VERSION ""

NS_ :

BS_:

BU_: CHUD_LS VKM_LS RCRM_LS MSM_RR_LS MSM_LR_LS CGM_LS BSM_LS VPM_LS ISRVM_LS DCAC_LS TouchPad_LS RSC_LS LVMPC_LS EOCM2B_K1_LS EOCM2A_K1_LS LCM_LS TIM_B_LS V2V_LS TCP_LS CSM_LS EOCM2B_K2_LS EOCM2A_K2_LS TIM_A_LS LVMNav_LS HFP_LS EDI_LS ARB_LS RSE_LS Dummy_LS VIS2_LS ICS_LS FCM_LS EOCM_F_LS VICM_LS AGC_LS MSM_P_LS OTIM_LS HVSM_R_LS HVSM_F_LS DVB_T_LS SBZA_R_LS PSD_R_LS PSD_L_LS UHP_Low UPA_LS STC_LS SBZA_L_LS PTM_LS ONSTAR_LS APA_LS TestTool_LS PHS_LS PDIM_LS CHM_LS RSA_LS AMP_LS HUD_LS MSM_LS HBSM_LS SCL_LS ECC_LS RadioHead_LS PEPS_LS IPC_LS AOS_LS SDM_LS TIM_LS BCM_LS

BO_ 2154905600 Driver_Identifier_LS: 1 BCM_LS
 SG_ DrvSeatPrsMemID : 5|3@0+ (1,0) [0|7] ""  CSM_LS,ONSTAR_LS,EOCM2B_K2_LS,EOCM2A_K2_LS,CGM_LS,EDI_LS,IPC_LS,CHUD_LS,HUD_LS,MSM_P_LS,MSM_LS
 SG_ DrId : 2|3@0+ (1,0) [0|7] ""  TCP_LS,EOCM2B_K2_LS,EOCM2A_K2_LS,CGM_LS,VIS2_LS,EDI_LS,LVMNav_LS,FCM_LS,EOCM_F_LS,ONSTAR_LS,CSM_LS,RadioHead_LS,ECC_LS,IPC_LS,MSM_P_LS,MSM_LS

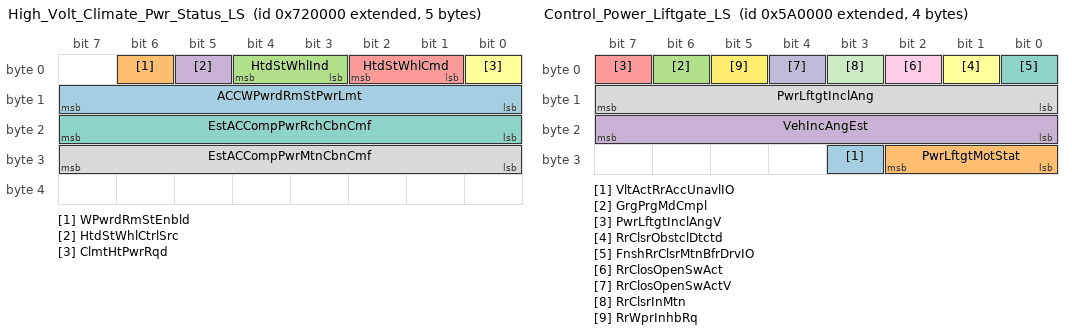
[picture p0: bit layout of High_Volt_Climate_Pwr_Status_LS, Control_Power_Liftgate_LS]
BO_ 2154954752 High_Volt_Climate_Pwr_Status_LS: 5 ECC_LS
 SG_ ACCWPwrdRmStPwrLmt : 15|8@0+ (0.1,0) [0|25.5] "kW"  VICM_LS,CGM_LS
 SG_ WPwrdRmStEnbld : 6|1@0+ (1,0) [0|1] ""  VICM_LS,CGM_LS
 SG_ HtdStWhlInd : 4|2@0+ (1,0) [0|3] ""  CGM_LS,EOCM2B_K2_LS
 SG_ HtdStWhlCtrlSrc : 5|1@0+ (1,0) [0|1] ""  CGM_LS,EOCM2B_K2_LS
 SG_ HtdStWhlCmd : 2|2@0+ (1,0) [0|3] ""  CGM_LS,EOCM2B_K2_LS
 SG_ ClmtHtPwrRqd : 0|1@0+ (1,0) [0|1] ""  CGM_LS,VICM_LS
 SG_ EstACCompPwrRchCbnCmf : 23|8@0+ (0.04,0) [0|10.2] "kw"  CGM_LS,BSM_LS,VICM_LS,CSM_LS,RadioHead_LS
 SG_ EstACCompPwrMtnCbnCmf : 31|8@0+ (0.04,0) [0|10.2] "kW"  CGM_LS,BSM_LS,VICM_LS,CSM_LS,RadioHead_LS

BO_ 2153381888 Control_Power_Liftgate_LS: 4 PTM_LS
 SG_ VltActRrAccUnavlIO : 27|1@0+ (1,0) [0|1] ""  CGM_LS,IPC_LS
 SG_ PwrLftgtMotStat : 26|3@0+ (1,0) [0|7] ""  CSM_LS,IPC_LS,CGM_LS,RadioHead_LS,ECC_LS,Dummy_LS
 SG_ GrgPrgMdCmpl : 6|1@0+ (1,0) [0|1] ""  CSM_LS,CGM_LS,RadioHead_LS,BCM_LS
 SG_ VehIncAngEst : 23|8@0+ (1,0) [0|255] "deg"  CSM_LS,CGM_LS,RadioHead_LS,PSD_R_LS,PSD_L_LS
 SG_ PwrLftgtInclAngV : 7|1@0+ (1,0) [0|1] ""  CSM_LS,CGM_LS,RadioHead_LS,TIM_B_LS,TIM_A_LS,TIM_LS
 SG_ RrClsrObstclDtctd : 1|1@0+ (1,0) [0|1] ""  CSM_LS,CGM_LS,RadioHead_LS,BCM_LS
 SG_ FnshRrClsrMtnBfrDrvIO : 0|1@0+ (1,0) [0|1] ""  CSM_LS,CGM_LS,RadioHead_LS,IPC_LS
 SG_ PwrLftgtInclAng : 15|8@0+ (1,0) [0|255] ""  CSM_LS,CGM_LS,RadioHead_LS,TIM_B_LS,TIM_A_LS,TIM_LS
 SG_ RrClosOpenSwAct : 2|1@0+ (1,0) [0|1] ""  VKM_LS,CSM_LS,CGM_LS,ARB_LS,RadioHead_LS,IPC_LS,BCM_LS
 SG_ RrClosOpenSwActV : 4|1@0+ (1,0) [0|1] ""  CSM_LS,CGM_LS,ARB_LS,RadioHead_LS,IPC_LS,BCM_LS
 SG_ RrClsrInMtn : 3|1@0+ (1,0) [0|1] ""  CSM_LS,CGM_LS,RadioHead_LS,BCM_LS
 SG_ RrWprInhbRq : 5|1@0+ (1,0) [0|1] ""  CSM_LS,CGM_LS,RadioHead_LS,BCM_LS

BO_ 2149752832 Chassis_Information_LS: 8 BCM_LS
 SG_ SndEnhcmtPerfMdRq : 55|3@0+ (1,0) [0|7] ""  CSM_LS,CGM_LS,RadioHead_LS,IPC_LS
 SG_ SndPerfMdCsStAvl : 63|1@0+ (1,0) [0|1] ""  CGM_LS,CSM_LS,RadioHead_LS
 SG_ SndPerfMdCsCrStVal : 62|3@0+ (1,0) [0|7] ""  CGM_LS,CSM_LS,RadioHead_LS
 SG_ DispPerfMdCsStAvl : 59|1@0+ (1,0) [0|1] ""  CGM_LS,CSM_LS,RadioHead_LS
 SG_ DispPerfMdCsCrStVal : 58|3@0+ (1,0) [0|7] ""  CGM_LS,CSM_LS,RadioHead_LS
 SG_ HlStrAssActIO : 41|1@0+ (1,0) [0|1] ""  CSM_LS,CGM_LS,RadioHead_LS,IPC_LS
 SG_ GNCustSetngAvlbl : 44|1@0+ (1,0) [0|1] ""  CGM_LS,IPC_LS,CSM_LS,RadioHead_LS
 SG_ GNCustCrntStngVal : 47|3@0+ (1,0) [0|7] ""  CGM_LS,IPC_LS,CSM_LS,RadioHead_LS
 SG_ CPSInfotmntMtReq : 49|2@0+ (1,0) [0|3] ""  CSM_LS,CGM_LS,RadioHead_LS
 SG_ ColPrSysStngAvl : 42|1@0+ (1,0) [0|1] ""  CGM_LS,CSM_LS,RadioHead_LS
 SG_ ColPrSysCrntStng : 52|3@0+ (1,0) [0|7] ""  CGM_LS,CSM_LS,RadioHead_LS
 SG_ HillDscntCntlSysStat : 37|3@0+ (1,0) [0|7] ""  CSM_LS,CGM_LS,RadioHead_LS,IPC_LS
 SG_ ElecPrkBrkStat : 39|2@0+ (1,0) [0|3] ""  ONSTAR_LS,TCP_LS,CSM_LS,MSM_P_LS,MSM_LS,V2V_LS,CGM_LS,RadioHead_LS,SBZA_R_LS,SBZA_L_LS,LVMNav_LS,UPA_LS,APA_LS
 SG_ EBDFailed : 31|1@0+ (1,0) [0|1] ""  CSM_LS,CGM_LS,RadioHead_LS,IPC_LS
 SG_ SusCustStngAvlbl : 30|1@0+ (1,0) [0|1] ""  CGM_LS,CSM_LS,RadioHead_LS
 SG_ SusCustCurrStngVal : 34|3@0+ (1,0) [0|7] ""  CGM_LS,CSM_LS,RadioHead_LS
 SG_ StrCustStngAvlbl : 7|1@0+ (1,0) [0|1] ""  CGM_LS,CSM_LS,RadioHead_LS
 SG_ StrCustCurrStngVal : 29|3@0+ (1,0) [0|7] ""  CGM_LS,CSM_LS,RadioHead_LS
 SG_ DrvlnCustStngAvlbl : 6|1@0+ (1,0) [0|1] ""  CGM_LS,CSM_LS,RadioHead_LS
 SG_ DrvlnCustCurrStngVal : 26|3@0+ (1,0) [0|7] ""  CGM_LS,CSM_LS,RadioHead_LS
 SG_ ABSAtv : 5|1@0+ (1,0) [0|1] ""  CSM_LS,CGM_LS,SDM_LS,VIS2_LS,RadioHead_LS,FCM_LS,IPC_LS,UPA_LS,APA_LS
 SG_ PowStVDA : 13|1@0+ (1,0) [0|1] ""  CGM_LS,CSM_LS,RadioHead_LS,IPC_LS
 SG_ RrDrCntVDA : 14|1@0+ (1,0) [0|1] ""  CGM_LS,CSM_LS,IPC_LS,RadioHead_LS
 SG_ SprTireSt : 18|3@0+ (1,0) [0|7] ""  VPM_LS,CSM_LS,CGM_LS,RadioHead_LS,UPA_LS,APA_LS
 SG_ VehHghtStatV : 0|1@0+ (1,0) [0|1] ""  VPM_LS,CSM_LS,CGM_LS,RadioHead_LS,IPC_LS
 SG_ VehHghtStat : 11|4@0+ (1,0) [0|15] ""  VPM_LS,CSM_LS,CGM_LS,RadioHead_LS,IPC_LS
 SG_ BrkSysVDA : 15|1@0+ (1,0) [0|1] ""  TCP_LS,CGM_LS,CSM_LS,VIS2_LS,LCM_LS,PTM_LS,ONSTAR_LS,FCM_LS,RadioHead_LS,UPA_LS,APA_LS,IPC_LS
 SG_ IntBrkAssPreFilReq : 1|1@0+ (1,0) [0|1] "N/A"  CSM_LS,CGM_LS,RadioHead_LS,IPC_LS
 SG_ EPBSysDspMsgReq : 23|3@0+ (1,0) [0|7] ""  CSM_LS,CGM_LS,RadioHead_LS,IPC_LS
 SG_ EPBSysAudWarnReq : 20|2@0+ (1,0) [0|3] ""  CSM_LS,CGM_LS,RadioHead_LS,IPC_LS
 SG_ BksOvht : 2|1@0+ (1,0) [0|1] ""  CSM_LS,TCP_LS,CGM_LS,RadioHead_LS,ONSTAR_LS,IPC_LS
 SG_ BrkSysRedBrkTlltlReq : 4|1@0+ (1,0) [0|1] ""  CSM_LS,CGM_LS,RadioHead_LS,IPC_LS
 SG_ HalfSysFail : 3|1@0+ (1,0) [0|1] ""  CSM_LS,CGM_LS,RadioHead_LS,IPC_LS
 SG_ PrkBrkVDA : 12|1@0+ (1,0) [0|1] ""  CGM_LS,CSM_LS,RadioHead_LS,IPC_LS,UPA_LS,APA_LS

BO_ 2151514112 Reset_OilLife_Request_LS: 1 IPC_LS
 SG_ EngOilLfRstRq : 0|1@0+ (1,0) [0|1] ""  BCM_LS

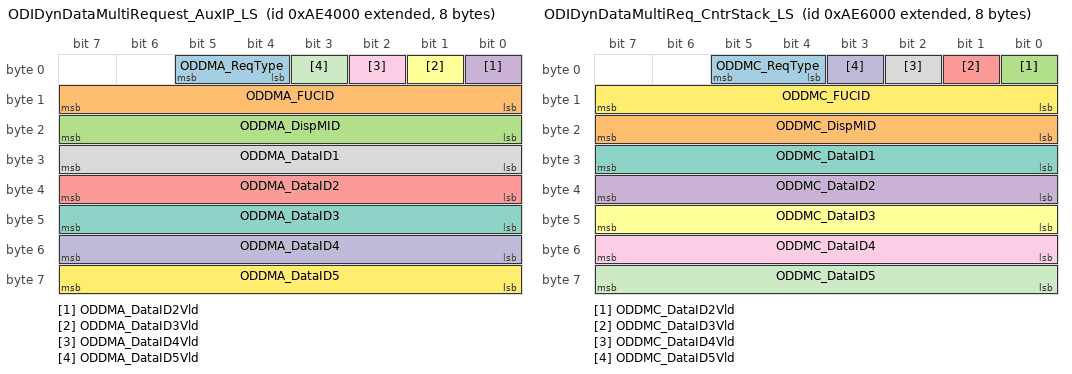
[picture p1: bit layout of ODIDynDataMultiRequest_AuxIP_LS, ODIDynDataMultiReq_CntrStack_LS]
BO_ 2158903296 ODIDynDataMultiRequest_AuxIP_LS: 8 CGM_LS
 SG_ ODDMA_ReqType : 5|2@0+ (1,0) [0|3] ""  EOCM2B_K2_LS,EOCM2A_K2_LS,SBZA_L_LS,VIS2_LS,FCM_LS,EOCM_F_LS,UPA_LS,BCM_LS,IPC_LS,ECC_LS,MSM_P_LS,MSM_LS,APA_LS,RadioHead_LS,UHP_Low,ONSTAR_LS
 SG_ ODDMA_FUCID : 15|8@0+ (1,0) [0|255] ""  EOCM2B_K2_LS,EOCM2A_K2_LS,SBZA_L_LS,VIS2_LS,FCM_LS,EOCM_F_LS,UPA_LS,BCM_LS,IPC_LS,ECC_LS,MSM_P_LS,MSM_LS,APA_LS,RadioHead_LS,UHP_Low,ONSTAR_LS
 SG_ ODDMA_DispMID : 23|8@0+ (1,0) [0|255] ""  EOCM2B_K2_LS,EOCM2A_K2_LS,SBZA_L_LS,VIS2_LS,FCM_LS,EOCM_F_LS,UPA_LS,BCM_LS,IPC_LS,ECC_LS,MSM_P_LS,MSM_LS,APA_LS,RadioHead_LS,UHP_Low,ONSTAR_LS
 SG_ ODDMA_DataID2Vld : 0|1@0+ (1,0) [0|1] ""  EOCM2B_K2_LS,EOCM2A_K2_LS,SBZA_L_LS,VIS2_LS,FCM_LS,EOCM_F_LS,UPA_LS,BCM_LS,IPC_LS,ECC_LS,MSM_P_LS,MSM_LS,APA_LS,RadioHead_LS,UHP_Low,ONSTAR_LS
 SG_ ODDMA_DataID2 : 39|8@0+ (1,0) [0|255] ""  EOCM2B_K2_LS,EOCM2A_K2_LS,SBZA_L_LS,VIS2_LS,FCM_LS,EOCM_F_LS,UPA_LS,BCM_LS,IPC_LS,ECC_LS,MSM_P_LS,MSM_LS,APA_LS,RadioHead_LS,UHP_Low,ONSTAR_LS
 SG_ ODDMA_DataID3Vld : 1|1@0+ (1,0) [0|1] ""  EOCM2B_K2_LS,EOCM2A_K2_LS,SBZA_L_LS,VIS2_LS,FCM_LS,EOCM_F_LS,UPA_LS,BCM_LS,IPC_LS,ECC_LS,MSM_P_LS,MSM_LS,APA_LS,RadioHead_LS,UHP_Low,ONSTAR_LS
 SG_ ODDMA_DataID3 : 47|8@0+ (1,0) [0|255] ""  EOCM2B_K2_LS,EOCM2A_K2_LS,SBZA_L_LS,VIS2_LS,FCM_LS,EOCM_F_LS,UPA_LS,BCM_LS,IPC_LS,ECC_LS,MSM_P_LS,MSM_LS,APA_LS,RadioHead_LS,UHP_Low,ONSTAR_LS
 SG_ ODDMA_DataID1 : 31|8@0+ (1,0) [0|255] ""  EOCM2B_K2_LS,EOCM2A_K2_LS,SBZA_L_LS,VIS2_LS,FCM_LS,EOCM_F_LS,UPA_LS,BCM_LS,IPC_LS,ECC_LS,MSM_P_LS,MSM_LS,APA_LS,RadioHead_LS,UHP_Low,ONSTAR_LS
 SG_ ODDMA_DataID4Vld : 2|1@0+ (1,0) [0|1] ""  EOCM2B_K2_LS,EOCM2A_K2_LS,SBZA_L_LS,VIS2_LS,FCM_LS,EOCM_F_LS,UPA_LS,BCM_LS,IPC_LS,ECC_LS,MSM_P_LS,MSM_LS,APA_LS,RadioHead_LS,UHP_Low,ONSTAR_LS
 SG_ ODDMA_DataID4 : 55|8@0+ (1,0) [0|255] ""  EOCM2B_K2_LS,EOCM2A_K2_LS,SBZA_L_LS,VIS2_LS,FCM_LS,EOCM_F_LS,UPA_LS,BCM_LS,IPC_LS,ECC_LS,MSM_P_LS,MSM_LS,APA_LS,RadioHead_LS,UHP_Low,ONSTAR_LS
 SG_ ODDMA_DataID5Vld : 3|1@0+ (1,0) [0|1] ""  EOCM2B_K2_LS,EOCM2A_K2_LS,SBZA_L_LS,VIS2_LS,FCM_LS,EOCM_F_LS,UPA_LS,BCM_LS,IPC_LS,ECC_LS,MSM_P_LS,MSM_LS,APA_LS,RadioHead_LS,UHP_Low,ONSTAR_LS
 SG_ ODDMA_DataID5 : 63|8@0+ (1,0) [0|255] ""  EOCM2B_K2_LS,EOCM2A_K2_LS,SBZA_L_LS,VIS2_LS,FCM_LS,EOCM_F_LS,UPA_LS,BCM_LS,IPC_LS,ECC_LS,MSM_P_LS,MSM_LS,APA_LS,RadioHead_LS,UHP_Low,ONSTAR_LS

BO_ 2158911488 ODIDynDataMultiReq_CntrStack_LS: 8 CGM_LS
 SG_ ODDMC_ReqType : 5|2@0+ (1,0) [0|3] ""  EOCM2B_K2_LS,EOCM2A_K2_LS,TCP_LS,SBZA_L_LS,VIS2_LS,FCM_LS,PDIM_LS,EOCM_F_LS,UPA_LS,BCM_LS,ECC_LS,MSM_P_LS,MSM_LS,APA_LS,UHP_Low,ONSTAR_LS
 SG_ ODDMC_DispMID : 23|8@0+ (1,0) [0|255] ""  EOCM2B_K2_LS,EOCM2A_K2_LS,TCP_LS,SBZA_L_LS,VIS2_LS,FCM_LS,PDIM_LS,EOCM_F_LS,UPA_LS,BCM_LS,ECC_LS,MSM_P_LS,MSM_LS,APA_LS,UHP_Low,ONSTAR_LS
 SG_ ODDMC_DataID2Vld : 0|1@0+ (1,0) [0|1] ""  EOCM2B_K2_LS,EOCM2A_K2_LS,TCP_LS,SBZA_L_LS,VIS2_LS,FCM_LS,PDIM_LS,EOCM_F_LS,UPA_LS,BCM_LS,ECC_LS,MSM_P_LS,MSM_LS,APA_LS,UHP_Low,ONSTAR_LS
 SG_ ODDMC_DataID2 : 39|8@0+ (1,0) [0|255] ""  EOCM2B_K2_LS,EOCM2A_K2_LS,TCP_LS,SBZA_L_LS,VIS2_LS,FCM_LS,PDIM_LS,EOCM_F_LS,UPA_LS,BCM_LS,ECC_LS,MSM_P_LS,MSM_LS,APA_LS,UHP_Low,ONSTAR_LS
 SG_ ODDMC_DataID3Vld : 1|1@0+ (1,0) [0|1] ""  EOCM2B_K2_LS,EOCM2A_K2_LS,TCP_LS,SBZA_L_LS,VIS2_LS,FCM_LS,PDIM_LS,EOCM_F_LS,UPA_LS,BCM_LS,ECC_LS,MSM_P_LS,MSM_LS,APA_LS,UHP_Low,ONSTAR_LS
 SG_ ODDMC_DataID3 : 47|8@0+ (1,0) [0|255] ""  EOCM2B_K2_LS,EOCM2A_K2_LS,TCP_LS,SBZA_L_LS,VIS2_LS,FCM_LS,PDIM_LS,EOCM_F_LS,UPA_LS,BCM_LS,ECC_LS,MSM_P_LS,MSM_LS,APA_LS,UHP_Low,ONSTAR_LS
 SG_ ODDMC_DataID1 : 31|8@0+ (1,0) [0|255] ""  EOCM2B_K2_LS,EOCM2A_K2_LS,TCP_LS,SBZA_L_LS,VIS2_LS,FCM_LS,PDIM_LS,EOCM_F_LS,UPA_LS,BCM_LS,ECC_LS,MSM_P_LS,MSM_LS,APA_LS,UHP_Low,ONSTAR_LS
 SG_ ODDMC_DataID4Vld : 2|1@0+ (1,0) [0|1] ""  EOCM2B_K2_LS,EOCM2A_K2_LS,TCP_LS,SBZA_L_LS,VIS2_LS,FCM_LS,PDIM_LS,EOCM_F_LS,UPA_LS,BCM_LS,ECC_LS,MSM_P_LS,MSM_LS,APA_LS,UHP_Low,ONSTAR_LS
 SG_ ODDMC_DataID4 : 55|8@0+ (1,0) [0|255] ""  EOCM2B_K2_LS,EOCM2A_K2_LS,TCP_LS,SBZA_L_LS,VIS2_LS,FCM_LS,PDIM_LS,EOCM_F_LS,UPA_LS,BCM_LS,ECC_LS,MSM_P_LS,MSM_LS,APA_LS,UHP_Low,ONSTAR_LS
 SG_ ODDMC_DataID5Vld : 3|1@0+ (1,0) [0|1] ""  EOCM2B_K2_LS,EOCM2A_K2_LS,TCP_LS,SBZA_L_LS,VIS2_LS,FCM_LS,PDIM_LS,EOCM_F_LS,UPA_LS,BCM_LS,ECC_LS,MSM_P_LS,MSM_LS,APA_LS,UHP_Low,ONSTAR_LS
 SG_ ODDMC_DataID5 : 63|8@0+ (1,0) [0|255] ""  EOCM2B_K2_LS,EOCM2A_K2_LS,TCP_LS,SBZA_L_LS,VIS2_LS,FCM_LS,PDIM_LS,EOCM_F_LS,UPA_LS,BCM_LS,ECC_LS,MSM_P_LS,MSM_LS,APA_LS,UHP_Low,ONSTAR_LS
 SG_ ODDMC_FUCID : 15|8@0+ (1,0) [0|255] ""  EOCM2B_K2_LS,EOCM2A_K2_LS,TCP_LS,SBZA_L_LS,VIS2_LS,FCM_LS,PDIM_LS,EOCM_F_LS,UPA_LS,BCM_LS,ECC_LS,MSM_P_LS,MSM_LS,APA_LS,UHP_Low,ONSTAR_LS

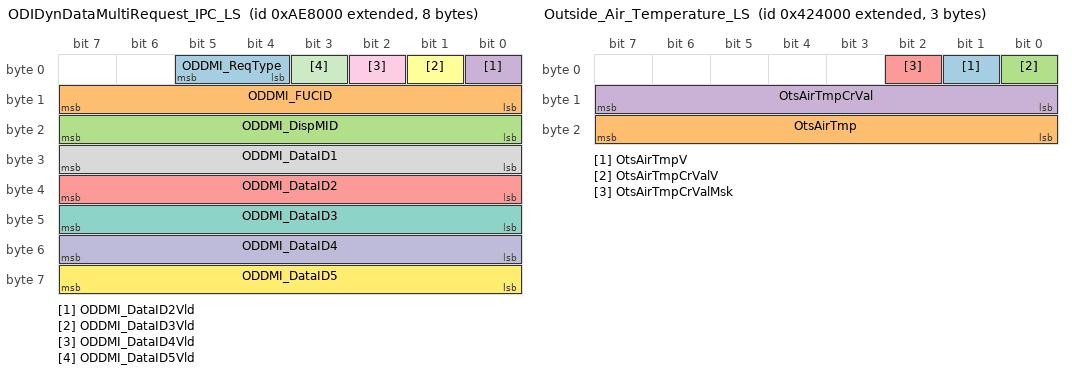
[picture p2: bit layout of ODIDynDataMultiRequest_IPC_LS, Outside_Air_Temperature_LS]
BO_ 2158919680 ODIDynDataMultiRequest_IPC_LS: 8 CGM_LS
 SG_ ODDMI_ReqType : 5|2@0+ (1,0) [0|3] ""  EOCM2B_K2_LS,EOCM2A_K2_LS,TCP_LS,SBZA_L_LS,VIS2_LS,FCM_LS,EOCM_F_LS,UPA_LS,BCM_LS,ECC_LS,MSM_P_LS,MSM_LS,APA_LS,RadioHead_LS,UHP_Low,ONSTAR_LS
 SG_ ODDMI_FUCID : 15|8@0+ (1,0) [0|255] ""  EOCM2B_K2_LS,EOCM2A_K2_LS,TCP_LS,SBZA_L_LS,VIS2_LS,FCM_LS,EOCM_F_LS,UPA_LS,BCM_LS,ECC_LS,MSM_P_LS,MSM_LS,APA_LS,RadioHead_LS,UHP_Low,ONSTAR_LS
 SG_ ODDMI_DispMID : 23|8@0+ (1,0) [0|255] ""  EOCM2B_K2_LS,EOCM2A_K2_LS,TCP_LS,SBZA_L_LS,VIS2_LS,FCM_LS,EOCM_F_LS,UPA_LS,BCM_LS,ECC_LS,MSM_P_LS,MSM_LS,APA_LS,RadioHead_LS,UHP_Low,ONSTAR_LS
 SG_ ODDMI_DataID2Vld : 0|1@0+ (1,0) [0|1] ""  EOCM2B_K2_LS,EOCM2A_K2_LS,TCP_LS,SBZA_L_LS,VIS2_LS,FCM_LS,EOCM_F_LS,UPA_LS,BCM_LS,ECC_LS,MSM_P_LS,MSM_LS,APA_LS,RadioHead_LS,UHP_Low,ONSTAR_LS
 SG_ ODDMI_DataID2 : 39|8@0+ (1,0) [0|255] ""  EOCM2B_K2_LS,EOCM2A_K2_LS,TCP_LS,SBZA_L_LS,VIS2_LS,FCM_LS,EOCM_F_LS,UPA_LS,BCM_LS,ECC_LS,MSM_P_LS,MSM_LS,APA_LS,RadioHead_LS,UHP_Low,ONSTAR_LS
 SG_ ODDMI_DataID3Vld : 1|1@0+ (1,0) [0|1] ""  EOCM2B_K2_LS,EOCM2A_K2_LS,TCP_LS,SBZA_L_LS,VIS2_LS,FCM_LS,EOCM_F_LS,UPA_LS,BCM_LS,ECC_LS,MSM_P_LS,MSM_LS,APA_LS,RadioHead_LS,UHP_Low,ONSTAR_LS
 SG_ ODDMI_DataID3 : 47|8@0+ (1,0) [0|255] ""  EOCM2B_K2_LS,EOCM2A_K2_LS,TCP_LS,SBZA_L_LS,VIS2_LS,FCM_LS,EOCM_F_LS,UPA_LS,BCM_LS,ECC_LS,MSM_P_LS,MSM_LS,APA_LS,RadioHead_LS,UHP_Low,ONSTAR_LS
 SG_ ODDMI_DataID1 : 31|8@0+ (1,0) [0|255] ""  EOCM2B_K2_LS,EOCM2A_K2_LS,TCP_LS,SBZA_L_LS,VIS2_LS,FCM_LS,EOCM_F_LS,UPA_LS,BCM_LS,ECC_LS,MSM_P_LS,MSM_LS,APA_LS,RadioHead_LS,UHP_Low,ONSTAR_LS
 SG_ ODDMI_DataID4Vld : 2|1@0+ (1,0) [0|1] ""  EOCM2B_K2_LS,EOCM2A_K2_LS,TCP_LS,SBZA_L_LS,VIS2_LS,FCM_LS,EOCM_F_LS,UPA_LS,BCM_LS,ECC_LS,MSM_P_LS,MSM_LS,APA_LS,RadioHead_LS,UHP_Low,ONSTAR_LS
 SG_ ODDMI_DataID4 : 55|8@0+ (1,0) [0|255] ""  EOCM2B_K2_LS,EOCM2A_K2_LS,TCP_LS,SBZA_L_LS,VIS2_LS,FCM_LS,EOCM_F_LS,UPA_LS,BCM_LS,ECC_LS,MSM_P_LS,MSM_LS,APA_LS,RadioHead_LS,UHP_Low,ONSTAR_LS
 SG_ ODDMI_DataID5Vld : 3|1@0+ (1,0) [0|1] ""  EOCM2B_K2_LS,EOCM2A_K2_LS,TCP_LS,SBZA_L_LS,VIS2_LS,FCM_LS,EOCM_F_LS,UPA_LS,BCM_LS,ECC_LS,MSM_P_LS,MSM_LS,APA_LS,RadioHead_LS,UHP_Low,ONSTAR_LS
 SG_ ODDMI_DataID5 : 63|8@0+ (1,0) [0|255] ""  EOCM2B_K2_LS,EOCM2A_K2_LS,TCP_LS,SBZA_L_LS,VIS2_LS,FCM_LS,EOCM_F_LS,UPA_LS,BCM_LS,ECC_LS,MSM_P_LS,MSM_LS,APA_LS,RadioHead_LS,UHP_Low,ONSTAR_LS

BO_ 2151825408 Outside_Air_Temperature_LS: 3 IPC_LS
 SG_ OtsAirTmpV : 1|1@0+ (1,0) [0|1] ""  LVMPC_LS,EOCM2B_K1_LS,EOCM2A_K1_LS,RSE_LS,EOCM2A_K2_LS,EOCM2B_K2_LS,EOCM_F_LS,LVMNav_LS,HFP_LS,EDI_LS,RadioHead_LS,CGM_LS,UPA_LS,BCM_LS,APA_LS,PHS_LS,ECC_LS
 SG_ OtsAirTmp : 23|8@0+ (0.5,-40) [-40|87.5] "deg C"  LVMPC_LS,EOCM2B_K1_LS,EOCM2A_K1_LS,RSE_LS,EOCM2A_K2_LS,EOCM2B_K2_LS,EOCM_F_LS,LVMNav_LS,HFP_LS,EDI_LS,RadioHead_LS,CGM_LS,UPA_LS,ICS_LS,BCM_LS,APA_LS,PHS_LS,ECC_LS
 SG_ OtsAirTmpCrValV : 0|1@0+ (1,0) [0|1] ""  EOCM2B_K1_LS,EOCM2A_K1_LS,EOCM2A_K2_LS,EOCM2B_K2_LS,EOCM_F_LS,VIS2_LS,LVMNav_LS,EDI_LS,ARB_LS,CGM_LS,SDM_LS,PSD_R_LS,PSD_L_LS,FCM_LS,RadioHead_LS,UPA_LS,APA_LS,LCM_LS,PTM_LS,BCM_LS,ECC_LS
 SG_ OtsAirTmpCrVal : 15|8@0+ (0.5,-40) [-40|87.5] "deg C"  EOCM2B_K1_LS,EOCM2A_K1_LS,EOCM2A_K2_LS,EOCM2B_K2_LS,EOCM_F_LS,VIS2_LS,LVMNav_LS,EDI_LS,ARB_LS,CGM_LS,SDM_LS,PSD_R_LS,PSD_L_LS,FCM_LS,RadioHead_LS,LCM_LS,PTM_LS,BCM_LS,UPA_LS,APA_LS,ECC_LS
 SG_ OtsAirTmpCrValMsk : 2|1@0+ (1,0) [0|1] ""  EOCM2B_K1_LS,EOCM2A_K1_LS,EOCM2A_K2_LS,EOCM2B_K2_LS,EOCM_F_LS,VIS2_LS,RadioHead_LS,LVMNav_LS,ARB_LS,EDI_LS,CGM_LS,SDM_LS,PSD_R_LS,PSD_L_LS,UPA_LS,APA_LS,BCM_LS,LCM_LS,PTM_LS,ECC_LS,FCM_LS

BO_ 2151153664 Rear_Window_Defog_Status_LS: 1 ECC_LS
 SG_ RrWndDfgOn : 0|1@0+ (1,0) [0|1] ""  CGM_LS,CSM_LS,RadioHead_LS,IPC_LS,BCM_LS

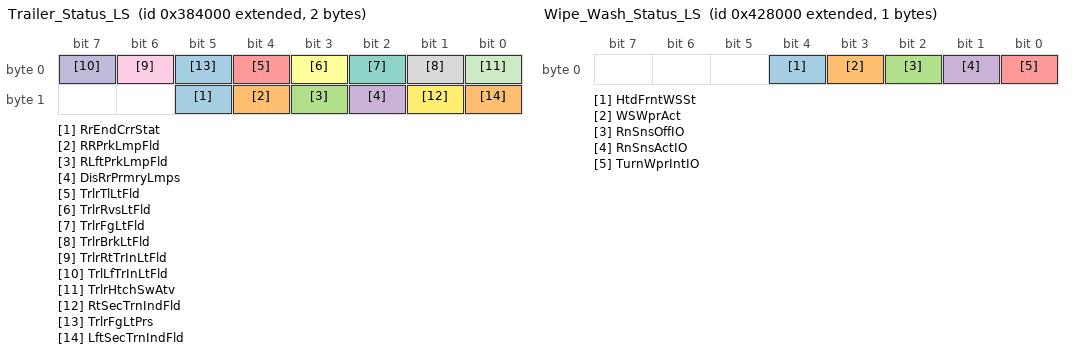
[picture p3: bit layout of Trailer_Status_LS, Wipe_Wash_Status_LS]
BO_ 2151170048 Trailer_Status_LS: 2 TIM_LS
 SG_ RrEndCrrStat : 13|1@0+ (1,0) [0|1] ""  EOCM2B_K1_LS,EOCM2A_K1_LS,CSM_LS,CGM_LS,UPA_LS,APA_LS,RadioHead_LS,BCM_LS
 SG_ RRPrkLmpFld : 12|1@0+ (1,0) [0|1] ""  EOCM2B_K1_LS,EOCM2A_K1_LS,CSM_LS,CGM_LS,RadioHead_LS,IPC_LS
 SG_ RLftPrkLmpFld : 11|1@0+ (1,0) [0|1] ""  EOCM2B_K1_LS,EOCM2A_K1_LS,CSM_LS,CGM_LS,RadioHead_LS,IPC_LS
 SG_ DisRrPrmryLmps : 10|1@0+ (1,0) [0|1] ""  EOCM2B_K1_LS,EOCM2A_K1_LS,CSM_LS,CGM_LS,RadioHead_LS,BCM_LS
 SG_ TrlrTlLtFld : 4|1@0+ (1,0) [0|1] ""  EOCM2B_K1_LS,EOCM2A_K1_LS,CSM_LS,CGM_LS,RadioHead_LS,IPC_LS
 SG_ TrlrRvsLtFld : 3|1@0+ (1,0) [0|1] ""  EOCM2B_K1_LS,EOCM2A_K1_LS,CSM_LS,CGM_LS,RadioHead_LS,IPC_LS
 SG_ TrlrFgLtFld : 2|1@0+ (1,0) [0|1] ""  EOCM2B_K1_LS,EOCM2A_K1_LS,CSM_LS,CGM_LS,RadioHead_LS,IPC_LS
 SG_ TrlrBrkLtFld : 1|1@0+ (1,0) [0|1] ""  EOCM2B_K1_LS,EOCM2A_K1_LS,CSM_LS,CGM_LS,RadioHead_LS,IPC_LS
 SG_ TrlrRtTrInLtFld : 6|1@0+ (1,0) [0|1] ""  EOCM2B_K1_LS,EOCM2A_K1_LS,CSM_LS,CGM_LS,RadioHead_LS,IPC_LS,BCM_LS
 SG_ TrlLfTrInLtFld : 7|1@0+ (1,0) [0|1] ""  EOCM2B_K1_LS,EOCM2A_K1_LS,CSM_LS,CGM_LS,RadioHead_LS,BCM_LS,IPC_LS
 SG_ TrlrHtchSwAtv : 0|1@0+ (1,0) [0|1] ""  VIS2_LS,EOCM2B_K1_LS,EOCM2A_K1_LS,CSM_LS,CGM_LS,FCM_LS,RadioHead_LS,EOCM_F_LS,LCM_LS,PTM_LS,UPA_LS,APA_LS,BCM_LS
 SG_ RtSecTrnIndFld : 9|1@0+ (1,0) [0|1] ""  EOCM2B_K1_LS,EOCM2A_K1_LS,CSM_LS,CGM_LS,RadioHead_LS,BCM_LS
 SG_ TrlrFgLtPrs : 5|1@0+ (1,0) [0|1] ""  EOCM2B_K1_LS,EOCM2A_K1_LS,CSM_LS,CGM_LS,RadioHead_LS,BCM_LS
 SG_ LftSecTrnIndFld : 8|1@0+ (1,0) [0|1] ""  EOCM2B_K1_LS,EOCM2A_K1_LS,CSM_LS,CGM_LS,RadioHead_LS,BCM_LS

BO_ 2151841792 Wipe_Wash_Status_LS: 1 BCM_LS
 SG_ HtdFrntWSSt : 4|1@0+ (1,0) [0|1] ""  CGM_LS,IPC_LS
 SG_ WSWprAct : 3|1@0+ (1,0) [0|1] ""  EOCM2B_K2_LS,EOCM2A_K2_LS,V2V_LS,CGM_LS,CSM_LS,VIS2_LS,SBZA_L_LS,SBZA_R_LS,RadioHead_LS,FCM_LS
 SG_ RnSnsOffIO : 2|1@0+ (1,0) [0|1] ""  CSM_LS,EOCM2B_K2_LS,EOCM2A_K2_LS,CGM_LS,SBZA_L_LS,SBZA_R_LS,RadioHead_LS,IPC_LS
 SG_ RnSnsActIO : 1|1@0+ (1,0) [0|1] ""  CSM_LS,EOCM2B_K2_LS,EOCM2A_K2_LS,CGM_LS,SBZA_L_LS,SBZA_R_LS,RadioHead_LS,IPC_LS
 SG_ TurnWprIntIO : 0|1@0+ (1,0) [0|1] ""  CSM_LS,EOCM2B_K2_LS,EOCM2A_K2_LS,CGM_LS,SBZA_L_LS,SBZA_R_LS,RadioHead_LS,IPC_LS

BO_ 2154995712 Air_Conditioning_Comp_Type_LS: 1 ECC_LS
 SG_ HVHtrFldIO : 4|1@0+ (1,0) [0|1] ""  CGM_LS,IPC_LS
 SG_ HVHtrOvrTmpIndOn : 3|1@0+ (1,0) [0|1] ""  CSM_LS,ONSTAR_LS,CGM_LS,IPC_LS

BO_ 2154094592 Adjustable_Pedal_Motion_Inh_LS: 8 BCM_LS
 SG_ IntDimSeldClrTypStVal : 12|5@0+ (1,0) [0|31] ""  CGM_LS,CSM_LS,RadioHead_LS
 SG_ IntDimSeldAnmTypStVal : 4|4@0+ (1,0) [0|15] ""  CGM_LS,CSM_LS,RadioHead_LS
 SG_ IDCTA_ClrTyp30Avl : 56|1@0+ (1,0) [0|1] ""  CGM_LS,CSM_LS,RadioHead_LS
 SG_ IDCTA_ClrTyp29Avl : 57|1@0+ (1,0) [0|1] ""  CGM_LS,CSM_LS,RadioHead_LS
 SG_ IDCTA_ClrTyp28Avl : 58|1@0+ (1,0) [0|1] ""  CGM_LS,CSM_LS,RadioHead_LS
 SG_ IDCTA_ClrTyp27Avl : 59|1@0+ (1,0) [0|1] ""  CGM_LS,CSM_LS,RadioHead_LS
 SG_ IDCTA_ClrTyp26Avl : 60|1@0+ (1,0) [0|1] ""  CGM_LS,CSM_LS,RadioHead_LS
 SG_ IDCTA_ClrTyp25Avl : 61|1@0+ (1,0) [0|1] ""  CGM_LS,CSM_LS,RadioHead_LS
 SG_ IDCTA_ClrTyp24Avl : 62|1@0+ (1,0) [0|1] ""  CGM_LS,CSM_LS,RadioHead_LS
 SG_ IDCTA_ClrTyp23Avl : 63|1@0+ (1,0) [0|1] ""  CGM_LS,CSM_LS,RadioHead_LS
 SG_ IDCTA_ClrTyp22Avl : 48|1@0+ (1,0) [0|1] ""  CGM_LS,CSM_LS,RadioHead_LS
 SG_ IDCTA_ClrTyp21Avl : 49|1@0+ (1,0) [0|1] ""  CGM_LS,CSM_LS,RadioHead_LS
 SG_ IDCTA_ClrTyp20Avl : 50|1@0+ (1,0) [0|1] ""  CGM_LS,CSM_LS,RadioHead_LS
 SG_ IDCTA_ClrTyp19Avl : 51|1@0+ (1,0) [0|1] ""  CGM_LS,CSM_LS,RadioHead_LS
 SG_ IDCTA_ClrTyp18Avl : 52|1@0+ (1,0) [0|1] ""  CGM_LS,CSM_LS,RadioHead_LS
 SG_ IDCTA_ClrTyp17Avl : 53|1@0+ (1,0) [0|1] ""  CGM_LS,CSM_LS,RadioHead_LS
 SG_ IDCTA_ClrTyp16Avl : 54|1@0+ (1,0) [0|1] ""  CGM_LS,CSM_LS,RadioHead_LS
 SG_ IDCTA_ClrTyp15Avl : 55|1@0+ (1,0) [0|1] ""  CGM_LS,CSM_LS,RadioHead_LS
 SG_ IDCTA_ClrTyp14Avl : 40|1@0+ (1,0) [0|1] ""  CGM_LS,CSM_LS,RadioHead_LS
 SG_ IDCTA_ClrTyp13Avl : 41|1@0+ (1,0) [0|1] ""  CGM_LS,CSM_LS,RadioHead_LS
 SG_ IDCTA_ClrTyp12Avl : 42|1@0+ (1,0) [0|1] ""  CGM_LS,CSM_LS,RadioHead_LS
 SG_ IDCTA_ClrTyp11Avl : 43|1@0+ (1,0) [0|1] ""  CGM_LS,CSM_LS,RadioHead_LS
 SG_ IDCTA_ClrTyp10Avl : 44|1@0+ (1,0) [0|1] ""  CGM_LS,CSM_LS,RadioHead_LS
 SG_ IDCTA_ClrTyp9Avl : 45|1@0+ (1,0) [0|1] ""  CGM_LS,CSM_LS,RadioHead_LS
 SG_ IDCTA_ClrTyp8Avl : 46|1@0+ (1,0) [0|1] ""  CGM_LS,CSM_LS,RadioHead_LS
 SG_ IDCTA_ClrTyp7Avl : 47|1@0+ (1,0) [0|1] ""  CGM_LS,CSM_LS,RadioHead_LS
 SG_ IDCTA_ClrTyp6Avl : 32|1@0+ (1,0) [0|1] ""  CGM_LS,CSM_LS,RadioHead_LS
 SG_ IDCTA_ClrTyp5Avl : 33|1@0+ (1,0) [0|1] ""  CGM_LS,CSM_LS,RadioHead_LS
 SG_ IDCTA_ClrTyp4Avl : 34|1@0+ (1,0) [0|1] ""  CGM_LS,CSM_LS,RadioHead_LS
 SG_ IDCTA_ClrTyp3Avl : 35|1@0+ (1,0) [0|1] ""  CGM_LS,CSM_LS,RadioHead_LS
 SG_ IDCTA_ClrTyp2Avl : 36|1@0+ (1,0) [0|1] ""  CGM_LS,CSM_LS,RadioHead_LS
 SG_ IDCTA_ClrTyp1Avl : 37|1@0+ (1,0) [0|1] ""  CGM_LS,CSM_LS,RadioHead_LS
 SG_ IDCTA_OffAvl : 38|1@0+ (1,0) [0|1] ""  CGM_LS,CSM_LS,RadioHead_LS
 SG_ IDATA_AnmTyp14Avl : 24|1@0+ (1,0) [0|1] ""  CGM_LS,CSM_LS,RadioHead_LS
 SG_ IDATA_AnmTyp13Avl : 25|1@0+ (1,0) [0|1] ""  CGM_LS,CSM_LS,RadioHead_LS
 SG_ IDATA_AnmTyp12Avl : 26|1@0+ (1,0) [0|1] ""  CGM_LS,CSM_LS,RadioHead_LS
 SG_ IDATA_AnmTyp11Avl : 27|1@0+ (1,0) [0|1] ""  CGM_LS,CSM_LS,RadioHead_LS
 SG_ IDATA_AnmTyp10Avl : 28|1@0+ (1,0) [0|1] ""  CGM_LS,CSM_LS,RadioHead_LS
 SG_ IDATA_AnmTyp9Avl : 29|1@0+ (1,0) [0|1] ""  CGM_LS,CSM_LS,RadioHead_LS
 SG_ IDATA_AnmTyp8Avl : 30|1@0+ (1,0) [0|1] ""  CGM_LS,CSM_LS,RadioHead_LS
 SG_ IDATA_AnmTyp7Avl : 31|1@0+ (1,0) [0|1] ""  CGM_LS,CSM_LS,RadioHead_LS
 SG_ IDATA_AnmTyp6Avl : 16|1@0+ (1,0) [0|1] ""  CGM_LS,CSM_LS,RadioHead_LS
 SG_ IDATA_AnmTyp5Avl : 17|1@0+ (1,0) [0|1] ""  CGM_LS,CSM_LS,RadioHead_LS
 SG_ IDATA_AnmTyp4Avl : 18|1@0+ (1,0) [0|1] ""  CGM_LS,CSM_LS,RadioHead_LS
 SG_ IDATA_AnmTyp3Avl : 19|1@0+ (1,0) [0|1] ""  CGM_LS,CSM_LS,RadioHead_LS
 SG_ IDATA_AnmTyp2Avl : 20|1@0+ (1,0) [0|1] ""  CGM_LS,CSM_LS,RadioHead_LS
 SG_ IDATA_AnmTyp1Avl : 21|1@0+ (1,0) [0|1] ""  CGM_LS,CSM_LS,RadioHead_LS
 SG_ IDATA_OffAvl : 22|1@0+ (1,0) [0|1] ""  CGM_LS,CSM_LS,RadioHead_LS
 SG_ AdjPdlMotInhbtd : 0|1@0+ (1,0) [0|1] ""  CGM_LS,MSM_P_LS,MSM_LS

BO_ 2149711872 ACC_YawRate_Information_LS: 8 BCM_LS
 SG_ SetSpdLmtRchd : 54|2@0+ (1,0) [0|3] ""  CGM_LS,IPC_LS
 SG_ FOAI_VehAhdIndRq : 63|4@0+ (1,0) [0|15] ""  CSM_LS,CGM_LS,RadioHead_LS,IPC_LS,CHUD_LS,HUD_LS
 SG_ FOAI_AlrtWrnIndRq : 59|4@0+ (1,0) [0|15] ""  CSM_LS,CGM_LS,RadioHead_LS,IPC_LS,CHUD_LS,HUD_LS
 SG_ FOAI_AlrtChmIhbRq : 48|1@0+ (1,0) [0|1] ""  CSM_LS,CGM_LS,RadioHead_LS,IPC_LS,CHUD_LS,HUD_LS
 SG_ FwdClnAlrtOffIO : 39|1@0+ (1,0) [0|1] ""  CSM_LS,CGM_LS,RadioHead_LS,IPC_LS
 SG_ FwdClnAlrtPr : 23|1@0+ (1,0) [0|1] ""  CSM_LS,V2V_LS,CGM_LS,RadioHead_LS,CHUD_LS,HUD_LS,IPC_LS
 SG_ VehDynYawRateV : 36|1@0+ (1,0) [0|1] ""  VPM_LS,CSM_LS,CGM_LS,SBZA_L_LS,SBZA_R_LS,RadioHead_LS,IPC_LS,FCM_LS,HBSM_LS,UPA_LS,APA_LS
 SG_ ACCHdwyStg : 22|3@0+ (1,0) [0|7] ""  CSM_LS,CGM_LS,RadioHead_LS,CHUD_LS,HUD_LS,IPC_LS
 SG_ ACCDrvrSeltdSpd : 3|12@0+ (0.0625,0) [0|255.9375] "km / h"  CSM_LS,CGM_LS,RadioHead_LS,CHUD_LS,HUD_LS,IPC_LS
 SG_ AdapCrsCntVDA : 4|1@0+ (1,0) [0|1] ""  V2V_LS,CGM_LS,CSM_LS,FCM_LS,CHUD_LS,HUD_LS,IPC_LS,RadioHead_LS
 SG_ SpdLmtrSpdWrngEnbld : 37|1@0+ (1,0) [0|1] ""  VIS2_LS,FCM_LS,CSM_LS,CGM_LS,RadioHead_LS,IPC_LS
 SG_ VehDynYawRate : 35|12@0- (0.0625,0) [-128|127.9375] "deg/sec"  VPM_LS,CSM_LS,CGM_LS,SBZA_L_LS,SBZA_R_LS,RadioHead_LS,IPC_LS,FCM_LS,HBSM_LS,UPA_LS,APA_LS
 SG_ CrsCntlDrSelSpdAct : 7|1@0+ (1,0) [0|1] ""  CSM_LS,CGM_LS,RadioHead_LS,IPC_LS
 SG_ ACCAct370 : 6|1@0+ (1,0) [0|1] ""  CSM_LS,V2V_LS,CGM_LS,VIS2_LS,RadioHead_LS,APA_LS,FCM_LS,CHUD_LS,HUD_LS,IPC_LS
 SG_ SpdLmtrSpdWrngAct : 38|1@0+ (1,0) [0|1] ""  VIS2_LS,FCM_LS,CSM_LS,CGM_LS,RadioHead_LS,IPC_LS
 SG_ CrsSpdLmtrDrvSelSpd : 19|12@0+ (0.0625,0) [0|255.9375] "km / h"  CSM_LS,FCM_LS,CGM_LS,RadioHead_LS,IPC_LS
 SG_ AutoMdSpdLmtStat : 50|2@0+ (1,0) [0|3] ""  CSM_LS,VIS2_LS,CGM_LS,FCM_LS,IPC_LS
 SG_ ACCAutoSetSpdStat : 52|2@0+ (1,0) [0|3] ""  CSM_LS,ONSTAR_LS,VIS2_LS,CGM_LS,IPC_LS

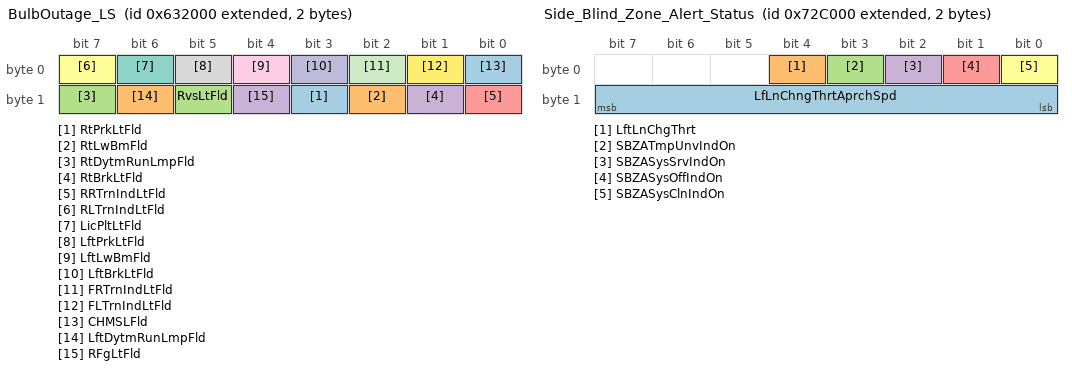
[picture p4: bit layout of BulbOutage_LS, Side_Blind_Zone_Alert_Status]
BO_ 2153979904 BulbOutage_LS: 2 BCM_LS
 SG_ RtPrkLtFld : 11|1@0+ (1,0) [0|1] ""  CSM_LS,TCP_LS,CGM_LS,RadioHead_LS,ONSTAR_LS,IPC_LS
 SG_ RtLwBmFld : 10|1@0+ (1,0) [0|1] ""  CSM_LS,TCP_LS,CGM_LS,RadioHead_LS,ONSTAR_LS,IPC_LS
 SG_ RtDytmRunLmpFld : 15|1@0+ (1,0) [0|1] ""  CSM_LS,CGM_LS,RadioHead_LS,IPC_LS
 SG_ RtBrkLtFld : 9|1@0+ (1,0) [0|1] ""  CSM_LS,TCP_LS,CGM_LS,RadioHead_LS,ONSTAR_LS,IPC_LS
 SG_ RRTrnIndLtFld : 8|1@0+ (1,0) [0|1] ""  CSM_LS,TCP_LS,CGM_LS,RadioHead_LS,ONSTAR_LS,IPC_LS
 SG_ RLTrnIndLtFld : 7|1@0+ (1,0) [0|1] ""  CSM_LS,TCP_LS,CGM_LS,RadioHead_LS,ONSTAR_LS,IPC_LS
 SG_ LicPltLtFld : 6|1@0+ (1,0) [0|1] ""  CSM_LS,TCP_LS,CGM_LS,RadioHead_LS,ONSTAR_LS,IPC_LS
 SG_ LftPrkLtFld : 5|1@0+ (1,0) [0|1] ""  CSM_LS,TCP_LS,CGM_LS,RadioHead_LS,ONSTAR_LS,IPC_LS
 SG_ LftLwBmFld : 4|1@0+ (1,0) [0|1] ""  CSM_LS,TCP_LS,CGM_LS,RadioHead_LS,ONSTAR_LS,IPC_LS
 SG_ LftBrkLtFld : 3|1@0+ (1,0) [0|1] ""  CSM_LS,TCP_LS,CGM_LS,RadioHead_LS,ONSTAR_LS,IPC_LS
 SG_ FRTrnIndLtFld : 2|1@0+ (1,0) [0|1] ""  CSM_LS,TCP_LS,CGM_LS,RadioHead_LS,ONSTAR_LS,IPC_LS
 SG_ FLTrnIndLtFld : 1|1@0+ (1,0) [0|1] ""  CSM_LS,TCP_LS,CGM_LS,RadioHead_LS,ONSTAR_LS,IPC_LS
 SG_ CHMSLFld : 0|1@0+ (1,0) [0|1] ""  CSM_LS,TCP_LS,CGM_LS,RadioHead_LS,ONSTAR_LS,IPC_LS
 SG_ LftDytmRunLmpFld : 14|1@0+ (1,0) [0|1] ""  CSM_LS,CGM_LS,RadioHead_LS,IPC_LS
 SG_ RvsLtFld : 13|1@0+ (1,0) [0|1] ""  CSM_LS,TCP_LS,CGM_LS,RadioHead_LS,ONSTAR_LS,IPC_LS
 SG_ RFgLtFld : 12|1@0+ (1,0) [0|1] ""  CSM_LS,TCP_LS,CGM_LS,RadioHead_LS,ONSTAR_LS,IPC_LS

BO_ 1368 UUDT_Resp_From_HVSM_R_LS: 8 HVSM_R_LS
 SG_ DgnInf_LS558 : 7|64@0+ (1,0) [0|1.84467440737096E+019] ""  CSM_LS,CGM_LS,TCP_LS,ONSTAR_LS,TestTool_LS

BO_ 1372 UUDT_Resp_From_SCL_LS: 8 SCL_LS
 SG_ DgnInf_LS55C : 7|64@0+ (1,0) [0|1.84467440737096E+019] ""  CSM_LS,CGM_LS,TCP_LS,ONSTAR_LS,TestTool_LS

BO_ 1367 UUDT_Resp_From_SBZA_R_LS: 8 SBZA_R_LS
 SG_ DgnInf_LS557 : 7|64@0+ (1,0) [0|1.84467440737096E+019] ""  CSM_LS,CGM_LS,TCP_LS,ONSTAR_LS,TestTool_LS

BO_ 1363 UUDT_Resp_From_TIM_CGM_LS: 8 TIM_LS
 SG_ DgnInf_LS553 : 7|64@0+ (1,0) [0|1.84467440737096E+019] ""  CGM_LS,CSM_LS,TCP_LS,ONSTAR_LS,TestTool_LS

BO_ 2150154240 Passive_Entry_Reply_LS: 8 BCM_LS
 SG_ PsvEntVehIdExt : 7|32@0+ (1,0) [0|4294967295] ""  CGM_LS,PEPS_LS
 SG_ PsvEntChlngRply : 39|32@0+ (1,0) [0|4294967295] "passwrd"  CGM_LS,PEPS_LS

BO_ 2155003904 Side_Blind_Zone_Alert_Status: 2 SBZA_L_LS
 SG_ LfLnChngThrtAprchSpd : 15|8@0- (1,0) [-128|127] "km/h"  BCM_LS,CGM_LS,HBSM_LS
 SG_ LftLnChgThrt : 4|1@0+ (1,0) [0|1] ""  BCM_LS,HBSM_LS,CGM_LS,VIS2_LS,EOCM_F_LS,FCM_LS
 SG_ SBZATmpUnvIndOn : 3|1@0+ (1,0) [0|1] ""  CGM_LS,SBZA_R_LS,IPC_LS
 SG_ SBZASysSrvIndOn : 2|1@0+ (1,0) [0|1] ""  CGM_LS,SBZA_R_LS,IPC_LS
 SG_ SBZASysOffIndOn : 1|1@0+ (1,0) [0|1] ""  CGM_LS,SBZA_R_LS,IPC_LS
 SG_ SBZASysClnIndOn : 0|1@0+ (1,0) [0|1] ""  CGM_LS,SBZA_R_LS,IPC_LS

BO_ 1353 UUDT_Resp_From_OTIM_MSM_P_LS: 8 OTIM_LS
 SG_ DgnInf_LS549 : 7|64@0+ (1,0) [0|1.84467440737096E+019] ""  CSM_LS,CGM_LS,TCP_LS,ONSTAR_LS,TestTool_LS

BO_ 585 USDT_Req_to_OTIM_MSM_P_LS: 8 TestTool_LS
 SG_ DgnInf : 7|64@0+ (1,0) [0|1.84467440737096E+019] ""  TCP_LS,ONSTAR_LS,CGM_LS,MSM_P_LS,OTIM_LS

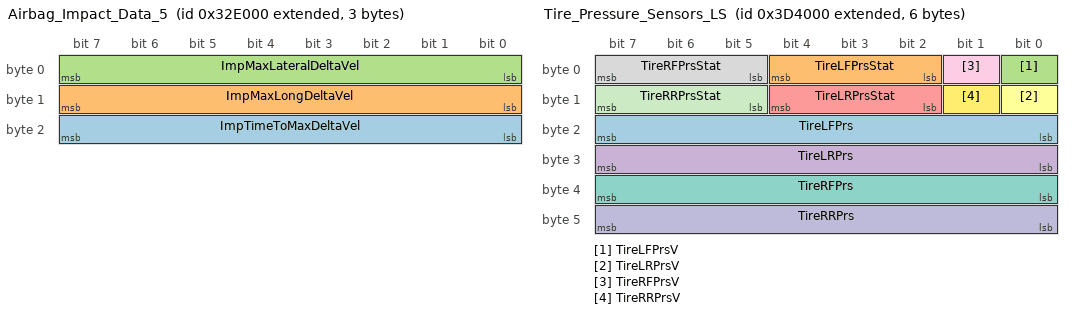
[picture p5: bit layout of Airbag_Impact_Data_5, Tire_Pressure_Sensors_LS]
BO_ 2150817792 Airbag_Impact_Data_5: 3 SDM_LS
 SG_ ImpTimeToMaxDeltaVel : 23|8@0+ (10,0) [0|2550] "ms"  TCP_LS,CGM_LS,ONSTAR_LS
 SG_ ImpMaxLongDeltaVel : 15|8@0- (1,0) [-128|127] ""  TCP_LS,CGM_LS,ONSTAR_LS
 SG_ ImpMaxLateralDeltaVel : 7|8@0- (1,0) [-128|127] ""  TCP_LS,CGM_LS,ONSTAR_LS

BO_ 2150227968 Phone_Speech_Rec_Status_LS: 1 ONSTAR_LS
 SG_ PhnSpRcgnApSt : 1|2@0+ (1,0) [0|3] ""  CGM_LS,CSM_LS,OTIM_LS,RadioHead_LS

BO_ 1624 USDT_Resp_From_HVSM_R_LS: 8 HVSM_R_LS
 SG_ DgnInf : 7|64@0+ (1,0) [0|1.84467440737096E+019] ""  CSM_LS,CGM_LS,TCP_LS,ONSTAR_LS,TestTool_LS

BO_ 1628 USDT_Resp_From_SCL_LS: 8 SCL_LS
 SG_ DgnInf : 7|64@0+ (1,0) [0|1.84467440737096E+019] ""  CSM_LS,CGM_LS,TCP_LS,ONSTAR_LS,TestTool_LS

BO_ 1623 USDT_Resp_From_SBZA_R_LS: 8 SBZA_R_LS
 SG_ DgnInf : 7|64@0+ (1,0) [0|1.84467440737096E+019] ""  CSM_LS,CGM_LS,TCP_LS,ONSTAR_LS,TestTool_LS

BO_ 1619 USDT_Resp_From_TIM_CGM_LS: 8 TIM_LS
 SG_ DgnInf : 7|64@0+ (1,0) [0|1.84467440737096E+019] ""  CGM_LS,CSM_LS,TCP_LS,ONSTAR_LS,TestTool_LS

BO_ 1621 USDT_Resp_From_VIS2_LS: 8 VIS2_LS
 SG_ DgnInf : 7|64@0+ (1,0) [0|1.84467440737096E+019] ""  CSM_LS,CGM_LS,TCP_LS,ONSTAR_LS,TestTool_LS

BO_ 1365 UUDT_Resp_From_VIS2_LS: 8 VIS2_LS
 SG_ DgnInf_LS555 : 7|64@0+ (1,0) [0|1.84467440737096E+019] ""  CSM_LS,CGM_LS,TCP_LS,ONSTAR_LS,TestTool_LS

BO_ 600 USDT_Req_to_HVSM_R_LS: 8 CGM_LS
 SG_ DgnInf : 7|64@0+ (1,0) [0|1.84467440737096E+019] ""  CGM_LS,TCP_LS,ONSTAR_LS,MSM_LR_LS,LCM_LS,HVSM_R_LS

BO_ 604 USDT_Req_to_SCL_LS: 8 CGM_LS
 SG_ DgnInf : 7|64@0+ (1,0) [0|1.84467440737096E+019] ""  CGM_LS,TCP_LS,ONSTAR_LS,SCL_LS

BO_ 599 USDT_Req_to_SBZA_R_LS: 8 TestTool_LS
 SG_ DgnInf : 7|64@0+ (1,0) [0|1.84467440737096E+019] ""  CGM_LS,TCP_LS,ONSTAR_LS,SBZA_R_LS

BO_ 597 USDT_Req_to_VIS2_LS: 8 TestTool_LS
 SG_ DgnInf : 7|64@0+ (1,0) [0|1.84467440737096E+019] ""  CGM_LS,TCP_LS,ONSTAR_LS,TIM_A_LS,VIS2_LS

BO_ 1568 VNMF_LS_620_VICM: 8 VICM_LS
 SG_ VectraSpcNWMgtD : 7|64@0+ (1,0) [0|1.84467440737096E+019] ""  TCP_LS,LVMNav_LS,UHP_Low,ONSTAR_LS,TIM_B_LS,RSE_LS,RSA_LS,HVSM_F_LS,MSM_LS,BCM_LS,AOS_LS,AMP_LS,V2V_LS,ARB_LS,HFP_LS,PDIM_LS,SBZA_R_LS,ICS_LS,EOCM2A_K2_LS,FCM_LS,EOCM_F_LS,VKM_LS,RSC_LS,PSD_R_LS,CHUD_LS,MSM_RR_LS,LVMPC_LS,PSD_L_LS,DCAC_LS,AGC_LS,TouchPad_LS,DVB_T_LS,EOCM2B_K2_LS,PHS_LS,SDM_LS,SCL_LS,SBZA_L_LS,CSM_LS,CHM_LS,RadioHead_LS,STC_LS,PTM_LS,PEPS_LS,MSM_P_LS,OTIM_LS,MSM_LR_LS,LCM_LS,HVSM_R_LS,CGM_LS,TIM_LS,TIM_A_LS,VIS2_LS,TestTool_LS,IPC_LS,VPM_LS,HUD_LS,RCRM_LS,ISRVM_LS,HBSM_LS,ECC_LS,UPA_LS,APA_LS

BO_ 1570 VNMF_LS_622_PEPS_PBSM: 8 PEPS_LS
 SG_ VectraSpcNWMgtD : 7|64@0+ (1,0) [0|1.84467440737096E+019] ""  TCP_LS,LVMNav_LS,UHP_Low,ONSTAR_LS,TIM_B_LS,RSE_LS,RSA_LS,HVSM_F_LS,MSM_LS,BCM_LS,AOS_LS,AMP_LS,V2V_LS,ARB_LS,BSM_LS,VICM_LS,HFP_LS,PDIM_LS,SBZA_R_LS,ICS_LS,EOCM2A_K2_LS,FCM_LS,EOCM_F_LS,MSM_LR_LS,LCM_LS,HVSM_R_LS,VKM_LS,RSC_LS,PSD_R_LS,CHUD_LS,MSM_RR_LS,LVMPC_LS,PSD_L_LS,DCAC_LS,AGC_LS,TouchPad_LS,DVB_T_LS,EOCM2B_K2_LS,PHS_LS,SDM_LS,SCL_LS,SBZA_L_LS,CSM_LS,CHM_LS,RadioHead_LS,STC_LS,PTM_LS,MSM_P_LS,OTIM_LS,CGM_LS,TIM_LS,TIM_A_LS,VIS2_LS,TestTool_LS,IPC_LS,VPM_LS,HUD_LS,RCRM_LS,ISRVM_LS,HBSM_LS,ECC_LS,UPA_LS,APA_LS

BO_ 2162982912 VIN_Digits_10_to_17: 8 BCM_LS
 SG_ VehIdNmDig10_17 : 7|64@0+ (1,0) [0|1] ""  RSE_LS,VKM_LS,VPM_LS,TCP_LS,CSM_LS,EOCM2B_K2_LS,EOCM2A_K2_LS,CGM_LS,VIS2_LS,LVMPC_LS,EDI_LS,LVMNav_LS,EOCM_F_LS,SBZA_R_LS,SBZA_L_LS,ONSTAR_LS,RadioHead_LS,UPA_LS,IPC_LS,ECC_LS,APA_LS,FCM_LS,SDM_LS

BO_ 2162966528 VIN_Digits_2_to_9: 8 BCM_LS
 SG_ VehIdNmDig2_9 : 7|64@0+ (1,0) [0|1] ""  RSE_LS,VKM_LS,VPM_LS,TCP_LS,CSM_LS,EOCM2B_K2_LS,EOCM2A_K2_LS,CGM_LS,VIS2_LS,LVMPC_LS,EDI_LS,EOCM_F_LS,SBZA_R_LS,SBZA_L_LS,ONSTAR_LS,RadioHead_LS,UPA_LS,IPC_LS,APA_LS,ECC_LS,FCM_LS,SDM_LS

BO_ 2151497728 Tire_Pressure_Sensors_LS: 6 BCM_LS
 SG_ TireLFPrs : 23|8@0+ (4,0) [0|1020] "kPaG"  CSM_LS,VPM_LS,TCP_LS,V2V_LS,CGM_LS,RadioHead_LS,ONSTAR_LS,IPC_LS
 SG_ TireLFPrsStat : 4|3@0+ (1,0) [0|7] ""  CSM_LS,VPM_LS,TCP_LS,CGM_LS,RadioHead_LS,ONSTAR_LS,IPC_LS
 SG_ TireLFPrsV : 0|1@0+ (1,0) [0|1] ""  CSM_LS,VPM_LS,TCP_LS,V2V_LS,CGM_LS,RadioHead_LS,ONSTAR_LS,IPC_LS
 SG_ TireLRPrs : 31|8@0+ (4,0) [0|1020] "kPaG"  CSM_LS,VPM_LS,TCP_LS,V2V_LS,CGM_LS,RadioHead_LS,ONSTAR_LS,IPC_LS
 SG_ TireLRPrsStat : 12|3@0+ (1,0) [0|7] ""  CSM_LS,VPM_LS,TCP_LS,CGM_LS,RadioHead_LS,ONSTAR_LS,IPC_LS
 SG_ TireLRPrsV : 8|1@0+ (1,0) [0|1] ""  CSM_LS,TCP_LS,VPM_LS,V2V_LS,CGM_LS,RadioHead_LS,ONSTAR_LS,IPC_LS
 SG_ TireRFPrs : 39|8@0+ (4,0) [0|1020] "kPaG"  CSM_LS,TCP_LS,VPM_LS,V2V_LS,CGM_LS,RadioHead_LS,ONSTAR_LS,IPC_LS
 SG_ TireRFPrsStat : 7|3@0+ (1,0) [0|7] ""  CSM_LS,TCP_LS,VPM_LS,CGM_LS,RadioHead_LS,ONSTAR_LS,IPC_LS
 SG_ TireRFPrsV : 1|1@0+ (1,0) [0|1] ""  CSM_LS,TCP_LS,VPM_LS,V2V_LS,CGM_LS,RadioHead_LS,ONSTAR_LS,IPC_LS
 SG_ TireRRPrs : 47|8@0+ (4,0) [0|1020] "kPaG"  CSM_LS,TCP_LS,VPM_LS,V2V_LS,CGM_LS,RadioHead_LS,ONSTAR_LS,IPC_LS
 SG_ TireRRPrsStat : 15|3@0+ (1,0) [0|7] ""  CSM_LS,TCP_LS,VPM_LS,CGM_LS,RadioHead_LS,ONSTAR_LS,IPC_LS
 SG_ TireRRPrsV : 9|1@0+ (1,0) [0|1] ""  CSM_LS,TCP_LS,VPM_LS,V2V_LS,CGM_LS,RadioHead_LS,ONSTAR_LS,IPC_LS

BO_ 2151219200 Remote_Start_Status: 1 BCM_LS
 SG_ RemStrtSt : 0|1@0+ (1,0) [0|1] ""  VKM_LS,TCP_LS,CSM_LS,CGM_LS,SCL_LS,MSM_P_LS,HVSM_F_LS,MSM_LS,HVSM_R_LS,RadioHead_LS,ONSTAR_LS,LCM_LS,PTM_LS,ECC_LS
 SG_ RmVehStrRq : 1|1@0+ (1,0) [0|1] ""  TCP_LS,CGM_LS,ONSTAR_LS,CSM_LS,RadioHead_LS,LCM_LS,PTM_LS

BO_ 2153775104 DTC_Triggered: 7 BCM_LS
 SG_ DTCI_DTCFaultType : 55|8@0+ (1,0) [0|255] ""  CGM_LS,RadioHead_LS,TCP_LS,ONSTAR_LS
 SG_ DTCI_CodeSupported : 40|1@0+ (1,0) [0|1] ""  CGM_LS,RadioHead_LS,TCP_LS,ONSTAR_LS
 SG_ DTCI_CurrentStatus : 41|1@0+ (1,0) [0|1] ""  CGM_LS,RadioHead_LS,TCP_LS,ONSTAR_LS
 SG_ DTCI_TstNPsdCdClrdSt : 42|1@0+ (1,0) [0|1] ""  CGM_LS,RadioHead_LS,TCP_LS,ONSTAR_LS
 SG_ DTCI_TstFldCdClrdStat : 43|1@0+ (1,0) [0|1] ""  CGM_LS,RadioHead_LS,TCP_LS,ONSTAR_LS
 SG_ DTCI_HistStat : 44|1@0+ (1,0) [0|1] ""  CGM_LS,RadioHead_LS,TCP_LS,ONSTAR_LS
 SG_ DTCI_TstNPsdPwrUpSt : 45|1@0+ (1,0) [0|1] ""  CGM_LS,RadioHead_LS,TCP_LS,ONSTAR_LS
 SG_ DTCI_TstFldPwrUpSt : 46|1@0+ (1,0) [0|1] ""  CGM_LS,RadioHead_LS,TCP_LS,ONSTAR_LS
 SG_ DTCI_WrnIndRqdSt : 47|1@0+ (1,0) [0|1] ""  CGM_LS,RadioHead_LS,TCP_LS,ONSTAR_LS
 SG_ DTCI_DTCFailType : 39|8@0+ (1,0) [0|255] ""  CGM_LS,RadioHead_LS,TCP_LS,ONSTAR_LS
 SG_ DTCI_DTCNumber : 23|16@0+ (1,0) [0|65535] ""  CGM_LS,RadioHead_LS,TCP_LS,ONSTAR_LS
 SG_ DTCI_DTCSource : 15|8@0+ (1,0) [0|255] ""  CGM_LS,RadioHead_LS,TCP_LS,ONSTAR_LS
 SG_ DTCI_DTCTriggered : 0|1@0+ (1,0) [0|1] ""  CGM_LS,RadioHead_LS,TCP_LS,ONSTAR_LS
 SG_ DTCIUnused7 : 7|1@0+ (1,0) [0|1] ""  CGM_LS,RadioHead_LS,TCP_LS,ONSTAR_LS
 SG_ DTCIUnused6 : 6|1@0+ (1,0) [0|1] ""  CGM_LS,RadioHead_LS,TCP_LS,ONSTAR_LS
 SG_ DTCIUnused5 : 5|1@0+ (1,0) [0|1] ""  CGM_LS,RadioHead_LS,TCP_LS,ONSTAR_LS
 SG_ DTCIUnused4 : 4|1@0+ (1,0) [0|1] ""  CGM_LS,RadioHead_LS,TCP_LS,ONSTAR_LS
 SG_ DTCIUnused3 : 3|1@0+ (1,0) [0|1] ""  CGM_LS,RadioHead_LS,TCP_LS,ONSTAR_LS
 SG_ DTCIUnused2 : 2|1@0+ (1,0) [0|1] ""  CGM_LS,RadioHead_LS,TCP_LS,ONSTAR_LS
 SG_ DTCIUnused1 : 1|1@0+ (1,0) [0|1] ""  CGM_LS,RadioHead_LS,TCP_LS,ONSTAR_LS

BO_TX_BU_ 2153381888 : LCM_LS,PTM_LS;
BO_TX_BU_ 2151514112 : CGM_LS,TCP_LS,ONSTAR_LS,IPC_LS;
BO_TX_BU_ 2158903296 : CGM_LS,CHUD_LS,HUD_LS;
BO_TX_BU_ 2158911488 : CSM_LS,CGM_LS,RadioHead_LS;
BO_TX_BU_ 2158919680 : CGM_LS,IPC_LS;
BO_TX_BU_ 2151825408 : CGM_LS,BCM_LS,IPC_LS;
BO_TX_BU_ 2151170048 : TIM_B_LS,TIM_A_LS,TIM_LS;
BO_TX_BU_ 1368 : MSM_LR_LS,LCM_LS,HVSM_R_LS;
BO_TX_BU_ 1363 : CGM_LS,TIM_LS;
BO_TX_BU_ 2155003904 : EOCM2A_K2_LS,UPA_LS,APA_LS,SBZA_L_LS;
BO_TX_BU_ 1353 : CGM_LS,MSM_P_LS,OTIM_LS;
BO_TX_BU_ 585 : CSM_LS,CGM_LS,TCP_LS,ONSTAR_LS,TestTool_LS;
BO_TX_BU_ 2150227968 : TCP_LS,UHP_Low,ONSTAR_LS;
BO_TX_BU_ 1624 : MSM_LR_LS,LCM_LS,HVSM_R_LS;
BO_TX_BU_ 1619 : CGM_LS,TIM_LS;
BO_TX_BU_ 1621 : TIM_A_LS,VIS2_LS;
BO_TX_BU_ 1365 : TIM_A_LS,VIS2_LS;
BO_TX_BU_ 600 : CSM_LS,CGM_LS,TCP_LS,ONSTAR_LS,TestTool_LS;
BO_TX_BU_ 604 : CSM_LS,CGM_LS,TCP_LS,ONSTAR_LS,TestTool_LS;
BO_TX_BU_ 599 : CSM_LS,CGM_LS,TCP_LS,ONSTAR_LS,TestTool_LS;
BO_TX_BU_ 597 : CSM_LS,CGM_LS,TCP_LS,ONSTAR_LS,TestTool_LS;
BO_TX_BU_ 1568 : BSM_LS,VICM_LS;
BO_TX_BU_ 2153775104 : CHUD_LS,VKM_LS,RCRM_LS,MSM_RR_LS,MSM_LR_LS,VPM_LS,ISRVM_LS,DCAC_LS,TouchPad_LS,RSC_LS,LVMPC_LS,LCM_LS,TIM_B_LS,V2V_LS,TCP_LS,CSM_LS,EOCM2B_K2_LS,EOCM2A_K2_LS,TIM_A_LS,LVMNav_LS,HFP_LS,ARB_LS,RSE_LS,VIS2_LS,ICS_LS,FCM_LS,AGC_LS,MSM_P_LS,OTIM_LS,HVSM_R_LS,HVSM_F_LS,DVB_T_LS,SBZA_R_LS,PSD_R_LS,PSD_L_LS,UHP_Low,UPA_LS,STC_LS,SBZA_L_LS,PTM_LS,ONSTAR_LS,APA_LS,PHS_LS,PDIM_LS,CHM_LS,RSA_LS,AMP_LS,HUD_LS,MSM_LS,HBSM_LS,SCL_LS,ECC_LS,RadioHead_LS,PEPS_LS,IPC_LS,AOS_LS,SDM_LS,TIM_LS,BCM_LS;
CM_ SG_ 2154905600 DrId "Driver 8 changed to Unknown on 3/30/99";
CM_ SG_ 2149752832 IntBrkAssPreFilReq "IntelligentBrakeAssistPreFillRequest";
CM_ SG_ 2149752832 BrkSysRedBrkTlltlReq "Added acc to Björn 0410";
CM_ SG_ 2158903296 ODDMA_ReqType "ODI - Type of Request";
CM_ SG_ 2158903296 ODDMA_FUCID "ODI - Primary ID of Functional Unit in FU Database";
CM_ SG_ 2158903296 ODDMA_DispMID "ODI - ID that identifies the display requesting the data.  See detailed requirements in ODI GMLAN Protocol.";
CM_ SG_ 2158903296 ODDMA_DataID2Vld "ODI -DataIDTwo is being requested as a valid ID.";
CM_ SG_ 2158903296 ODDMA_DataID2 "ODI - ID for the second requested data parameter as defined in the FUDatabase";
CM_ SG_ 2158903296 ODDMA_DataID3Vld "ODI -DataIDThree is being requested as a valid ID.";
CM_ SG_ 2158903296 ODDMA_DataID3 "ODI - ID for the third requested data parameter as defined in the FUDatabase";
CM_ SG_ 2158903296 ODDMA_DataID1 "ODI - ID for the first requested data parameter as defined in the FUDatabase";
CM_ SG_ 2158903296 ODDMA_DataID4Vld "ODI -DataIDFour is being requested as a valid ID.";
CM_ SG_ 2158903296 ODDMA_DataID4 "ODI - ID for the fourth requested data parameter as defined in the FUDatabase";
CM_ SG_ 2158903296 ODDMA_DataID5Vld "ODI -DataIDFive is being requested as a valid ID.";
CM_ SG_ 2158903296 ODDMA_DataID5 "ODI - ID for the fifth requested data parameter as defined in the FUDatabase";
CM_ SG_ 2158911488 ODDMC_ReqType "ODI - Type of Request";
CM_ SG_ 2158911488 ODDMC_DispMID "ODI - ID that identifies the display requesting the data.  See detailed requirements in ODI GMLAN Protocol.";
CM_ SG_ 2158911488 ODDMC_DataID2Vld "ODI -DataIDTwo is being requested as a valid ID.";
CM_ SG_ 2158911488 ODDMC_DataID2 "ODI - ID for the second requested data parameter as defined in the FUDatabase";
CM_ SG_ 2158911488 ODDMC_DataID3Vld "ODI -DataIDThree is being requested as a valid ID.";
CM_ SG_ 2158911488 ODDMC_DataID3 "ODI - ID for the third requested data parameter as defined in the FUDatabase";
CM_ SG_ 2158911488 ODDMC_DataID1 "ODI - ID for the first requested data parameter as defined in the FUDatabase";
CM_ SG_ 2158911488 ODDMC_DataID4Vld "ODI -DataIDFour is being requested as a valid ID.";
CM_ SG_ 2158911488 ODDMC_DataID4 "ODI - ID for the fourth requested data parameter as defined in the FUDatabase";
CM_ SG_ 2158911488 ODDMC_DataID5Vld "ODI -DataIDFive is being requested as a valid ID.";
CM_ SG_ 2158911488 ODDMC_DataID5 "ODI - ID for the fifth requested data parameter as defined in the FUDatabase";
CM_ SG_ 2158911488 ODDMC_FUCID "ODI - Primary ID of Functional Unit in FU Database";
CM_ SG_ 2158919680 ODDMI_ReqType "ODI - Type of Request";
CM_ SG_ 2158919680 ODDMI_FUCID "ODI - Primary ID of Functional Unit in FU Database";
CM_ SG_ 2158919680 ODDMI_DispMID "ODI - ID that identifies the display requesting the data.  See detailed requirements in ODI GMLAN Protocol.";
CM_ SG_ 2158919680 ODDMI_DataID2Vld "ODI -DataIDTwo is being requested as a valid ID.";
CM_ SG_ 2158919680 ODDMI_DataID2 "ODI - ID for the second requested data parameter as defined in the FUDatabase";
CM_ SG_ 2158919680 ODDMI_DataID3Vld "ODI -DataIDThree is being requested as a valid ID.";
CM_ SG_ 2158919680 ODDMI_DataID3 "ODI - ID for the third requested data parameter as defined in the FUDatabase";
CM_ SG_ 2158919680 ODDMI_DataID1 "ODI - ID for the first requested data parameter as defined in the FUDatabase";
CM_ SG_ 2158919680 ODDMI_DataID4Vld "ODI -DataIDFour is being requested as a valid ID.";
CM_ SG_ 2158919680 ODDMI_DataID4 "ODI - ID for the fourth requested data parameter as defined in the FUDatabase";
CM_ SG_ 2158919680 ODDMI_DataID5Vld "ODI -DataIDFive is being requested as a valid ID.";
CM_ SG_ 2158919680 ODDMI_DataID5 "ODI - ID for the fifth requested data parameter as defined in the FUDatabase";
CM_ SG_ 2149711872 ACCHdwyStg "Headway is the  time which results from dividing the following distance (or gap) between vehicles by the vehicle speed.  This setting allows the driver to choose a Headway Setting without actually knowing the value of this time.";
CM_ BO_ 1568 "LAP: Tester VNMF?";
CM_ SG_ 2162982912 VehIdNmDig10_17 "Desc: 8 ASCII Characters";
CM_ SG_ 2162966528 VehIdNmDig2_9 "Desc: 8 ASCII Characters";
CM_ SG_ 2153775104 DTCI_DTCFaultType "Based on Powertrain definition.  Not expected to be supported by all devices.";
CM_ SG_ 2153775104 DTCI_DTCFailType "Assigned per GMW3110, Appendix E";
CM_ SG_ 2153775104 DTCI_DTCSource "This shall be equal to the Diagnostic Address of the transmittting device.";
BA_DEF_ SG_  "VNSigPrimaryTriggering" ENUM  "No","Yes","DLCLS","DLCHS","DLCCE","DLCFO";
BA_DEF_ SG_  "VNSigRemoteDiagnostics" ENUM  "No","Yes","DLCLS","DLCHS","DLCCE","DLCFO";
BA_DEF_ SG_  "VNSigInfotainment" ENUM  "No","Yes","DLCLS","DLCHS","DLCCE","DLCFO";
BA_DEF_ SG_  "VNSigParkedVehicle" ENUM  "No","Yes","DLCLS","DLCHS","DLCCE","DLCFO";
BA_DEF_ SG_  "VNSigIntermediate" ENUM  "No","Yes","DLCLS","DLCHS","DLCCE","DLCFO";
BA_DEF_ SG_  "VNSigUnused_4" ENUM  "No","Yes","DLCLS","DLCHS","DLCCE","DLCFO";
BA_DEF_ SG_  "SignalType" STRING ;
BA_DEF_ SG_  "PacketOrder" INT 0 65535;
BA_DEF_ SG_  "SignalLongName" STRING ;
BA_DEF_ SG_  "GenSigStartValue" INT 0 65535;
BA_DEF_ SG_  "VNSigDiagnostic" ENUM  "No","Yes","DLCLS","DLCHS","DLCCE","DLCFO";
BA_DEF_ SG_  "VNSigAllNodes" ENUM  "No","Yes","DLCLS","DLCHS","DLCCE","DLCFO";
BA_DEF_ SG_  "GenSigDeltaValue" INT 0 0;
BA_DEF_ SG_  "GenSigInactiveValue" INT 0 0;
BA_DEF_ SG_  "GenSigSendType" ENUM  "not used","not used","not used","not used","not used","not used","not used","NoSigSendType","not used","not used","OnAnyChange","OnChangeIfActive","OnDelta","DLCLS","DLCHS","DLCCE","DLCFO";
BA_DEF_ SG_  "GenSigSendOnInit" ENUM  "Not Initialized","Application","Handler","DLCLS","DLCHS","DLCCE","DLCFO";
BA_DEF_ BO_  "AppGenMsgCycleTime" INT 0 0;
BA_DEF_ BO_  "TpTxIndex" INT 0 99;
BA_DEF_ BO_  "GenMsgILSupport" ENUM  "No","Yes","DLCLS","DLCHS","DLCCE","DLCFO";
BA_DEF_ BO_  "TpApplType" STRING ;
BA_DEF_ BO_  "Prio" INT 0 7;
BA_DEF_ BO_  "MessageSubnet" ENUM  "LS","MS","HS","CE","PE","HV","FO","S1","HE","LE","HE2","DLCLS","DLCHS","DLCCE","DLCFO";
BA_DEF_ BO_  "GenMsgMandatoryToSupervision" ENUM  "No","Yes","DLCLS","DLCHS","DLCCE","DLCFO";
BA_DEF_ BO_  "DiagState" ENUM  "No","Yes","DLCLS","DLCHS","DLCCE","DLCFO";
BA_DEF_ BO_  "GenMsgStartDelayTime" INT 0 100000;
BA_DEF_ BO_  "GenMsgDelayTime" INT 0 100000;
BA_DEF_ BO_  "GenMsgCycleTime" INT 0 100000;
BA_DEF_ BO_  "GenMsgSendType" ENUM  "cyclicX","spontanX","cyclicIfActiveX","spontanWithDelay","cyclicAndSpontanX","cyclicAndSpontanWithDelay","spontanWithRepitition","cyclicIfActiveAndSpontanWD","DLCLS","DLCHS","DLCCE","DLCFO";
BA_DEF_ BO_  "DiagResponse" ENUM  "No","Yes","DLCLS","DLCHS","DLCCE","DLCFO";
BA_DEF_ BO_  "DiagRequest" ENUM  "No","Yes","DLCLS","DLCHS","DLCCE","DLCFO";
BA_DEF_ BO_  "NmMessage" ENUM  "No","Yes","DLCLS","DLCHS","DLCCE","DLCFO";
BA_DEF_REL_ BU_SG_REL_  "GenSigSuprvRespComment" STRING ;
BA_DEF_REL_ BU_SG_REL_  "GenSigVBitResp" ENUM  "No","Yes","DLCLS","DLCHS","DLCCE","DLCFO";
BA_DEF_REL_ BU_SG_REL_  "GenSigVBitRespComment" STRING ;
BA_DEF_REL_ BU_SG_REL_  "GenSigVDAFailComment" STRING ;
BA_DEF_REL_ BU_SG_REL_  "GenSigVDAFailResp" ENUM  "No","Yes","DLCLS","DLCHS","DLCCE","DLCFO";
BA_DEF_REL_ BU_SG_REL_  "GenSigRxStartValue" STRING ;
BA_DEF_REL_ BU_SG_REL_  "GenSigSuprvRespSubValue" INT 0 65535;
BA_DEF_REL_ BU_SG_REL_  "GenSigSuprvResp" ENUM  "None","Notify App","Substitute Default","DLCLS","DLCHS","DLCCE","DLCFO";
BA_DEF_REL_ BU_SG_REL_  "GenSigTimeoutMsg" HEX -2147483648 268435455;
BA_DEF_REL_ BU_SG_REL_  "GenSigTimeoutTime" INT 0 15000;
BA_DEF_DEF_  "VNSigPrimaryTriggering" "No";
BA_DEF_DEF_  "VNSigRemoteDiagnostics" "No";
BA_DEF_DEF_  "VNSigInfotainment" "No";
BA_DEF_DEF_  "VNSigParkedVehicle" "No";
BA_DEF_DEF_  "VNSigIntermediate" "No";
BA_DEF_DEF_  "VNSigUnused_4" "No";
BA_DEF_DEF_  "SignalType" "";
BA_DEF_DEF_  "PacketOrder" 0;
BA_DEF_DEF_  "SignalLongName" "";
BA_DEF_DEF_  "GenSigStartValue" 0;
BA_DEF_DEF_  "VNSigDiagnostic" "No";
BA_DEF_DEF_  "VNSigAllNodes" "No";
BA_DEF_DEF_  "GenSigDeltaValue" 0;
BA_DEF_DEF_  "GenSigInactiveValue" 0;
BA_DEF_DEF_  "GenSigSendType" "NoSigSendType";
BA_DEF_DEF_  "GenSigSendOnInit" "Not Initialized";
BA_DEF_DEF_  "AppGenMsgCycleTime" 0;
BA_DEF_DEF_  "TpTxIndex" 0;
BA_DEF_DEF_  "GenMsgILSupport" "Yes";
BA_DEF_DEF_  "TpApplType" "";
BA_DEF_DEF_  "Prio" 4;
BA_DEF_DEF_  "MessageSubnet" "FO";
BA_DEF_DEF_  "GenMsgMandatoryToSupervision" "No";
BA_DEF_DEF_  "DiagState" "No";
BA_DEF_DEF_  "GenMsgStartDelayTime" 0;
BA_DEF_DEF_  "GenMsgDelayTime" 0;
BA_DEF_DEF_  "GenMsgCycleTime" 0;
BA_DEF_DEF_  "GenMsgSendType" "spontanX";
BA_DEF_DEF_  "DiagResponse" "No";
BA_DEF_DEF_  "DiagRequest" "No";
BA_DEF_DEF_  "NmMessage" "No";
BA_DEF_DEF_REL_ "GenSigSuprvRespComment" "";
BA_DEF_DEF_REL_ "GenSigVBitResp" "No";
BA_DEF_DEF_REL_ "GenSigVBitRespComment" "";
BA_DEF_DEF_REL_ "GenSigVDAFailComment" "";
BA_DEF_DEF_REL_ "GenSigVDAFailResp" "No";
BA_DEF_DEF_REL_ "GenSigRxStartValue" "";
BA_DEF_DEF_REL_ "GenSigSuprvRespSubValue" 0;
BA_DEF_DEF_REL_ "GenSigSuprvResp" "None";
BA_DEF_DEF_REL_ "GenSigTimeoutMsg" 0;
BA_DEF_DEF_REL_ "GenSigTimeoutTime" 0;
BA_ "Prio" BO_ 2154905600 3;
BA_ "MessageSubnet" BO_ 2154905600 0;
BA_ "GenMsgDelayTime" BO_ 2154905600 100;
BA_ "MessageSubnet" BO_ 2154954752 0;
BA_ "GenMsgDelayTime" BO_ 2154954752 100;
BA_ "MessageSubnet" BO_ 2153381888 0;
BA_ "GenMsgDelayTime" BO_ 2153381888 100;
BA_ "MessageSubnet" BO_ 2149752832 0;
BA_ "GenMsgStartDelayTime" BO_ 2149752832 110;
BA_ "GenMsgCycleTime" BO_ 2149752832 250;
BA_ "GenMsgSendType" BO_ 2149752832 0;
BA_ "MessageSubnet" BO_ 2151514112 0;
BA_ "GenMsgDelayTime" BO_ 2151514112 100;
BA_ "MessageSubnet" BO_ 2158903296 0;
BA_ "GenMsgDelayTime" BO_ 2158903296 20;
BA_ "MessageSubnet" BO_ 2158911488 0;
BA_ "GenMsgDelayTime" BO_ 2158911488 20;
BA_ "MessageSubnet" BO_ 2158919680 0;
BA_ "GenMsgDelayTime" BO_ 2158919680 20;
BA_ "MessageSubnet" BO_ 2151825408 0;
BA_ "GenMsgDelayTime" BO_ 2151825408 100;
BA_ "MessageSubnet" BO_ 2151153664 0;
BA_ "GenMsgDelayTime" BO_ 2151153664 100;
BA_ "MessageSubnet" BO_ 2151170048 0;
BA_ "GenMsgDelayTime" BO_ 2151170048 100;
BA_ "MessageSubnet" BO_ 2151841792 0;
BA_ "GenMsgDelayTime" BO_ 2151841792 100;
BA_ "MessageSubnet" BO_ 2154995712 0;
BA_ "GenMsgDelayTime" BO_ 2154995712 100;
BA_ "MessageSubnet" BO_ 2154094592 0;
BA_ "GenMsgDelayTime" BO_ 2154094592 100;
BA_ "MessageSubnet" BO_ 2149711872 0;
BA_ "GenMsgStartDelayTime" BO_ 2149711872 120;
BA_ "GenMsgCycleTime" BO_ 2149711872 100;
BA_ "GenMsgSendType" BO_ 2149711872 0;
BA_ "MessageSubnet" BO_ 2153979904 0;
BA_ "GenMsgDelayTime" BO_ 2153979904 100;
BA_ "GenMsgILSupport" BO_ 1368 0;
BA_ "TpApplType" BO_ 1368 "DiagUUDTResponse";
BA_ "Prio" BO_ 1368 0;
BA_ "MessageSubnet" BO_ 1368 0;
BA_ "GenMsgILSupport" BO_ 1372 0;
BA_ "TpApplType" BO_ 1372 "DiagUUDTResponse";
BA_ "Prio" BO_ 1372 0;
BA_ "MessageSubnet" BO_ 1372 0;
BA_ "GenMsgILSupport" BO_ 1367 0;
BA_ "TpApplType" BO_ 1367 "DiagUUDTResponse";
BA_ "Prio" BO_ 1367 0;
BA_ "MessageSubnet" BO_ 1367 0;
BA_ "GenMsgILSupport" BO_ 1363 0;
BA_ "TpApplType" BO_ 1363 "DiagUUDTResponse";
BA_ "Prio" BO_ 1363 0;
BA_ "MessageSubnet" BO_ 1363 0;
BA_ "Prio" BO_ 2150154240 3;
BA_ "MessageSubnet" BO_ 2150154240 0;
BA_ "GenMsgDelayTime" BO_ 2150154240 100;
BA_ "MessageSubnet" BO_ 2155003904 0;
BA_ "GenMsgDelayTime" BO_ 2155003904 100;
BA_ "GenMsgILSupport" BO_ 1353 0;
BA_ "TpApplType" BO_ 1353 "DiagUUDTResponse";
BA_ "Prio" BO_ 1353 0;
BA_ "MessageSubnet" BO_ 1353 0;
BA_ "GenMsgILSupport" BO_ 585 0;
BA_ "Prio" BO_ 585 0;
BA_ "MessageSubnet" BO_ 585 0;
BA_ "DiagRequest" BO_ 585 1;
BA_ "MessageSubnet" BO_ 2150817792 0;
BA_ "GenMsgDelayTime" BO_ 2150817792 10;
BA_ "MessageSubnet" BO_ 2150227968 0;
BA_ "GenMsgDelayTime" BO_ 2150227968 100;
BA_ "Prio" BO_ 1624 0;
BA_ "MessageSubnet" BO_ 1624 0;
BA_ "DiagResponse" BO_ 1624 1;
BA_ "Prio" BO_ 1628 0;
BA_ "MessageSubnet" BO_ 1628 0;
BA_ "DiagResponse" BO_ 1628 1;
BA_ "Prio" BO_ 1623 0;
BA_ "MessageSubnet" BO_ 1623 0;
BA_ "DiagResponse" BO_ 1623 1;
BA_ "Prio" BO_ 1619 0;
BA_ "MessageSubnet" BO_ 1619 0;
BA_ "DiagResponse" BO_ 1619 1;
BA_ "Prio" BO_ 1621 0;
BA_ "MessageSubnet" BO_ 1621 0;
BA_ "DiagResponse" BO_ 1621 1;
BA_ "GenMsgILSupport" BO_ 1365 0;
BA_ "TpApplType" BO_ 1365 "DiagUUDTResponse";
BA_ "Prio" BO_ 1365 0;
BA_ "MessageSubnet" BO_ 1365 0;
BA_ "Prio" BO_ 600 0;
BA_ "MessageSubnet" BO_ 600 0;
BA_ "DiagRequest" BO_ 600 1;
BA_ "Prio" BO_ 604 0;
BA_ "MessageSubnet" BO_ 604 0;
BA_ "DiagRequest" BO_ 604 1;
BA_ "Prio" BO_ 599 0;
BA_ "MessageSubnet" BO_ 599 0;
BA_ "DiagRequest" BO_ 599 1;
BA_ "Prio" BO_ 597 0;
BA_ "MessageSubnet" BO_ 597 0;
BA_ "DiagRequest" BO_ 597 1;
BA_ "Prio" BO_ 1568 0;
BA_ "MessageSubnet" BO_ 1568 0;
BA_ "GenMsgCycleTime" BO_ 1568 3000;
BA_ "GenMsgSendType" BO_ 1568 0;
BA_ "NmMessage" BO_ 1568 1;
BA_ "Prio" BO_ 1570 0;
BA_ "MessageSubnet" BO_ 1570 0;
BA_ "GenMsgCycleTime" BO_ 1570 3000;
BA_ "GenMsgSendType" BO_ 1570 0;
BA_ "NmMessage" BO_ 1570 1;
BA_ "MessageSubnet" BO_ 2162982912 0;
BA_ "GenMsgStartDelayTime" BO_ 2162982912 200;
BA_ "GenMsgCycleTime" BO_ 2162982912 5000;
BA_ "GenMsgSendType" BO_ 2162982912 0;
BA_ "MessageSubnet" BO_ 2162966528 0;
BA_ "GenMsgStartDelayTime" BO_ 2162966528 190;
BA_ "GenMsgCycleTime" BO_ 2162966528 5000;
BA_ "GenMsgSendType" BO_ 2162966528 0;
BA_ "MessageSubnet" BO_ 2151497728 0;
BA_ "GenMsgDelayTime" BO_ 2151497728 100;
BA_ "Prio" BO_ 2151219200 3;
BA_ "MessageSubnet" BO_ 2151219200 0;
BA_ "GenMsgDelayTime" BO_ 2151219200 100;
BA_ "MessageSubnet" BO_ 2153775104 0;
BA_ "GenMsgDelayTime" BO_ 2153775104 1000;
BA_ "GenSigSendType" SG_ 2154905600 DrvSeatPrsMemID 10;
BA_ "SignalType" SG_ 2154905600 DrvSeatPrsMemID "ENM";
BA_ "SignalLongName" SG_ 2154905600 DrvSeatPrsMemID "Driver Seat Personalization Memory ID";
BA_ "GenSigStartValue" SG_ 2154905600 DrvSeatPrsMemID 7;
BA_ "VNSigAllNodes" SG_ 2154905600 DrvSeatPrsMemID 1;
BA_ "GenSigSendType" SG_ 2154905600 DrId 10;
BA_ "GenSigSendOnInit" SG_ 2154905600 DrId 1;
BA_ "VNSigInfotainment" SG_ 2154905600 DrId 1;
BA_ "SignalType" SG_ 2154905600 DrId "ENM";
BA_ "SignalLongName" SG_ 2154905600 DrId "Driver Identifier";
BA_ "GenSigStartValue" SG_ 2154905600 DrId 7;
BA_ "VNSigAllNodes" SG_ 2154905600 DrId 1;
BA_ "GenSigDeltaValue" SG_ 2154954752 ACCWPwrdRmStPwrLmt 1;
BA_ "GenSigSendType" SG_ 2154954752 ACCWPwrdRmStPwrLmt 12;
BA_ "SignalType" SG_ 2154954752 ACCWPwrdRmStPwrLmt "UNM";
BA_ "SignalLongName" SG_ 2154954752 ACCWPwrdRmStPwrLmt "Air Conditioning Compressor Wall Powered Remote Start Power Limit";
BA_ "VNSigAllNodes" SG_ 2154954752 ACCWPwrdRmStPwrLmt 1;
BA_ "GenSigSendType" SG_ 2154954752 WPwrdRmStEnbld 10;
BA_ "SignalType" SG_ 2154954752 WPwrdRmStEnbld "BLN";
BA_ "SignalLongName" SG_ 2154954752 WPwrdRmStEnbld "Wall Powered Remote Start Enabled";
BA_ "VNSigAllNodes" SG_ 2154954752 WPwrdRmStEnbld 1;
BA_ "GenSigSendType" SG_ 2154954752 HtdStWhlInd 10;
BA_ "SignalType" SG_ 2154954752 HtdStWhlInd "ENM";
BA_ "SignalLongName" SG_ 2154954752 HtdStWhlInd "Heated Steering Wheel Indication";
BA_ "VNSigAllNodes" SG_ 2154954752 HtdStWhlInd 1;
BA_ "GenSigSendType" SG_ 2154954752 HtdStWhlCtrlSrc 10;
BA_ "SignalType" SG_ 2154954752 HtdStWhlCtrlSrc "ENM";
BA_ "SignalLongName" SG_ 2154954752 HtdStWhlCtrlSrc "Heated Steering Wheel Control Source";
BA_ "VNSigAllNodes" SG_ 2154954752 HtdStWhlCtrlSrc 1;
BA_ "GenSigSendType" SG_ 2154954752 HtdStWhlCmd 10;
BA_ "SignalType" SG_ 2154954752 HtdStWhlCmd "ENM";
BA_ "SignalLongName" SG_ 2154954752 HtdStWhlCmd "Heated Steering Wheel Command";
BA_ "VNSigAllNodes" SG_ 2154954752 HtdStWhlCmd 1;
BA_ "GenSigSendType" SG_ 2154954752 ClmtHtPwrRqd 10;
BA_ "SignalType" SG_ 2154954752 ClmtHtPwrRqd "BLN";
BA_ "SignalLongName" SG_ 2154954752 ClmtHtPwrRqd "Climate Heating Power Required";
BA_ "VNSigAllNodes" SG_ 2154954752 ClmtHtPwrRqd 1;
BA_ "GenSigDeltaValue" SG_ 2154954752 EstACCompPwrRchCbnCmf 1;
BA_ "GenSigSendType" SG_ 2154954752 EstACCompPwrRchCbnCmf 12;
BA_ "SignalType" SG_ 2154954752 EstACCompPwrRchCbnCmf "UNM";
BA_ "SignalLongName" SG_ 2154954752 EstACCompPwrRchCbnCmf "Estimated Air Conditioning Control Power to Reach Cabin Comfort";
BA_ "VNSigAllNodes" SG_ 2154954752 EstACCompPwrRchCbnCmf 1;
BA_ "GenSigDeltaValue" SG_ 2154954752 EstACCompPwrMtnCbnCmf 1;
BA_ "GenSigSendType" SG_ 2154954752 EstACCompPwrMtnCbnCmf 12;
BA_ "SignalType" SG_ 2154954752 EstACCompPwrMtnCbnCmf "UNM";
BA_ "SignalLongName" SG_ 2154954752 EstACCompPwrMtnCbnCmf "Estimated Air Conditioning Control Power to Maintain Cabin Comfort";
BA_ "VNSigAllNodes" SG_ 2154954752 EstACCompPwrMtnCbnCmf 1;
BA_ "GenSigSendType" SG_ 2153381888 VltActRrAccUnavlIO 10;
BA_ "SignalType" SG_ 2153381888 VltActRrAccUnavlIO "BLN";
BA_ "SignalLongName" SG_ 2153381888 VltActRrAccUnavlIO "Valet Active Rear Access Unavailable Indication On";
BA_ "VNSigAllNodes" SG_ 2153381888 VltActRrAccUnavlIO 1;
BA_ "GenSigSendType" SG_ 2153381888 PwrLftgtMotStat 10;
BA_ "SignalType" SG_ 2153381888 PwrLftgtMotStat "ENM";
BA_ "SignalLongName" SG_ 2153381888 PwrLftgtMotStat "Power Liftgate Motion Status";
BA_ "VNSigAllNodes" SG_ 2153381888 PwrLftgtMotStat 1;
BA_ "GenSigSendType" SG_ 2153381888 GrgPrgMdCmpl 10;
BA_ "GenSigSendOnInit" SG_ 2153381888 GrgPrgMdCmpl 1;
BA_ "SignalType" SG_ 2153381888 GrgPrgMdCmpl "BLN";
BA_ "SignalLongName" SG_ 2153381888 GrgPrgMdCmpl "Garage Programming Mode Complete";
BA_ "VNSigAllNodes" SG_ 2153381888 GrgPrgMdCmpl 1;
BA_ "GenSigDeltaValue" SG_ 2153381888 VehIncAngEst 1;
BA_ "GenSigSendType" SG_ 2153381888 VehIncAngEst 12;
BA_ "SignalType" SG_ 2153381888 VehIncAngEst "UNM";
BA_ "SignalLongName" SG_ 2153381888 VehIncAngEst "Vehicle Inclination Angle Estimated";
BA_ "VNSigAllNodes" SG_ 2153381888 VehIncAngEst 1;
BA_ "GenSigSendType" SG_ 2153381888 PwrLftgtInclAngV 10;
BA_ "GenSigSendOnInit" SG_ 2153381888 PwrLftgtInclAngV 1;
BA_ "VNSigParkedVehicle" SG_ 2153381888 PwrLftgtInclAngV 1;
BA_ "SignalType" SG_ 2153381888 PwrLftgtInclAngV "ENM";
BA_ "SignalLongName" SG_ 2153381888 PwrLftgtInclAngV "Power Liftgate Inclination Angle Validity";
BA_ "VNSigAllNodes" SG_ 2153381888 PwrLftgtInclAngV 1;
BA_ "GenSigSendType" SG_ 2153381888 RrClsrObstclDtctd 10;
BA_ "GenSigSendOnInit" SG_ 2153381888 RrClsrObstclDtctd 1;
BA_ "SignalType" SG_ 2153381888 RrClsrObstclDtctd "BLN";
BA_ "SignalLongName" SG_ 2153381888 RrClsrObstclDtctd "Rear Closure Obstacle Detected";
BA_ "VNSigAllNodes" SG_ 2153381888 RrClsrObstclDtctd 1;
BA_ "GenSigSendType" SG_ 2153381888 FnshRrClsrMtnBfrDrvIO 10;
BA_ "GenSigSendOnInit" SG_ 2153381888 FnshRrClsrMtnBfrDrvIO 1;
BA_ "SignalType" SG_ 2153381888 FnshRrClsrMtnBfrDrvIO "BLN";
BA_ "SignalLongName" SG_ 2153381888 FnshRrClsrMtnBfrDrvIO "Finish Rear Closure Motion Before Driving Indication On";
BA_ "VNSigAllNodes" SG_ 2153381888 FnshRrClsrMtnBfrDrvIO 1;
BA_ "GenSigDeltaValue" SG_ 2153381888 PwrLftgtInclAng 1;
BA_ "GenSigSendType" SG_ 2153381888 PwrLftgtInclAng 12;
BA_ "GenSigSendOnInit" SG_ 2153381888 PwrLftgtInclAng 1;
BA_ "VNSigParkedVehicle" SG_ 2153381888 PwrLftgtInclAng 1;
BA_ "SignalType" SG_ 2153381888 PwrLftgtInclAng "UNM";
BA_ "SignalLongName" SG_ 2153381888 PwrLftgtInclAng "Power Liftgate Inclination Angle";
BA_ "VNSigAllNodes" SG_ 2153381888 PwrLftgtInclAng 1;
BA_ "GenSigSendType" SG_ 2153381888 RrClosOpenSwAct 10;
BA_ "GenSigSendOnInit" SG_ 2153381888 RrClosOpenSwAct 1;
BA_ "SignalType" SG_ 2153381888 RrClosOpenSwAct "BLN";
BA_ "SignalLongName" SG_ 2153381888 RrClosOpenSwAct "Rear Closure Open Switch Active";
BA_ "VNSigAllNodes" SG_ 2153381888 RrClosOpenSwAct 1;
BA_ "GenSigSendType" SG_ 2153381888 RrClosOpenSwActV 10;
BA_ "SignalType" SG_ 2153381888 RrClosOpenSwActV "ENM";
BA_ "SignalLongName" SG_ 2153381888 RrClosOpenSwActV "Rear Closure Open Switch Active Validity";
BA_ "VNSigAllNodes" SG_ 2153381888 RrClosOpenSwActV 1;
BA_ "GenSigSendType" SG_ 2153381888 RrClsrInMtn 10;
BA_ "GenSigSendOnInit" SG_ 2153381888 RrClsrInMtn 1;
BA_ "SignalType" SG_ 2153381888 RrClsrInMtn "BLN";
BA_ "SignalLongName" SG_ 2153381888 RrClsrInMtn "Rear Closure In Motion";
BA_ "VNSigAllNodes" SG_ 2153381888 RrClsrInMtn 1;
BA_ "GenSigSendType" SG_ 2153381888 RrWprInhbRq 10;
BA_ "SignalType" SG_ 2153381888 RrWprInhbRq "BLN";
BA_ "SignalLongName" SG_ 2153381888 RrWprInhbRq "Rear Wiper Inhibit Request";
BA_ "VNSigAllNodes" SG_ 2153381888 RrWprInhbRq 1;
BA_ "SignalType" SG_ 2149752832 SndEnhcmtPerfMdRq "ENM";
BA_ "SignalLongName" SG_ 2149752832 SndEnhcmtPerfMdRq "Sound Enhancement Performance Mode Request";
BA_ "VNSigAllNodes" SG_ 2149752832 SndEnhcmtPerfMdRq 1;
BA_ "SignalType" SG_ 2149752832 SndPerfMdCsStAvl "BLN";
BA_ "SignalLongName" SG_ 2149752832 SndPerfMdCsStAvl "Sound Performance Mode Customization Setting Available";
BA_ "VNSigAllNodes" SG_ 2149752832 SndPerfMdCsStAvl 1;
BA_ "SignalType" SG_ 2149752832 SndPerfMdCsCrStVal "ENM";
BA_ "SignalLongName" SG_ 2149752832 SndPerfMdCsCrStVal "Sound Performance Mode Customization Current Setting Value";
BA_ "VNSigAllNodes" SG_ 2149752832 SndPerfMdCsCrStVal 1;
BA_ "SignalType" SG_ 2149752832 DispPerfMdCsStAvl "BLN";
BA_ "SignalLongName" SG_ 2149752832 DispPerfMdCsStAvl "Display Performance Mode Customization Setting Available";
BA_ "VNSigAllNodes" SG_ 2149752832 DispPerfMdCsStAvl 1;
BA_ "SignalType" SG_ 2149752832 DispPerfMdCsCrStVal "ENM";
BA_ "SignalLongName" SG_ 2149752832 DispPerfMdCsCrStVal "Display Performance Mode Customization Current Setting Value";
BA_ "VNSigAllNodes" SG_ 2149752832 DispPerfMdCsCrStVal 1;
BA_ "SignalType" SG_ 2149752832 HlStrAssActIO "BLN";
BA_ "SignalLongName" SG_ 2149752832 HlStrAssActIO "Hill Start Assist Active Indication On";
BA_ "VNSigAllNodes" SG_ 2149752832 HlStrAssActIO 1;
BA_ "SignalType" SG_ 2149752832 GNCustSetngAvlbl "BLN";
BA_ "SignalLongName" SG_ 2149752832 GNCustSetngAvlbl "Go Notifier Customization Setting Available";
BA_ "VNSigAllNodes" SG_ 2149752832 GNCustSetngAvlbl 1;
BA_ "SignalType" SG_ 2149752832 GNCustCrntStngVal "ENM";
BA_ "SignalLongName" SG_ 2149752832 GNCustCrntStngVal "Go Notifier Customization Current Setting Value";
BA_ "VNSigAllNodes" SG_ 2149752832 GNCustCrntStngVal 1;
BA_ "SignalType" SG_ 2149752832 CPSInfotmntMtReq "ENM";
BA_ "SignalLongName" SG_ 2149752832 CPSInfotmntMtReq "Collision Preparation System Infotainment Mute Request";
BA_ "VNSigAllNodes" SG_ 2149752832 CPSInfotmntMtReq 1;
BA_ "SignalType" SG_ 2149752832 ColPrSysStngAvl "BLN";
BA_ "SignalLongName" SG_ 2149752832 ColPrSysStngAvl "Collision Preparation System Setting Available";
BA_ "VNSigAllNodes" SG_ 2149752832 ColPrSysStngAvl 1;
BA_ "SignalType" SG_ 2149752832 ColPrSysCrntStng "ENM";
BA_ "SignalLongName" SG_ 2149752832 ColPrSysCrntStng "Collision Preparation System Current Setting Value";
BA_ "VNSigAllNodes" SG_ 2149752832 ColPrSysCrntStng 1;
BA_ "SignalType" SG_ 2149752832 HillDscntCntlSysStat "ENM";
BA_ "SignalLongName" SG_ 2149752832 HillDscntCntlSysStat "Hill Descent Control System Status";
BA_ "VNSigAllNodes" SG_ 2149752832 HillDscntCntlSysStat 1;
BA_ "SignalType" SG_ 2149752832 ElecPrkBrkStat "ENM";
BA_ "SignalLongName" SG_ 2149752832 ElecPrkBrkStat "Electric Park Brake Status";
BA_ "VNSigAllNodes" SG_ 2149752832 ElecPrkBrkStat 1;
BA_ "SignalType" SG_ 2149752832 EBDFailed "BLN";
BA_ "SignalLongName" SG_ 2149752832 EBDFailed "Electronic Brake Distribution Failed";
BA_ "VNSigAllNodes" SG_ 2149752832 EBDFailed 1;
BA_ "SignalType" SG_ 2149752832 SusCustStngAvlbl "BLN";
BA_ "SignalLongName" SG_ 2149752832 SusCustStngAvlbl "Suspension Customization Setting Available";
BA_ "VNSigAllNodes" SG_ 2149752832 SusCustStngAvlbl 1;
BA_ "SignalType" SG_ 2149752832 SusCustCurrStngVal "ENM";
BA_ "SignalLongName" SG_ 2149752832 SusCustCurrStngVal "Suspension Customization Current Setting Value";
BA_ "VNSigAllNodes" SG_ 2149752832 SusCustCurrStngVal 1;
BA_ "SignalType" SG_ 2149752832 StrCustStngAvlbl "BLN";
BA_ "SignalLongName" SG_ 2149752832 StrCustStngAvlbl "Steering Customization Setting Available";
BA_ "VNSigAllNodes" SG_ 2149752832 StrCustStngAvlbl 1;
BA_ "SignalType" SG_ 2149752832 StrCustCurrStngVal "ENM";
BA_ "SignalLongName" SG_ 2149752832 StrCustCurrStngVal "Steering Customization Current Setting Value";
BA_ "VNSigAllNodes" SG_ 2149752832 StrCustCurrStngVal 1;
BA_ "SignalType" SG_ 2149752832 DrvlnCustStngAvlbl "BLN";
BA_ "SignalLongName" SG_ 2149752832 DrvlnCustStngAvlbl "Driveline Customization Setting Available";
BA_ "VNSigAllNodes" SG_ 2149752832 DrvlnCustStngAvlbl 1;
BA_ "SignalType" SG_ 2149752832 DrvlnCustCurrStngVal "ENM";
BA_ "SignalLongName" SG_ 2149752832 DrvlnCustCurrStngVal "Driveline Customization Current Setting Value";
BA_ "VNSigAllNodes" SG_ 2149752832 DrvlnCustCurrStngVal 1;
BA_ "SignalType" SG_ 2149752832 ABSAtv "BLN";
BA_ "SignalLongName" SG_ 2149752832 ABSAtv "Antilock Brake System Active";
BA_ "VNSigAllNodes" SG_ 2149752832 ABSAtv 1;
BA_ "SignalType" SG_ 2149752832 PowStVDA "ENM";
BA_ "SignalLongName" SG_ 2149752832 PowStVDA "Power Steering Virtual Device Availability";
BA_ "GenSigStartValue" SG_ 2149752832 PowStVDA 1;
BA_ "VNSigAllNodes" SG_ 2149752832 PowStVDA 1;
BA_ "SignalType" SG_ 2149752832 RrDrCntVDA "ENM";
BA_ "SignalLongName" SG_ 2149752832 RrDrCntVDA "Rear Drive Control Virtual Device Availability";
BA_ "GenSigStartValue" SG_ 2149752832 RrDrCntVDA 1;
BA_ "VNSigAllNodes" SG_ 2149752832 RrDrCntVDA 1;
BA_ "SignalType" SG_ 2149752832 SprTireSt "ENM";
BA_ "SignalLongName" SG_ 2149752832 SprTireSt "Spare Tire Status";
BA_ "VNSigAllNodes" SG_ 2149752832 SprTireSt 1;
BA_ "SignalType" SG_ 2149752832 VehHghtStatV "ENM";
BA_ "SignalLongName" SG_ 2149752832 VehHghtStatV "Vehicle Height Status Validity";
BA_ "VNSigAllNodes" SG_ 2149752832 VehHghtStatV 1;
BA_ "SignalType" SG_ 2149752832 VehHghtStat "ENM";
BA_ "SignalLongName" SG_ 2149752832 VehHghtStat "Vehicle Height Status";
BA_ "VNSigAllNodes" SG_ 2149752832 VehHghtStat 1;
BA_ "SignalType" SG_ 2149752832 BrkSysVDA "ENM";
BA_ "SignalLongName" SG_ 2149752832 BrkSysVDA "Brake System Virtual Device Availability";
BA_ "GenSigStartValue" SG_ 2149752832 BrkSysVDA 1;
BA_ "VNSigAllNodes" SG_ 2149752832 BrkSysVDA 1;
BA_ "SignalType" SG_ 2149752832 IntBrkAssPreFilReq "BLN";
BA_ "SignalLongName" SG_ 2149752832 IntBrkAssPreFilReq "Inteligent Brake Assist Pre-Fil Request";
BA_ "VNSigAllNodes" SG_ 2149752832 IntBrkAssPreFilReq 1;
BA_ "SignalType" SG_ 2149752832 EPBSysDspMsgReq "ENM";
BA_ "SignalLongName" SG_ 2149752832 EPBSysDspMsgReq "Electric Park Brake System Display Message Request";
BA_ "VNSigAllNodes" SG_ 2149752832 EPBSysDspMsgReq 1;
BA_ "SignalType" SG_ 2149752832 EPBSysAudWarnReq "ENM";
BA_ "SignalLongName" SG_ 2149752832 EPBSysAudWarnReq "Electric Park Brake System Audible Warning Request";
BA_ "VNSigAllNodes" SG_ 2149752832 EPBSysAudWarnReq 1;
BA_ "SignalType" SG_ 2149752832 BksOvht "BLN";
BA_ "SignalLongName" SG_ 2149752832 BksOvht "Brakes Overheated";
BA_ "VNSigAllNodes" SG_ 2149752832 BksOvht 1;
BA_ "SignalType" SG_ 2149752832 BrkSysRedBrkTlltlReq "BLN";
BA_ "SignalLongName" SG_ 2149752832 BrkSysRedBrkTlltlReq "Brake System Red Brake Telltale Request";
BA_ "VNSigAllNodes" SG_ 2149752832 BrkSysRedBrkTlltlReq 1;
BA_ "SignalType" SG_ 2149752832 HalfSysFail "BLN";
BA_ "SignalLongName" SG_ 2149752832 HalfSysFail "Half System Failure";
BA_ "VNSigAllNodes" SG_ 2149752832 HalfSysFail 1;
BA_ "SignalType" SG_ 2149752832 PrkBrkVDA "ENM";
BA_ "SignalLongName" SG_ 2149752832 PrkBrkVDA "Park Brake Virtual Device Availability";
BA_ "GenSigStartValue" SG_ 2149752832 PrkBrkVDA 1;
BA_ "VNSigAllNodes" SG_ 2149752832 PrkBrkVDA 1;
BA_ "GenSigSendType" SG_ 2151514112 EngOilLfRstRq 10;
BA_ "SignalType" SG_ 2151514112 EngOilLfRstRq "BLN";
BA_ "SignalLongName" SG_ 2151514112 EngOilLfRstRq "Engine Oil Life Reset Request";
BA_ "VNSigAllNodes" SG_ 2151514112 EngOilLfRstRq 1;
BA_ "GenSigSendType" SG_ 2158903296 ODDMA_ReqType 10;
BA_ "VNSigInfotainment" SG_ 2158903296 ODDMA_ReqType 1;
BA_ "SignalType" SG_ 2158903296 ODDMA_ReqType "ENM";
BA_ "PacketOrder" SG_ 2158903296 ODDMA_ReqType 1;
BA_ "SignalLongName" SG_ 2158903296 ODDMA_ReqType "Open Display Interface Dynamic Data Multi Request Auxiliary IP : Request Type";
BA_ "VNSigAllNodes" SG_ 2158903296 ODDMA_ReqType 1;
BA_ "GenSigDeltaValue" SG_ 2158903296 ODDMA_FUCID 1;
BA_ "GenSigSendType" SG_ 2158903296 ODDMA_FUCID 12;
BA_ "VNSigInfotainment" SG_ 2158903296 ODDMA_FUCID 1;
BA_ "SignalType" SG_ 2158903296 ODDMA_FUCID "UNM";
BA_ "PacketOrder" SG_ 2158903296 ODDMA_FUCID 6;
BA_ "SignalLongName" SG_ 2158903296 ODDMA_FUCID "Open Display Interface Dynamic Data Multi Request Auxiliary IP : Functional Unit Class ID";
BA_ "VNSigAllNodes" SG_ 2158903296 ODDMA_FUCID 1;
BA_ "GenSigSendType" SG_ 2158903296 ODDMA_DispMID 10;
BA_ "VNSigInfotainment" SG_ 2158903296 ODDMA_DispMID 1;
BA_ "SignalType" SG_ 2158903296 ODDMA_DispMID "ENM";
BA_ "PacketOrder" SG_ 2158903296 ODDMA_DispMID 7;
BA_ "SignalLongName" SG_ 2158903296 ODDMA_DispMID "Open Display Interface Dynamic Data Multi Request Auxiliary IP : Display Mask Id";
BA_ "VNSigAllNodes" SG_ 2158903296 ODDMA_DispMID 1;
BA_ "GenSigSendType" SG_ 2158903296 ODDMA_DataID2Vld 10;
BA_ "VNSigInfotainment" SG_ 2158903296 ODDMA_DataID2Vld 1;
BA_ "SignalType" SG_ 2158903296 ODDMA_DataID2Vld "BLN";
BA_ "PacketOrder" SG_ 2158903296 ODDMA_DataID2Vld 5;
BA_ "SignalLongName" SG_ 2158903296 ODDMA_DataID2Vld "Open Display Interface Dynamic Data Multi Request Auxiliary IP : Data ID Two Valid";
BA_ "VNSigAllNodes" SG_ 2158903296 ODDMA_DataID2Vld 1;
BA_ "GenSigDeltaValue" SG_ 2158903296 ODDMA_DataID2 1;
BA_ "GenSigSendType" SG_ 2158903296 ODDMA_DataID2 12;
BA_ "VNSigInfotainment" SG_ 2158903296 ODDMA_DataID2 1;
BA_ "SignalType" SG_ 2158903296 ODDMA_DataID2 "UNM";
BA_ "PacketOrder" SG_ 2158903296 ODDMA_DataID2 9;
BA_ "SignalLongName" SG_ 2158903296 ODDMA_DataID2 "Open Display Interface Dynamic Data Multi Request Auxiliary IP : Data ID Two";
BA_ "VNSigAllNodes" SG_ 2158903296 ODDMA_DataID2 1;
BA_ "GenSigSendType" SG_ 2158903296 ODDMA_DataID3Vld 10;
BA_ "VNSigInfotainment" SG_ 2158903296 ODDMA_DataID3Vld 1;
BA_ "SignalType" SG_ 2158903296 ODDMA_DataID3Vld "BLN";
BA_ "PacketOrder" SG_ 2158903296 ODDMA_DataID3Vld 4;
BA_ "SignalLongName" SG_ 2158903296 ODDMA_DataID3Vld "Open Display Interface Dynamic Data Multi Request Auxiliary IP : Data ID Three Valid";
BA_ "VNSigAllNodes" SG_ 2158903296 ODDMA_DataID3Vld 1;
BA_ "GenSigDeltaValue" SG_ 2158903296 ODDMA_DataID3 1;
BA_ "GenSigSendType" SG_ 2158903296 ODDMA_DataID3 12;
BA_ "VNSigInfotainment" SG_ 2158903296 ODDMA_DataID3 1;
BA_ "SignalType" SG_ 2158903296 ODDMA_DataID3 "UNM";
BA_ "PacketOrder" SG_ 2158903296 ODDMA_DataID3 10;
BA_ "SignalLongName" SG_ 2158903296 ODDMA_DataID3 "Open Display Interface Dynamic Data Multi Request Auxiliary IP : Data ID Three";
BA_ "VNSigAllNodes" SG_ 2158903296 ODDMA_DataID3 1;
BA_ "GenSigDeltaValue" SG_ 2158903296 ODDMA_DataID1 1;
BA_ "GenSigSendType" SG_ 2158903296 ODDMA_DataID1 12;
BA_ "VNSigInfotainment" SG_ 2158903296 ODDMA_DataID1 1;
BA_ "SignalType" SG_ 2158903296 ODDMA_DataID1 "UNM";
BA_ "PacketOrder" SG_ 2158903296 ODDMA_DataID1 8;
BA_ "SignalLongName" SG_ 2158903296 ODDMA_DataID1 "Open Display Interface Dynamic Data Multi Request Auxiliary IP : Data ID One";
BA_ "VNSigAllNodes" SG_ 2158903296 ODDMA_DataID1 1;
BA_ "GenSigSendType" SG_ 2158903296 ODDMA_DataID4Vld 10;
BA_ "VNSigInfotainment" SG_ 2158903296 ODDMA_DataID4Vld 1;
BA_ "SignalType" SG_ 2158903296 ODDMA_DataID4Vld "BLN";
BA_ "PacketOrder" SG_ 2158903296 ODDMA_DataID4Vld 3;
BA_ "SignalLongName" SG_ 2158903296 ODDMA_DataID4Vld "Open Display Interface Dynamic Data Multi Request Auxiliary IP : Data ID Four Valid";
BA_ "VNSigAllNodes" SG_ 2158903296 ODDMA_DataID4Vld 1;
BA_ "GenSigDeltaValue" SG_ 2158903296 ODDMA_DataID4 1;
BA_ "GenSigSendType" SG_ 2158903296 ODDMA_DataID4 12;
BA_ "VNSigInfotainment" SG_ 2158903296 ODDMA_DataID4 1;
BA_ "SignalType" SG_ 2158903296 ODDMA_DataID4 "UNM";
BA_ "PacketOrder" SG_ 2158903296 ODDMA_DataID4 11;
BA_ "SignalLongName" SG_ 2158903296 ODDMA_DataID4 "Open Display Interface Dynamic Data Multi Request Auxiliary IP : Data ID Four";
BA_ "VNSigAllNodes" SG_ 2158903296 ODDMA_DataID4 1;
BA_ "GenSigSendType" SG_ 2158903296 ODDMA_DataID5Vld 10;
BA_ "VNSigInfotainment" SG_ 2158903296 ODDMA_DataID5Vld 1;
BA_ "SignalType" SG_ 2158903296 ODDMA_DataID5Vld "BLN";
BA_ "PacketOrder" SG_ 2158903296 ODDMA_DataID5Vld 2;
BA_ "SignalLongName" SG_ 2158903296 ODDMA_DataID5Vld "Open Display Interface Dynamic Data Multi Request Auxiliary IP : Data ID Five Valid";
BA_ "VNSigAllNodes" SG_ 2158903296 ODDMA_DataID5Vld 1;
BA_ "GenSigDeltaValue" SG_ 2158903296 ODDMA_DataID5 1;
BA_ "GenSigSendType" SG_ 2158903296 ODDMA_DataID5 12;
BA_ "VNSigInfotainment" SG_ 2158903296 ODDMA_DataID5 1;
BA_ "SignalType" SG_ 2158903296 ODDMA_DataID5 "UNM";
BA_ "PacketOrder" SG_ 2158903296 ODDMA_DataID5 12;
BA_ "SignalLongName" SG_ 2158903296 ODDMA_DataID5 "Open Display Interface Dynamic Data Multi Request Auxiliary IP : Data ID Five";
BA_ "VNSigAllNodes" SG_ 2158903296 ODDMA_DataID5 1;
BA_ "GenSigSendType" SG_ 2158911488 ODDMC_ReqType 10;
BA_ "VNSigInfotainment" SG_ 2158911488 ODDMC_ReqType 1;
BA_ "SignalType" SG_ 2158911488 ODDMC_ReqType "ENM";
BA_ "PacketOrder" SG_ 2158911488 ODDMC_ReqType 1;
BA_ "SignalLongName" SG_ 2158911488 ODDMC_ReqType "Open Display Interface Dynamic Data Multi Request CenterStack : Request Type";
BA_ "VNSigAllNodes" SG_ 2158911488 ODDMC_ReqType 1;
BA_ "GenSigSendType" SG_ 2158911488 ODDMC_DispMID 10;
BA_ "VNSigInfotainment" SG_ 2158911488 ODDMC_DispMID 1;
BA_ "SignalType" SG_ 2158911488 ODDMC_DispMID "ENM";
BA_ "PacketOrder" SG_ 2158911488 ODDMC_DispMID 7;
BA_ "SignalLongName" SG_ 2158911488 ODDMC_DispMID "Open Display Interface Dynamic Data Multi Request CenterStack : Display Mask Id";
BA_ "VNSigAllNodes" SG_ 2158911488 ODDMC_DispMID 1;
BA_ "GenSigSendType" SG_ 2158911488 ODDMC_DataID2Vld 10;
BA_ "VNSigInfotainment" SG_ 2158911488 ODDMC_DataID2Vld 1;
BA_ "SignalType" SG_ 2158911488 ODDMC_DataID2Vld "BLN";
BA_ "PacketOrder" SG_ 2158911488 ODDMC_DataID2Vld 5;
BA_ "SignalLongName" SG_ 2158911488 ODDMC_DataID2Vld "Open Display Interface Dynamic Data Multi Request CenterStack : Data ID Two Valid";
BA_ "VNSigAllNodes" SG_ 2158911488 ODDMC_DataID2Vld 1;
BA_ "GenSigDeltaValue" SG_ 2158911488 ODDMC_DataID2 1;
BA_ "GenSigSendType" SG_ 2158911488 ODDMC_DataID2 12;
BA_ "VNSigInfotainment" SG_ 2158911488 ODDMC_DataID2 1;
BA_ "SignalType" SG_ 2158911488 ODDMC_DataID2 "UNM";
BA_ "PacketOrder" SG_ 2158911488 ODDMC_DataID2 9;
BA_ "SignalLongName" SG_ 2158911488 ODDMC_DataID2 "Open Display Interface Dynamic Data Multi Request CenterStack : Data ID Two";
BA_ "VNSigAllNodes" SG_ 2158911488 ODDMC_DataID2 1;
BA_ "GenSigSendType" SG_ 2158911488 ODDMC_DataID3Vld 10;
BA_ "VNSigInfotainment" SG_ 2158911488 ODDMC_DataID3Vld 1;
BA_ "SignalType" SG_ 2158911488 ODDMC_DataID3Vld "BLN";
BA_ "PacketOrder" SG_ 2158911488 ODDMC_DataID3Vld 4;
BA_ "SignalLongName" SG_ 2158911488 ODDMC_DataID3Vld "Open Display Interface Dynamic Data Multi Request CenterStack : Data ID Three Valid";
BA_ "VNSigAllNodes" SG_ 2158911488 ODDMC_DataID3Vld 1;
BA_ "GenSigDeltaValue" SG_ 2158911488 ODDMC_DataID3 1;
BA_ "GenSigSendType" SG_ 2158911488 ODDMC_DataID3 12;
BA_ "VNSigInfotainment" SG_ 2158911488 ODDMC_DataID3 1;
BA_ "SignalType" SG_ 2158911488 ODDMC_DataID3 "UNM";
BA_ "PacketOrder" SG_ 2158911488 ODDMC_DataID3 10;
BA_ "SignalLongName" SG_ 2158911488 ODDMC_DataID3 "Open Display Interface Dynamic Data Multi Request CenterStack : Data ID Three";
BA_ "VNSigAllNodes" SG_ 2158911488 ODDMC_DataID3 1;
BA_ "GenSigDeltaValue" SG_ 2158911488 ODDMC_DataID1 1;
BA_ "GenSigSendType" SG_ 2158911488 ODDMC_DataID1 12;
BA_ "VNSigInfotainment" SG_ 2158911488 ODDMC_DataID1 1;
BA_ "SignalType" SG_ 2158911488 ODDMC_DataID1 "UNM";
BA_ "PacketOrder" SG_ 2158911488 ODDMC_DataID1 8;
BA_ "SignalLongName" SG_ 2158911488 ODDMC_DataID1 "Open Display Interface Dynamic Data Multi Request CenterStack : Data ID One";
BA_ "VNSigAllNodes" SG_ 2158911488 ODDMC_DataID1 1;
BA_ "GenSigSendType" SG_ 2158911488 ODDMC_DataID4Vld 10;
BA_ "VNSigInfotainment" SG_ 2158911488 ODDMC_DataID4Vld 1;
BA_ "SignalType" SG_ 2158911488 ODDMC_DataID4Vld "BLN";
BA_ "PacketOrder" SG_ 2158911488 ODDMC_DataID4Vld 3;
BA_ "SignalLongName" SG_ 2158911488 ODDMC_DataID4Vld "Open Display Interface Dynamic Data Multi Request CenterStack : Data ID Four Valid";
BA_ "VNSigAllNodes" SG_ 2158911488 ODDMC_DataID4Vld 1;
BA_ "GenSigDeltaValue" SG_ 2158911488 ODDMC_DataID4 1;
BA_ "GenSigSendType" SG_ 2158911488 ODDMC_DataID4 12;
BA_ "VNSigInfotainment" SG_ 2158911488 ODDMC_DataID4 1;
BA_ "SignalType" SG_ 2158911488 ODDMC_DataID4 "UNM";
BA_ "PacketOrder" SG_ 2158911488 ODDMC_DataID4 11;
BA_ "SignalLongName" SG_ 2158911488 ODDMC_DataID4 "Open Display Interface Dynamic Data Multi Request CenterStack : Data ID Four";
BA_ "VNSigAllNodes" SG_ 2158911488 ODDMC_DataID4 1;
BA_ "GenSigSendType" SG_ 2158911488 ODDMC_DataID5Vld 10;
BA_ "VNSigInfotainment" SG_ 2158911488 ODDMC_DataID5Vld 1;
BA_ "SignalType" SG_ 2158911488 ODDMC_DataID5Vld "BLN";
BA_ "PacketOrder" SG_ 2158911488 ODDMC_DataID5Vld 2;
BA_ "SignalLongName" SG_ 2158911488 ODDMC_DataID5Vld "Open Display Interface Dynamic Data Multi Request CenterStack : Data ID Five Valid";
BA_ "VNSigAllNodes" SG_ 2158911488 ODDMC_DataID5Vld 1;
BA_ "GenSigDeltaValue" SG_ 2158911488 ODDMC_DataID5 1;
BA_ "GenSigSendType" SG_ 2158911488 ODDMC_DataID5 12;
BA_ "VNSigInfotainment" SG_ 2158911488 ODDMC_DataID5 1;
BA_ "SignalType" SG_ 2158911488 ODDMC_DataID5 "UNM";
BA_ "PacketOrder" SG_ 2158911488 ODDMC_DataID5 12;
BA_ "SignalLongName" SG_ 2158911488 ODDMC_DataID5 "Open Display Interface Dynamic Data Multi Request CenterStack : Data ID Five";
BA_ "VNSigAllNodes" SG_ 2158911488 ODDMC_DataID5 1;
BA_ "GenSigDeltaValue" SG_ 2158911488 ODDMC_FUCID 1;
BA_ "GenSigSendType" SG_ 2158911488 ODDMC_FUCID 12;
BA_ "VNSigInfotainment" SG_ 2158911488 ODDMC_FUCID 1;
BA_ "SignalType" SG_ 2158911488 ODDMC_FUCID "UNM";
BA_ "PacketOrder" SG_ 2158911488 ODDMC_FUCID 6;
BA_ "SignalLongName" SG_ 2158911488 ODDMC_FUCID "Open Display Interface Dynamic Data Multi Request Center Stack : Functional Unit Class ID";
BA_ "VNSigAllNodes" SG_ 2158911488 ODDMC_FUCID 1;
BA_ "GenSigSendType" SG_ 2158919680 ODDMI_ReqType 10;
BA_ "VNSigInfotainment" SG_ 2158919680 ODDMI_ReqType 1;
BA_ "SignalType" SG_ 2158919680 ODDMI_ReqType "ENM";
BA_ "PacketOrder" SG_ 2158919680 ODDMI_ReqType 1;
BA_ "SignalLongName" SG_ 2158919680 ODDMI_ReqType "Open Display Interface Dynamic Data Multi Request IPC : Request Type";
BA_ "VNSigAllNodes" SG_ 2158919680 ODDMI_ReqType 1;
BA_ "GenSigDeltaValue" SG_ 2158919680 ODDMI_FUCID 1;
BA_ "GenSigSendType" SG_ 2158919680 ODDMI_FUCID 12;
BA_ "VNSigInfotainment" SG_ 2158919680 ODDMI_FUCID 1;
BA_ "SignalType" SG_ 2158919680 ODDMI_FUCID "UNM";
BA_ "PacketOrder" SG_ 2158919680 ODDMI_FUCID 6;
BA_ "SignalLongName" SG_ 2158919680 ODDMI_FUCID "Open Display Interface Dynamic Data Multi Request IPC : Functional Unit Class ID";
BA_ "VNSigAllNodes" SG_ 2158919680 ODDMI_FUCID 1;
BA_ "GenSigSendType" SG_ 2158919680 ODDMI_DispMID 10;
BA_ "VNSigInfotainment" SG_ 2158919680 ODDMI_DispMID 1;
BA_ "SignalType" SG_ 2158919680 ODDMI_DispMID "ENM";
BA_ "PacketOrder" SG_ 2158919680 ODDMI_DispMID 7;
BA_ "SignalLongName" SG_ 2158919680 ODDMI_DispMID "Open Display Interface Dynamic Data Multi Request IPC : Display Mask Id";
BA_ "VNSigAllNodes" SG_ 2158919680 ODDMI_DispMID 1;
BA_ "GenSigSendType" SG_ 2158919680 ODDMI_DataID2Vld 10;
BA_ "VNSigInfotainment" SG_ 2158919680 ODDMI_DataID2Vld 1;
BA_ "SignalType" SG_ 2158919680 ODDMI_DataID2Vld "BLN";
BA_ "PacketOrder" SG_ 2158919680 ODDMI_DataID2Vld 5;
BA_ "SignalLongName" SG_ 2158919680 ODDMI_DataID2Vld "Open Display Interface Dynamic Data Multi Request IPC : Data ID Two Valid";
BA_ "VNSigAllNodes" SG_ 2158919680 ODDMI_DataID2Vld 1;
BA_ "GenSigDeltaValue" SG_ 2158919680 ODDMI_DataID2 1;
BA_ "GenSigSendType" SG_ 2158919680 ODDMI_DataID2 12;
BA_ "VNSigInfotainment" SG_ 2158919680 ODDMI_DataID2 1;
BA_ "SignalType" SG_ 2158919680 ODDMI_DataID2 "UNM";
BA_ "PacketOrder" SG_ 2158919680 ODDMI_DataID2 9;
BA_ "SignalLongName" SG_ 2158919680 ODDMI_DataID2 "Open Display Interface Dynamic Data Multi Request IPC : Data ID Two";
BA_ "VNSigAllNodes" SG_ 2158919680 ODDMI_DataID2 1;
BA_ "GenSigSendType" SG_ 2158919680 ODDMI_DataID3Vld 10;
BA_ "VNSigInfotainment" SG_ 2158919680 ODDMI_DataID3Vld 1;
BA_ "SignalType" SG_ 2158919680 ODDMI_DataID3Vld "BLN";
BA_ "PacketOrder" SG_ 2158919680 ODDMI_DataID3Vld 4;
BA_ "SignalLongName" SG_ 2158919680 ODDMI_DataID3Vld "Open Display Interface Dynamic Data Multi Request IPC : Data ID Three Valid";
BA_ "VNSigAllNodes" SG_ 2158919680 ODDMI_DataID3Vld 1;
BA_ "GenSigSendType" SG_ 2158919680 ODDMI_DataID3 12;
BA_ "VNSigInfotainment" SG_ 2158919680 ODDMI_DataID3 1;
BA_ "SignalType" SG_ 2158919680 ODDMI_DataID3 "UNM";
BA_ "PacketOrder" SG_ 2158919680 ODDMI_DataID3 10;
BA_ "SignalLongName" SG_ 2158919680 ODDMI_DataID3 "Open Display Interface Dynamic Data Multi Request IPC : Data ID Three";
BA_ "VNSigAllNodes" SG_ 2158919680 ODDMI_DataID3 1;
BA_ "GenSigDeltaValue" SG_ 2158919680 ODDMI_DataID1 1;
BA_ "GenSigSendType" SG_ 2158919680 ODDMI_DataID1 12;
BA_ "VNSigInfotainment" SG_ 2158919680 ODDMI_DataID1 1;
BA_ "SignalType" SG_ 2158919680 ODDMI_DataID1 "UNM";
BA_ "PacketOrder" SG_ 2158919680 ODDMI_DataID1 8;
BA_ "SignalLongName" SG_ 2158919680 ODDMI_DataID1 "Open Display Interface Dynamic Data Multi Request IPC : Data ID One";
BA_ "VNSigAllNodes" SG_ 2158919680 ODDMI_DataID1 1;
BA_ "GenSigSendType" SG_ 2158919680 ODDMI_DataID4Vld 10;
BA_ "VNSigInfotainment" SG_ 2158919680 ODDMI_DataID4Vld 1;
BA_ "SignalType" SG_ 2158919680 ODDMI_DataID4Vld "BLN";
BA_ "PacketOrder" SG_ 2158919680 ODDMI_DataID4Vld 3;
BA_ "SignalLongName" SG_ 2158919680 ODDMI_DataID4Vld "Open Display Interface Dynamic Data Multi Request IPC : Data ID Four Valid";
BA_ "VNSigAllNodes" SG_ 2158919680 ODDMI_DataID4Vld 1;
BA_ "GenSigDeltaValue" SG_ 2158919680 ODDMI_DataID4 1;
BA_ "GenSigSendType" SG_ 2158919680 ODDMI_DataID4 12;
BA_ "VNSigInfotainment" SG_ 2158919680 ODDMI_DataID4 1;
BA_ "SignalType" SG_ 2158919680 ODDMI_DataID4 "UNM";
BA_ "PacketOrder" SG_ 2158919680 ODDMI_DataID4 11;
BA_ "SignalLongName" SG_ 2158919680 ODDMI_DataID4 "Open Display Interface Dynamic Data Multi Request IPC : Data ID Four";
BA_ "VNSigAllNodes" SG_ 2158919680 ODDMI_DataID4 1;
BA_ "GenSigSendType" SG_ 2158919680 ODDMI_DataID5Vld 10;
BA_ "VNSigInfotainment" SG_ 2158919680 ODDMI_DataID5Vld 1;
BA_ "SignalType" SG_ 2158919680 ODDMI_DataID5Vld "BLN";
BA_ "PacketOrder" SG_ 2158919680 ODDMI_DataID5Vld 2;
BA_ "SignalLongName" SG_ 2158919680 ODDMI_DataID5Vld "Open Display Interface Dynamic Data Multi Request IPC : Data ID Five Valid";
BA_ "VNSigAllNodes" SG_ 2158919680 ODDMI_DataID5Vld 1;
BA_ "GenSigDeltaValue" SG_ 2158919680 ODDMI_DataID5 1;
BA_ "GenSigSendType" SG_ 2158919680 ODDMI_DataID5 12;
BA_ "VNSigInfotainment" SG_ 2158919680 ODDMI_DataID5 1;
BA_ "SignalType" SG_ 2158919680 ODDMI_DataID5 "UNM";
BA_ "PacketOrder" SG_ 2158919680 ODDMI_DataID5 12;
BA_ "SignalLongName" SG_ 2158919680 ODDMI_DataID5 "Open Display Interface Dynamic Data Multi Request IPC : Data ID Five";
BA_ "VNSigAllNodes" SG_ 2158919680 ODDMI_DataID5 1;
BA_ "GenSigSendType" SG_ 2151825408 OtsAirTmpV 10;
BA_ "SignalType" SG_ 2151825408 OtsAirTmpV "ENM";
BA_ "SignalLongName" SG_ 2151825408 OtsAirTmpV "Outside Air Temperature Validity";
BA_ "VNSigAllNodes" SG_ 2151825408 OtsAirTmpV 1;
BA_ "GenSigDeltaValue" SG_ 2151825408 OtsAirTmp 1;
BA_ "GenSigSendType" SG_ 2151825408 OtsAirTmp 12;
BA_ "GenSigSendOnInit" SG_ 2151825408 OtsAirTmp 1;
BA_ "SignalType" SG_ 2151825408 OtsAirTmp "UNM";
BA_ "SignalLongName" SG_ 2151825408 OtsAirTmp "Outside Air Temperature";
BA_ "VNSigAllNodes" SG_ 2151825408 OtsAirTmp 1;
BA_ "GenSigSendType" SG_ 2151825408 OtsAirTmpCrValV 10;
BA_ "VNSigInfotainment" SG_ 2151825408 OtsAirTmpCrValV 1;
BA_ "SignalType" SG_ 2151825408 OtsAirTmpCrValV "ENM";
BA_ "SignalLongName" SG_ 2151825408 OtsAirTmpCrValV "Outside Air Temperature Corrected Value Validity";
BA_ "VNSigAllNodes" SG_ 2151825408 OtsAirTmpCrValV 1;
BA_ "GenSigDeltaValue" SG_ 2151825408 OtsAirTmpCrVal 1;
BA_ "GenSigSendType" SG_ 2151825408 OtsAirTmpCrVal 12;
BA_ "GenSigSendOnInit" SG_ 2151825408 OtsAirTmpCrVal 1;
BA_ "VNSigInfotainment" SG_ 2151825408 OtsAirTmpCrVal 1;
BA_ "SignalType" SG_ 2151825408 OtsAirTmpCrVal "UNM";
BA_ "SignalLongName" SG_ 2151825408 OtsAirTmpCrVal "Outside Air Temperature Corrected Value";
BA_ "VNSigAllNodes" SG_ 2151825408 OtsAirTmpCrVal 1;
BA_ "GenSigSendType" SG_ 2151825408 OtsAirTmpCrValMsk 10;
BA_ "SignalType" SG_ 2151825408 OtsAirTmpCrValMsk "ENM";
BA_ "SignalLongName" SG_ 2151825408 OtsAirTmpCrValMsk "Outside Air Temperature Corrected Value Mask";
BA_ "VNSigAllNodes" SG_ 2151825408 OtsAirTmpCrValMsk 1;
BA_ "GenSigSendType" SG_ 2151153664 RrWndDfgOn 10;
BA_ "GenSigSendOnInit" SG_ 2151153664 RrWndDfgOn 1;
BA_ "SignalType" SG_ 2151153664 RrWndDfgOn "BLN";
BA_ "SignalLongName" SG_ 2151153664 RrWndDfgOn "Rear Window Defog On";
BA_ "VNSigAllNodes" SG_ 2151153664 RrWndDfgOn 1;
BA_ "GenSigSendType" SG_ 2151170048 RrEndCrrStat 10;
BA_ "SignalType" SG_ 2151170048 RrEndCrrStat "ENM";
BA_ "SignalLongName" SG_ 2151170048 RrEndCrrStat "Rear End Carrier Status";
BA_ "VNSigAllNodes" SG_ 2151170048 RrEndCrrStat 1;
BA_ "GenSigSendType" SG_ 2151170048 RRPrkLmpFld 10;
BA_ "SignalType" SG_ 2151170048 RRPrkLmpFld "BLN";
BA_ "SignalLongName" SG_ 2151170048 RRPrkLmpFld "Rear Right Park Lamp Failed";
BA_ "VNSigAllNodes" SG_ 2151170048 RRPrkLmpFld 1;
BA_ "GenSigSendType" SG_ 2151170048 RLftPrkLmpFld 10;
BA_ "SignalType" SG_ 2151170048 RLftPrkLmpFld "BLN";
BA_ "SignalLongName" SG_ 2151170048 RLftPrkLmpFld "Rear Left Park Lamp Failed";
BA_ "VNSigAllNodes" SG_ 2151170048 RLftPrkLmpFld 1;
BA_ "GenSigSendType" SG_ 2151170048 DisRrPrmryLmps 10;
BA_ "SignalType" SG_ 2151170048 DisRrPrmryLmps "BLN";
BA_ "SignalLongName" SG_ 2151170048 DisRrPrmryLmps "Disable Rear Primary Lamps";
BA_ "VNSigAllNodes" SG_ 2151170048 DisRrPrmryLmps 1;
BA_ "GenSigSendType" SG_ 2151170048 TrlrTlLtFld 10;
BA_ "SignalType" SG_ 2151170048 TrlrTlLtFld "BLN";
BA_ "SignalLongName" SG_ 2151170048 TrlrTlLtFld "Trailer Tail Light Failed";
BA_ "VNSigAllNodes" SG_ 2151170048 TrlrTlLtFld 1;
BA_ "GenSigSendType" SG_ 2151170048 TrlrRvsLtFld 10;
BA_ "SignalType" SG_ 2151170048 TrlrRvsLtFld "BLN";
BA_ "SignalLongName" SG_ 2151170048 TrlrRvsLtFld "Trailer Reverse Light Failed";
BA_ "VNSigAllNodes" SG_ 2151170048 TrlrRvsLtFld 1;
BA_ "GenSigSendType" SG_ 2151170048 TrlrFgLtFld 10;
BA_ "SignalType" SG_ 2151170048 TrlrFgLtFld "BLN";
BA_ "SignalLongName" SG_ 2151170048 TrlrFgLtFld "Trailer Fog Light Failed";
BA_ "VNSigAllNodes" SG_ 2151170048 TrlrFgLtFld 1;
BA_ "GenSigSendType" SG_ 2151170048 TrlrBrkLtFld 10;
BA_ "SignalType" SG_ 2151170048 TrlrBrkLtFld "BLN";
BA_ "SignalLongName" SG_ 2151170048 TrlrBrkLtFld "Trailer Brake Light Failed";
BA_ "VNSigAllNodes" SG_ 2151170048 TrlrBrkLtFld 1;
BA_ "GenSigSendType" SG_ 2151170048 TrlrRtTrInLtFld 10;
BA_ "GenSigSendOnInit" SG_ 2151170048 TrlrRtTrInLtFld 1;
BA_ "SignalType" SG_ 2151170048 TrlrRtTrInLtFld "BLN";
BA_ "SignalLongName" SG_ 2151170048 TrlrRtTrInLtFld "Trailer Right Turn Indicator Light Failed";
BA_ "VNSigAllNodes" SG_ 2151170048 TrlrRtTrInLtFld 1;
BA_ "GenSigSendType" SG_ 2151170048 TrlLfTrInLtFld 10;
BA_ "GenSigSendOnInit" SG_ 2151170048 TrlLfTrInLtFld 1;
BA_ "SignalType" SG_ 2151170048 TrlLfTrInLtFld "BLN";
BA_ "SignalLongName" SG_ 2151170048 TrlLfTrInLtFld "Trailer Left Turn Indicator Light Failed";
BA_ "VNSigAllNodes" SG_ 2151170048 TrlLfTrInLtFld 1;
BA_ "GenSigSendType" SG_ 2151170048 TrlrHtchSwAtv 10;
BA_ "GenSigSendOnInit" SG_ 2151170048 TrlrHtchSwAtv 2;
BA_ "VNSigParkedVehicle" SG_ 2151170048 TrlrHtchSwAtv 1;
BA_ "SignalType" SG_ 2151170048 TrlrHtchSwAtv "BLN";
BA_ "SignalLongName" SG_ 2151170048 TrlrHtchSwAtv "Trailer Hitch Switch Active";
BA_ "VNSigAllNodes" SG_ 2151170048 TrlrHtchSwAtv 1;
BA_ "GenSigSendType" SG_ 2151170048 RtSecTrnIndFld 10;
BA_ "SignalType" SG_ 2151170048 RtSecTrnIndFld "BLN";
BA_ "SignalLongName" SG_ 2151170048 RtSecTrnIndFld "Right Secondary Turn Indicator Failed";
BA_ "VNSigAllNodes" SG_ 2151170048 RtSecTrnIndFld 1;
BA_ "GenSigSendType" SG_ 2151170048 TrlrFgLtPrs 10;
BA_ "SignalType" SG_ 2151170048 TrlrFgLtPrs "BLN";
BA_ "SignalLongName" SG_ 2151170048 TrlrFgLtPrs "Trailer Fog Light Present";
BA_ "VNSigAllNodes" SG_ 2151170048 TrlrFgLtPrs 1;
BA_ "GenSigSendType" SG_ 2151170048 LftSecTrnIndFld 10;
BA_ "SignalType" SG_ 2151170048 LftSecTrnIndFld "BLN";
BA_ "SignalLongName" SG_ 2151170048 LftSecTrnIndFld "Left Secondary Turn Indicator Failed";
BA_ "VNSigAllNodes" SG_ 2151170048 LftSecTrnIndFld 1;
BA_ "GenSigSendType" SG_ 2151841792 HtdFrntWSSt 10;
BA_ "GenSigSendOnInit" SG_ 2151841792 HtdFrntWSSt 2;
BA_ "SignalType" SG_ 2151841792 HtdFrntWSSt "ENM";
BA_ "SignalLongName" SG_ 2151841792 HtdFrntWSSt "Heated Front Windshield Status";
BA_ "VNSigAllNodes" SG_ 2151841792 HtdFrntWSSt 1;
BA_ "GenSigSendType" SG_ 2151841792 WSWprAct 10;
BA_ "SignalType" SG_ 2151841792 WSWprAct "BLN";
BA_ "SignalLongName" SG_ 2151841792 WSWprAct "Windshield Wiper Active";
BA_ "VNSigAllNodes" SG_ 2151841792 WSWprAct 1;
BA_ "GenSigSendType" SG_ 2151841792 RnSnsOffIO 10;
BA_ "GenSigSendOnInit" SG_ 2151841792 RnSnsOffIO 2;
BA_ "SignalType" SG_ 2151841792 RnSnsOffIO "BLN";
BA_ "SignalLongName" SG_ 2151841792 RnSnsOffIO "Rain Sensor Off Indication On";
BA_ "VNSigAllNodes" SG_ 2151841792 RnSnsOffIO 1;
BA_ "GenSigSendType" SG_ 2151841792 RnSnsActIO 10;
BA_ "SignalType" SG_ 2151841792 RnSnsActIO "BLN";
BA_ "SignalLongName" SG_ 2151841792 RnSnsActIO "Rain Sensor Active Indication On";
BA_ "VNSigAllNodes" SG_ 2151841792 RnSnsActIO 1;
BA_ "GenSigSendType" SG_ 2151841792 TurnWprIntIO 10;
BA_ "SignalType" SG_ 2151841792 TurnWprIntIO "BLN";
BA_ "SignalLongName" SG_ 2151841792 TurnWprIntIO "Turn Wiper Control To Intermittent First Indication On";
BA_ "VNSigAllNodes" SG_ 2151841792 TurnWprIntIO 1;
BA_ "GenSigSendType" SG_ 2154995712 HVHtrFldIO 10;
BA_ "SignalType" SG_ 2154995712 HVHtrFldIO "BLN";
BA_ "SignalLongName" SG_ 2154995712 HVHtrFldIO "High Voltage Heater Failed Indication On";
BA_ "VNSigAllNodes" SG_ 2154995712 HVHtrFldIO 1;
BA_ "GenSigSendType" SG_ 2154995712 HVHtrOvrTmpIndOn 10;
BA_ "SignalType" SG_ 2154995712 HVHtrOvrTmpIndOn "BLN";
BA_ "SignalLongName" SG_ 2154995712 HVHtrOvrTmpIndOn "High Voltage Heater Over Temperature Indication On";
BA_ "VNSigAllNodes" SG_ 2154995712 HVHtrOvrTmpIndOn 1;
BA_ "GenSigSendType" SG_ 2154094592 IntDimSeldClrTypStVal 10;
BA_ "GenSigSendOnInit" SG_ 2154094592 IntDimSeldClrTypStVal 1;
BA_ "SignalType" SG_ 2154094592 IntDimSeldClrTypStVal "ENM";
BA_ "SignalLongName" SG_ 2154094592 IntDimSeldClrTypStVal "Interior Dimming Selected Color Type Setting Value";
BA_ "VNSigAllNodes" SG_ 2154094592 IntDimSeldClrTypStVal 1;
BA_ "GenSigSendType" SG_ 2154094592 IntDimSeldAnmTypStVal 10;
BA_ "GenSigSendOnInit" SG_ 2154094592 IntDimSeldAnmTypStVal 1;
BA_ "SignalType" SG_ 2154094592 IntDimSeldAnmTypStVal "ENM";
BA_ "SignalLongName" SG_ 2154094592 IntDimSeldAnmTypStVal "Interior Dimming Selected Animation Type Setting Value";
BA_ "VNSigAllNodes" SG_ 2154094592 IntDimSeldAnmTypStVal 1;
BA_ "GenSigSendType" SG_ 2154094592 IDCTA_ClrTyp30Avl 10;
BA_ "GenSigSendOnInit" SG_ 2154094592 IDCTA_ClrTyp30Avl 1;
BA_ "PacketOrder" SG_ 2154094592 IDCTA_ClrTyp30Avl 31;
BA_ "SignalType" SG_ 2154094592 IDCTA_ClrTyp30Avl "BLN";
BA_ "SignalLongName" SG_ 2154094592 IDCTA_ClrTyp30Avl "Interior Dimming Color Type Available : Color Type 30 Available";
BA_ "VNSigAllNodes" SG_ 2154094592 IDCTA_ClrTyp30Avl 1;
BA_ "GenSigSendType" SG_ 2154094592 IDCTA_ClrTyp29Avl 10;
BA_ "GenSigSendOnInit" SG_ 2154094592 IDCTA_ClrTyp29Avl 1;
BA_ "PacketOrder" SG_ 2154094592 IDCTA_ClrTyp29Avl 30;
BA_ "SignalType" SG_ 2154094592 IDCTA_ClrTyp29Avl "BLN";
BA_ "SignalLongName" SG_ 2154094592 IDCTA_ClrTyp29Avl "Interior Dimming Color Type Available : Color Type 29 Available";
BA_ "VNSigAllNodes" SG_ 2154094592 IDCTA_ClrTyp29Avl 1;
BA_ "GenSigSendType" SG_ 2154094592 IDCTA_ClrTyp28Avl 10;
BA_ "GenSigSendOnInit" SG_ 2154094592 IDCTA_ClrTyp28Avl 1;
BA_ "PacketOrder" SG_ 2154094592 IDCTA_ClrTyp28Avl 29;
BA_ "SignalType" SG_ 2154094592 IDCTA_ClrTyp28Avl "BLN";
BA_ "SignalLongName" SG_ 2154094592 IDCTA_ClrTyp28Avl "Interior Dimming Color Type Available : Color Type 28 Available";
BA_ "VNSigAllNodes" SG_ 2154094592 IDCTA_ClrTyp28Avl 1;
BA_ "GenSigSendType" SG_ 2154094592 IDCTA_ClrTyp27Avl 10;
BA_ "GenSigSendOnInit" SG_ 2154094592 IDCTA_ClrTyp27Avl 1;
BA_ "PacketOrder" SG_ 2154094592 IDCTA_ClrTyp27Avl 28;
BA_ "SignalType" SG_ 2154094592 IDCTA_ClrTyp27Avl "BLN";
BA_ "SignalLongName" SG_ 2154094592 IDCTA_ClrTyp27Avl "Interior Dimming Color Type Available : Color Type 27 Available";
BA_ "VNSigAllNodes" SG_ 2154094592 IDCTA_ClrTyp27Avl 1;
BA_ "GenSigSendType" SG_ 2154094592 IDCTA_ClrTyp26Avl 10;
BA_ "GenSigSendOnInit" SG_ 2154094592 IDCTA_ClrTyp26Avl 1;
BA_ "PacketOrder" SG_ 2154094592 IDCTA_ClrTyp26Avl 27;
BA_ "SignalType" SG_ 2154094592 IDCTA_ClrTyp26Avl "BLN";
BA_ "SignalLongName" SG_ 2154094592 IDCTA_ClrTyp26Avl "Interior Dimming Color Type Available : Color Type 26 Available";
BA_ "VNSigAllNodes" SG_ 2154094592 IDCTA_ClrTyp26Avl 1;
BA_ "GenSigSendType" SG_ 2154094592 IDCTA_ClrTyp25Avl 10;
BA_ "GenSigSendOnInit" SG_ 2154094592 IDCTA_ClrTyp25Avl 1;
BA_ "PacketOrder" SG_ 2154094592 IDCTA_ClrTyp25Avl 26;
BA_ "SignalType" SG_ 2154094592 IDCTA_ClrTyp25Avl "BLN";
BA_ "SignalLongName" SG_ 2154094592 IDCTA_ClrTyp25Avl "Interior Dimming Color Type Available : Color Type 25 Available";
BA_ "VNSigAllNodes" SG_ 2154094592 IDCTA_ClrTyp25Avl 1;
BA_ "GenSigSendType" SG_ 2154094592 IDCTA_ClrTyp24Avl 10;
BA_ "GenSigSendOnInit" SG_ 2154094592 IDCTA_ClrTyp24Avl 1;
BA_ "PacketOrder" SG_ 2154094592 IDCTA_ClrTyp24Avl 25;
BA_ "SignalType" SG_ 2154094592 IDCTA_ClrTyp24Avl "BLN";
BA_ "SignalLongName" SG_ 2154094592 IDCTA_ClrTyp24Avl "Interior Dimming Color Type Available : Color Type 24 Available";
BA_ "VNSigAllNodes" SG_ 2154094592 IDCTA_ClrTyp24Avl 1;
BA_ "GenSigSendType" SG_ 2154094592 IDCTA_ClrTyp23Avl 10;
BA_ "GenSigSendOnInit" SG_ 2154094592 IDCTA_ClrTyp23Avl 1;
BA_ "PacketOrder" SG_ 2154094592 IDCTA_ClrTyp23Avl 24;
BA_ "SignalType" SG_ 2154094592 IDCTA_ClrTyp23Avl "BLN";
BA_ "SignalLongName" SG_ 2154094592 IDCTA_ClrTyp23Avl "Interior Dimming Color Type Available : Color Type 23 Available";
BA_ "VNSigAllNodes" SG_ 2154094592 IDCTA_ClrTyp23Avl 1;
BA_ "GenSigSendType" SG_ 2154094592 IDCTA_ClrTyp22Avl 10;
BA_ "GenSigSendOnInit" SG_ 2154094592 IDCTA_ClrTyp22Avl 1;
BA_ "PacketOrder" SG_ 2154094592 IDCTA_ClrTyp22Avl 23;
BA_ "SignalType" SG_ 2154094592 IDCTA_ClrTyp22Avl "BLN";
BA_ "SignalLongName" SG_ 2154094592 IDCTA_ClrTyp22Avl "Interior Dimming Color Type Available : Color Type 22 Available";
BA_ "VNSigAllNodes" SG_ 2154094592 IDCTA_ClrTyp22Avl 1;
BA_ "GenSigSendType" SG_ 2154094592 IDCTA_ClrTyp21Avl 10;
BA_ "GenSigSendOnInit" SG_ 2154094592 IDCTA_ClrTyp21Avl 1;
BA_ "PacketOrder" SG_ 2154094592 IDCTA_ClrTyp21Avl 22;
BA_ "SignalType" SG_ 2154094592 IDCTA_ClrTyp21Avl "BLN";
BA_ "SignalLongName" SG_ 2154094592 IDCTA_ClrTyp21Avl "Interior Dimming Color Type Available : Color Type 21 Available";
BA_ "VNSigAllNodes" SG_ 2154094592 IDCTA_ClrTyp21Avl 1;
BA_ "GenSigSendType" SG_ 2154094592 IDCTA_ClrTyp20Avl 10;
BA_ "GenSigSendOnInit" SG_ 2154094592 IDCTA_ClrTyp20Avl 1;
BA_ "PacketOrder" SG_ 2154094592 IDCTA_ClrTyp20Avl 21;
BA_ "SignalType" SG_ 2154094592 IDCTA_ClrTyp20Avl "BLN";
BA_ "SignalLongName" SG_ 2154094592 IDCTA_ClrTyp20Avl "Interior Dimming Color Type Available : Color Type 20 Available";
BA_ "VNSigAllNodes" SG_ 2154094592 IDCTA_ClrTyp20Avl 1;
BA_ "GenSigSendType" SG_ 2154094592 IDCTA_ClrTyp19Avl 10;
BA_ "GenSigSendOnInit" SG_ 2154094592 IDCTA_ClrTyp19Avl 1;
BA_ "PacketOrder" SG_ 2154094592 IDCTA_ClrTyp19Avl 20;
BA_ "SignalType" SG_ 2154094592 IDCTA_ClrTyp19Avl "BLN";
BA_ "SignalLongName" SG_ 2154094592 IDCTA_ClrTyp19Avl "Interior Dimming Color Type Available : Color Type 19 Available";
BA_ "VNSigAllNodes" SG_ 2154094592 IDCTA_ClrTyp19Avl 1;
BA_ "GenSigSendType" SG_ 2154094592 IDCTA_ClrTyp18Avl 10;
BA_ "GenSigSendOnInit" SG_ 2154094592 IDCTA_ClrTyp18Avl 1;
BA_ "PacketOrder" SG_ 2154094592 IDCTA_ClrTyp18Avl 19;
BA_ "SignalType" SG_ 2154094592 IDCTA_ClrTyp18Avl "BLN";
BA_ "SignalLongName" SG_ 2154094592 IDCTA_ClrTyp18Avl "Interior Dimming Color Type Available : Color Type 18 Available";
BA_ "VNSigAllNodes" SG_ 2154094592 IDCTA_ClrTyp18Avl 1;
BA_ "GenSigSendType" SG_ 2154094592 IDCTA_ClrTyp17Avl 10;
BA_ "GenSigSendOnInit" SG_ 2154094592 IDCTA_ClrTyp17Avl 1;
BA_ "PacketOrder" SG_ 2154094592 IDCTA_ClrTyp17Avl 18;
BA_ "SignalType" SG_ 2154094592 IDCTA_ClrTyp17Avl "BLN";
BA_ "SignalLongName" SG_ 2154094592 IDCTA_ClrTyp17Avl "Interior Dimming Color Type Available : Color Type 17 Available";
BA_ "VNSigAllNodes" SG_ 2154094592 IDCTA_ClrTyp17Avl 1;
BA_ "GenSigSendType" SG_ 2154094592 IDCTA_ClrTyp16Avl 10;
BA_ "GenSigSendOnInit" SG_ 2154094592 IDCTA_ClrTyp16Avl 1;
BA_ "PacketOrder" SG_ 2154094592 IDCTA_ClrTyp16Avl 17;
BA_ "SignalType" SG_ 2154094592 IDCTA_ClrTyp16Avl "BLN";
BA_ "SignalLongName" SG_ 2154094592 IDCTA_ClrTyp16Avl "Interior Dimming Color Type Available : Color Type 16 Available";
BA_ "VNSigAllNodes" SG_ 2154094592 IDCTA_ClrTyp16Avl 1;
BA_ "GenSigSendType" SG_ 2154094592 IDCTA_ClrTyp15Avl 10;
BA_ "GenSigSendOnInit" SG_ 2154094592 IDCTA_ClrTyp15Avl 1;
BA_ "PacketOrder" SG_ 2154094592 IDCTA_ClrTyp15Avl 16;
BA_ "SignalType" SG_ 2154094592 IDCTA_ClrTyp15Avl "BLN";
BA_ "SignalLongName" SG_ 2154094592 IDCTA_ClrTyp15Avl "Interior Dimming Color Type Available : Color Type 15 Available";
BA_ "VNSigAllNodes" SG_ 2154094592 IDCTA_ClrTyp15Avl 1;
BA_ "GenSigSendType" SG_ 2154094592 IDCTA_ClrTyp14Avl 10;
BA_ "GenSigSendOnInit" SG_ 2154094592 IDCTA_ClrTyp14Avl 1;
BA_ "PacketOrder" SG_ 2154094592 IDCTA_ClrTyp14Avl 15;
BA_ "SignalType" SG_ 2154094592 IDCTA_ClrTyp14Avl "BLN";
BA_ "SignalLongName" SG_ 2154094592 IDCTA_ClrTyp14Avl "Interior Dimming Color Type Available : Color Type 14 Available";
BA_ "VNSigAllNodes" SG_ 2154094592 IDCTA_ClrTyp14Avl 1;
BA_ "GenSigSendType" SG_ 2154094592 IDCTA_ClrTyp13Avl 10;
BA_ "GenSigSendOnInit" SG_ 2154094592 IDCTA_ClrTyp13Avl 1;
BA_ "PacketOrder" SG_ 2154094592 IDCTA_ClrTyp13Avl 14;
BA_ "SignalType" SG_ 2154094592 IDCTA_ClrTyp13Avl "BLN";
BA_ "SignalLongName" SG_ 2154094592 IDCTA_ClrTyp13Avl "Interior Dimming Color Type Available : Color Type 13 Available";
BA_ "VNSigAllNodes" SG_ 2154094592 IDCTA_ClrTyp13Avl 1;
BA_ "GenSigSendType" SG_ 2154094592 IDCTA_ClrTyp12Avl 10;
BA_ "GenSigSendOnInit" SG_ 2154094592 IDCTA_ClrTyp12Avl 1;
BA_ "PacketOrder" SG_ 2154094592 IDCTA_ClrTyp12Avl 13;
BA_ "SignalType" SG_ 2154094592 IDCTA_ClrTyp12Avl "BLN";
BA_ "SignalLongName" SG_ 2154094592 IDCTA_ClrTyp12Avl "Interior Dimming Color Type Available : Color Type 12 Available";
BA_ "VNSigAllNodes" SG_ 2154094592 IDCTA_ClrTyp12Avl 1;
BA_ "GenSigSendType" SG_ 2154094592 IDCTA_ClrTyp11Avl 10;
BA_ "GenSigSendOnInit" SG_ 2154094592 IDCTA_ClrTyp11Avl 1;
BA_ "PacketOrder" SG_ 2154094592 IDCTA_ClrTyp11Avl 12;
BA_ "SignalType" SG_ 2154094592 IDCTA_ClrTyp11Avl "BLN";
BA_ "SignalLongName" SG_ 2154094592 IDCTA_ClrTyp11Avl "Interior Dimming Color Type Available : Color Type 11 Available";
BA_ "VNSigAllNodes" SG_ 2154094592 IDCTA_ClrTyp11Avl 1;
BA_ "GenSigSendType" SG_ 2154094592 IDCTA_ClrTyp10Avl 10;
BA_ "GenSigSendOnInit" SG_ 2154094592 IDCTA_ClrTyp10Avl 1;
BA_ "PacketOrder" SG_ 2154094592 IDCTA_ClrTyp10Avl 11;
BA_ "SignalType" SG_ 2154094592 IDCTA_ClrTyp10Avl "BLN";
BA_ "SignalLongName" SG_ 2154094592 IDCTA_ClrTyp10Avl "Interior Dimming Color Type Available : Color Type 10 Available";
BA_ "VNSigAllNodes" SG_ 2154094592 IDCTA_ClrTyp10Avl 1;
BA_ "GenSigSendType" SG_ 2154094592 IDCTA_ClrTyp9Avl 10;
BA_ "GenSigSendOnInit" SG_ 2154094592 IDCTA_ClrTyp9Avl 1;
BA_ "PacketOrder" SG_ 2154094592 IDCTA_ClrTyp9Avl 10;
BA_ "SignalType" SG_ 2154094592 IDCTA_ClrTyp9Avl "BLN";
BA_ "SignalLongName" SG_ 2154094592 IDCTA_ClrTyp9Avl "Interior Dimming Color Type Available : Color Type 9 Available";
BA_ "VNSigAllNodes" SG_ 2154094592 IDCTA_ClrTyp9Avl 1;
BA_ "GenSigSendType" SG_ 2154094592 IDCTA_ClrTyp8Avl 10;
BA_ "GenSigSendOnInit" SG_ 2154094592 IDCTA_ClrTyp8Avl 1;
BA_ "PacketOrder" SG_ 2154094592 IDCTA_ClrTyp8Avl 9;
BA_ "SignalType" SG_ 2154094592 IDCTA_ClrTyp8Avl "BLN";
BA_ "SignalLongName" SG_ 2154094592 IDCTA_ClrTyp8Avl "Interior Dimming Color Type Available : Color Type 8 Available";
BA_ "VNSigAllNodes" SG_ 2154094592 IDCTA_ClrTyp8Avl 1;
BA_ "GenSigSendType" SG_ 2154094592 IDCTA_ClrTyp7Avl 10;
BA_ "GenSigSendOnInit" SG_ 2154094592 IDCTA_ClrTyp7Avl 1;
BA_ "PacketOrder" SG_ 2154094592 IDCTA_ClrTyp7Avl 8;
BA_ "SignalType" SG_ 2154094592 IDCTA_ClrTyp7Avl "BLN";
BA_ "SignalLongName" SG_ 2154094592 IDCTA_ClrTyp7Avl "Interior Dimming Color Type Available : Color Type 7 Available";
BA_ "VNSigAllNodes" SG_ 2154094592 IDCTA_ClrTyp7Avl 1;
BA_ "GenSigSendType" SG_ 2154094592 IDCTA_ClrTyp6Avl 10;
BA_ "GenSigSendOnInit" SG_ 2154094592 IDCTA_ClrTyp6Avl 1;
BA_ "PacketOrder" SG_ 2154094592 IDCTA_ClrTyp6Avl 7;
BA_ "SignalType" SG_ 2154094592 IDCTA_ClrTyp6Avl "BLN";
BA_ "SignalLongName" SG_ 2154094592 IDCTA_ClrTyp6Avl "Interior Dimming Color Type Available : Color Type 6 Available";
BA_ "VNSigAllNodes" SG_ 2154094592 IDCTA_ClrTyp6Avl 1;
BA_ "GenSigSendType" SG_ 2154094592 IDCTA_ClrTyp5Avl 10;
BA_ "GenSigSendOnInit" SG_ 2154094592 IDCTA_ClrTyp5Avl 1;
BA_ "PacketOrder" SG_ 2154094592 IDCTA_ClrTyp5Avl 6;
BA_ "SignalType" SG_ 2154094592 IDCTA_ClrTyp5Avl "BLN";
BA_ "SignalLongName" SG_ 2154094592 IDCTA_ClrTyp5Avl "Interior Dimming Color Type Available : Color Type 5 Available";
BA_ "VNSigAllNodes" SG_ 2154094592 IDCTA_ClrTyp5Avl 1;
BA_ "GenSigSendType" SG_ 2154094592 IDCTA_ClrTyp4Avl 10;
BA_ "GenSigSendOnInit" SG_ 2154094592 IDCTA_ClrTyp4Avl 1;
BA_ "PacketOrder" SG_ 2154094592 IDCTA_ClrTyp4Avl 5;
BA_ "SignalType" SG_ 2154094592 IDCTA_ClrTyp4Avl "BLN";
BA_ "SignalLongName" SG_ 2154094592 IDCTA_ClrTyp4Avl "Interior Dimming Color Type Available : Color Type 4 Available";
BA_ "VNSigAllNodes" SG_ 2154094592 IDCTA_ClrTyp4Avl 1;
BA_ "GenSigSendType" SG_ 2154094592 IDCTA_ClrTyp3Avl 10;
BA_ "GenSigSendOnInit" SG_ 2154094592 IDCTA_ClrTyp3Avl 1;
BA_ "PacketOrder" SG_ 2154094592 IDCTA_ClrTyp3Avl 4;
BA_ "SignalType" SG_ 2154094592 IDCTA_ClrTyp3Avl "BLN";
BA_ "SignalLongName" SG_ 2154094592 IDCTA_ClrTyp3Avl "Interior Dimming Color Type Available : Color Type 3 Available";
BA_ "VNSigAllNodes" SG_ 2154094592 IDCTA_ClrTyp3Avl 1;
BA_ "GenSigSendType" SG_ 2154094592 IDCTA_ClrTyp2Avl 10;
BA_ "GenSigSendOnInit" SG_ 2154094592 IDCTA_ClrTyp2Avl 1;
BA_ "PacketOrder" SG_ 2154094592 IDCTA_ClrTyp2Avl 3;
BA_ "SignalType" SG_ 2154094592 IDCTA_ClrTyp2Avl "BLN";
BA_ "SignalLongName" SG_ 2154094592 IDCTA_ClrTyp2Avl "Interior Dimming Color Type Available : Color Type 2 Available";
BA_ "VNSigAllNodes" SG_ 2154094592 IDCTA_ClrTyp2Avl 1;
BA_ "GenSigSendType" SG_ 2154094592 IDCTA_ClrTyp1Avl 10;
BA_ "GenSigSendOnInit" SG_ 2154094592 IDCTA_ClrTyp1Avl 1;
BA_ "PacketOrder" SG_ 2154094592 IDCTA_ClrTyp1Avl 2;
BA_ "SignalType" SG_ 2154094592 IDCTA_ClrTyp1Avl "BLN";
BA_ "SignalLongName" SG_ 2154094592 IDCTA_ClrTyp1Avl "Interior Dimming Color Type Available : Color Type 1 Available";
BA_ "VNSigAllNodes" SG_ 2154094592 IDCTA_ClrTyp1Avl 1;
BA_ "GenSigSendType" SG_ 2154094592 IDCTA_OffAvl 10;
BA_ "GenSigSendOnInit" SG_ 2154094592 IDCTA_OffAvl 1;
BA_ "PacketOrder" SG_ 2154094592 IDCTA_OffAvl 1;
BA_ "SignalType" SG_ 2154094592 IDCTA_OffAvl "BLN";
BA_ "SignalLongName" SG_ 2154094592 IDCTA_OffAvl "Interior Dimming Color Type Available : Off Available";
BA_ "VNSigAllNodes" SG_ 2154094592 IDCTA_OffAvl 1;
BA_ "GenSigSendType" SG_ 2154094592 IDATA_AnmTyp14Avl 10;
BA_ "GenSigSendOnInit" SG_ 2154094592 IDATA_AnmTyp14Avl 1;
BA_ "SignalType" SG_ 2154094592 IDATA_AnmTyp14Avl "BLN";
BA_ "PacketOrder" SG_ 2154094592 IDATA_AnmTyp14Avl 15;
BA_ "SignalLongName" SG_ 2154094592 IDATA_AnmTyp14Avl "Interior Dimming Animation Type Available : Animation Type 14 Available";
BA_ "VNSigAllNodes" SG_ 2154094592 IDATA_AnmTyp14Avl 1;
BA_ "GenSigSendType" SG_ 2154094592 IDATA_AnmTyp13Avl 10;
BA_ "GenSigSendOnInit" SG_ 2154094592 IDATA_AnmTyp13Avl 1;
BA_ "SignalType" SG_ 2154094592 IDATA_AnmTyp13Avl "BLN";
BA_ "PacketOrder" SG_ 2154094592 IDATA_AnmTyp13Avl 14;
BA_ "SignalLongName" SG_ 2154094592 IDATA_AnmTyp13Avl "Interior Dimming Animation Type Available : Animation Type 13 Available";
BA_ "VNSigAllNodes" SG_ 2154094592 IDATA_AnmTyp13Avl 1;
BA_ "GenSigSendType" SG_ 2154094592 IDATA_AnmTyp12Avl 10;
BA_ "GenSigSendOnInit" SG_ 2154094592 IDATA_AnmTyp12Avl 1;
BA_ "SignalType" SG_ 2154094592 IDATA_AnmTyp12Avl "BLN";
BA_ "PacketOrder" SG_ 2154094592 IDATA_AnmTyp12Avl 13;
BA_ "SignalLongName" SG_ 2154094592 IDATA_AnmTyp12Avl "Interior Dimming Animation Type Available : Animation Type 12 Available";
BA_ "VNSigAllNodes" SG_ 2154094592 IDATA_AnmTyp12Avl 1;
BA_ "GenSigSendType" SG_ 2154094592 IDATA_AnmTyp11Avl 10;
BA_ "GenSigSendOnInit" SG_ 2154094592 IDATA_AnmTyp11Avl 1;
BA_ "SignalType" SG_ 2154094592 IDATA_AnmTyp11Avl "BLN";
BA_ "PacketOrder" SG_ 2154094592 IDATA_AnmTyp11Avl 12;
BA_ "SignalLongName" SG_ 2154094592 IDATA_AnmTyp11Avl "Interior Dimming Animation Type Available : Animation Type 11 Available";
BA_ "VNSigAllNodes" SG_ 2154094592 IDATA_AnmTyp11Avl 1;
BA_ "GenSigSendType" SG_ 2154094592 IDATA_AnmTyp10Avl 10;
BA_ "GenSigSendOnInit" SG_ 2154094592 IDATA_AnmTyp10Avl 1;
BA_ "SignalType" SG_ 2154094592 IDATA_AnmTyp10Avl "BLN";
BA_ "PacketOrder" SG_ 2154094592 IDATA_AnmTyp10Avl 11;
BA_ "SignalLongName" SG_ 2154094592 IDATA_AnmTyp10Avl "Interior Dimming Animation Type Available : Animation Type 10 Available";
BA_ "VNSigAllNodes" SG_ 2154094592 IDATA_AnmTyp10Avl 1;
BA_ "GenSigSendType" SG_ 2154094592 IDATA_AnmTyp9Avl 10;
BA_ "GenSigSendOnInit" SG_ 2154094592 IDATA_AnmTyp9Avl 1;
BA_ "SignalType" SG_ 2154094592 IDATA_AnmTyp9Avl "BLN";
BA_ "PacketOrder" SG_ 2154094592 IDATA_AnmTyp9Avl 10;
BA_ "SignalLongName" SG_ 2154094592 IDATA_AnmTyp9Avl "Interior Dimming Animation Type Available : Animation Type 9 Available";
BA_ "VNSigAllNodes" SG_ 2154094592 IDATA_AnmTyp9Avl 1;
BA_ "GenSigSendType" SG_ 2154094592 IDATA_AnmTyp8Avl 10;
BA_ "GenSigSendOnInit" SG_ 2154094592 IDATA_AnmTyp8Avl 1;
BA_ "SignalType" SG_ 2154094592 IDATA_AnmTyp8Avl "BLN";
BA_ "PacketOrder" SG_ 2154094592 IDATA_AnmTyp8Avl 9;
BA_ "SignalLongName" SG_ 2154094592 IDATA_AnmTyp8Avl "Interior Dimming Animation Type Available : Animation Type 8 Available";
BA_ "VNSigAllNodes" SG_ 2154094592 IDATA_AnmTyp8Avl 1;
BA_ "GenSigSendType" SG_ 2154094592 IDATA_AnmTyp7Avl 10;
BA_ "GenSigSendOnInit" SG_ 2154094592 IDATA_AnmTyp7Avl 1;
BA_ "SignalType" SG_ 2154094592 IDATA_AnmTyp7Avl "BLN";
BA_ "PacketOrder" SG_ 2154094592 IDATA_AnmTyp7Avl 8;
BA_ "SignalLongName" SG_ 2154094592 IDATA_AnmTyp7Avl "Interior Dimming Animation Type Available : Animation Type 7 Available";
BA_ "VNSigAllNodes" SG_ 2154094592 IDATA_AnmTyp7Avl 1;
BA_ "GenSigSendType" SG_ 2154094592 IDATA_AnmTyp6Avl 10;
BA_ "GenSigSendOnInit" SG_ 2154094592 IDATA_AnmTyp6Avl 1;
BA_ "SignalType" SG_ 2154094592 IDATA_AnmTyp6Avl "BLN";
BA_ "PacketOrder" SG_ 2154094592 IDATA_AnmTyp6Avl 7;
BA_ "SignalLongName" SG_ 2154094592 IDATA_AnmTyp6Avl "Interior Dimming Animation Type Available : Animation Type 6 Available";
BA_ "VNSigAllNodes" SG_ 2154094592 IDATA_AnmTyp6Avl 1;
BA_ "GenSigSendType" SG_ 2154094592 IDATA_AnmTyp5Avl 10;
BA_ "GenSigSendOnInit" SG_ 2154094592 IDATA_AnmTyp5Avl 1;
BA_ "SignalType" SG_ 2154094592 IDATA_AnmTyp5Avl "BLN";
BA_ "PacketOrder" SG_ 2154094592 IDATA_AnmTyp5Avl 6;
BA_ "SignalLongName" SG_ 2154094592 IDATA_AnmTyp5Avl "Interior Dimming Animation Type Available : Animation Type 5 Available";
BA_ "VNSigAllNodes" SG_ 2154094592 IDATA_AnmTyp5Avl 1;
BA_ "GenSigSendType" SG_ 2154094592 IDATA_AnmTyp4Avl 10;
BA_ "GenSigSendOnInit" SG_ 2154094592 IDATA_AnmTyp4Avl 1;
BA_ "SignalType" SG_ 2154094592 IDATA_AnmTyp4Avl "BLN";
BA_ "PacketOrder" SG_ 2154094592 IDATA_AnmTyp4Avl 5;
BA_ "SignalLongName" SG_ 2154094592 IDATA_AnmTyp4Avl "Interior Dimming Animation Type Available : Animation Type 4 Available";
BA_ "VNSigAllNodes" SG_ 2154094592 IDATA_AnmTyp4Avl 1;
BA_ "GenSigSendType" SG_ 2154094592 IDATA_AnmTyp3Avl 10;
BA_ "GenSigSendOnInit" SG_ 2154094592 IDATA_AnmTyp3Avl 1;
BA_ "SignalType" SG_ 2154094592 IDATA_AnmTyp3Avl "BLN";
BA_ "PacketOrder" SG_ 2154094592 IDATA_AnmTyp3Avl 4;
BA_ "SignalLongName" SG_ 2154094592 IDATA_AnmTyp3Avl "Interior Dimming Animation Type Available : Animation Type 3 Available";
BA_ "VNSigAllNodes" SG_ 2154094592 IDATA_AnmTyp3Avl 1;
BA_ "GenSigSendType" SG_ 2154094592 IDATA_AnmTyp2Avl 10;
BA_ "GenSigSendOnInit" SG_ 2154094592 IDATA_AnmTyp2Avl 1;
BA_ "SignalType" SG_ 2154094592 IDATA_AnmTyp2Avl "BLN";
BA_ "PacketOrder" SG_ 2154094592 IDATA_AnmTyp2Avl 3;
BA_ "SignalLongName" SG_ 2154094592 IDATA_AnmTyp2Avl "Interior Dimming Animation Type Available : Animation Type 2 Available";
BA_ "VNSigAllNodes" SG_ 2154094592 IDATA_AnmTyp2Avl 1;
BA_ "GenSigSendType" SG_ 2154094592 IDATA_AnmTyp1Avl 10;
BA_ "GenSigSendOnInit" SG_ 2154094592 IDATA_AnmTyp1Avl 1;
BA_ "SignalType" SG_ 2154094592 IDATA_AnmTyp1Avl "BLN";
BA_ "PacketOrder" SG_ 2154094592 IDATA_AnmTyp1Avl 2;
BA_ "SignalLongName" SG_ 2154094592 IDATA_AnmTyp1Avl "Interior Dimming Animation Type Available : Animation Type 1 Available";
BA_ "VNSigAllNodes" SG_ 2154094592 IDATA_AnmTyp1Avl 1;
BA_ "GenSigSendType" SG_ 2154094592 IDATA_OffAvl 10;
BA_ "GenSigSendOnInit" SG_ 2154094592 IDATA_OffAvl 1;
BA_ "SignalType" SG_ 2154094592 IDATA_OffAvl "BLN";
BA_ "PacketOrder" SG_ 2154094592 IDATA_OffAvl 1;
BA_ "SignalLongName" SG_ 2154094592 IDATA_OffAvl "Interior Dimming Animation Type Available : Off Available";
BA_ "VNSigAllNodes" SG_ 2154094592 IDATA_OffAvl 1;
BA_ "GenSigSendType" SG_ 2154094592 AdjPdlMotInhbtd 10;
BA_ "SignalType" SG_ 2154094592 AdjPdlMotInhbtd "BLN";
BA_ "SignalLongName" SG_ 2154094592 AdjPdlMotInhbtd "Adjustable Pedal Motion Inhibited";
BA_ "VNSigAllNodes" SG_ 2154094592 AdjPdlMotInhbtd 1;
BA_ "SignalType" SG_ 2149711872 SetSpdLmtRchd "ENM";
BA_ "SignalLongName" SG_ 2149711872 SetSpdLmtRchd "Set Speed Limit Reached";
BA_ "VNSigAllNodes" SG_ 2149711872 SetSpdLmtRchd 1;
BA_ "SignalType" SG_ 2149711872 FOAI_VehAhdIndRq "ENM";
BA_ "PacketOrder" SG_ 2149711872 FOAI_VehAhdIndRq 2;
BA_ "SignalLongName" SG_ 2149711872 FOAI_VehAhdIndRq "Forward Object Alert Indications : Vehicle Ahead Indication Request";
BA_ "VNSigAllNodes" SG_ 2149711872 FOAI_VehAhdIndRq 1;
BA_ "SignalType" SG_ 2149711872 FOAI_AlrtWrnIndRq "ENM";
BA_ "PacketOrder" SG_ 2149711872 FOAI_AlrtWrnIndRq 3;
BA_ "SignalLongName" SG_ 2149711872 FOAI_AlrtWrnIndRq "Forward Object Alert Indications : Alert Warning Indication Request";
BA_ "VNSigAllNodes" SG_ 2149711872 FOAI_AlrtWrnIndRq 1;
BA_ "SignalType" SG_ 2149711872 FOAI_AlrtChmIhbRq "ENM";
BA_ "PacketOrder" SG_ 2149711872 FOAI_AlrtChmIhbRq 1;
BA_ "SignalLongName" SG_ 2149711872 FOAI_AlrtChmIhbRq "Forward Object Alert Indications : Alert Warning Chime Inhibit Request";
BA_ "VNSigAllNodes" SG_ 2149711872 FOAI_AlrtChmIhbRq 1;
BA_ "SignalType" SG_ 2149711872 FwdClnAlrtOffIO "BLN";
BA_ "SignalLongName" SG_ 2149711872 FwdClnAlrtOffIO "Forward Collision Alert Off Indication On";
BA_ "VNSigAllNodes" SG_ 2149711872 FwdClnAlrtOffIO 1;
BA_ "SignalType" SG_ 2149711872 FwdClnAlrtPr "BLN";
BA_ "SignalLongName" SG_ 2149711872 FwdClnAlrtPr "Forward Collision Alert Present";
BA_ "VNSigAllNodes" SG_ 2149711872 FwdClnAlrtPr 1;
BA_ "SignalType" SG_ 2149711872 VehDynYawRateV "ENM";
BA_ "SignalLongName" SG_ 2149711872 VehDynYawRateV "Vehicle Dynamics Yaw Rate Validity";
BA_ "VNSigAllNodes" SG_ 2149711872 VehDynYawRateV 1;
BA_ "SignalType" SG_ 2149711872 ACCHdwyStg "ENM";
BA_ "SignalLongName" SG_ 2149711872 ACCHdwyStg "Adaptive Cruise Control Headway Setting";
BA_ "VNSigAllNodes" SG_ 2149711872 ACCHdwyStg 1;
BA_ "SignalType" SG_ 2149711872 ACCDrvrSeltdSpd "UNM";
BA_ "SignalLongName" SG_ 2149711872 ACCDrvrSeltdSpd "Adaptive Cruise Control Driver Selected Speed";
BA_ "VNSigAllNodes" SG_ 2149711872 ACCDrvrSeltdSpd 1;
BA_ "SignalType" SG_ 2149711872 AdapCrsCntVDA "ENM";
BA_ "SignalLongName" SG_ 2149711872 AdapCrsCntVDA "Adaptive Cruise Control Virtual Device Availability";
BA_ "GenSigStartValue" SG_ 2149711872 AdapCrsCntVDA 1;
BA_ "VNSigAllNodes" SG_ 2149711872 AdapCrsCntVDA 1;
BA_ "SignalType" SG_ 2149711872 SpdLmtrSpdWrngEnbld "BLN";
BA_ "SignalLongName" SG_ 2149711872 SpdLmtrSpdWrngEnbld "Speed Limiter/Speed Warning Enabled";
BA_ "VNSigAllNodes" SG_ 2149711872 SpdLmtrSpdWrngEnbld 1;
BA_ "SignalType" SG_ 2149711872 VehDynYawRate "SNM";
BA_ "SignalLongName" SG_ 2149711872 VehDynYawRate "Vehicle Dynamics Yaw Rate";
BA_ "VNSigAllNodes" SG_ 2149711872 VehDynYawRate 1;
BA_ "SignalType" SG_ 2149711872 CrsCntlDrSelSpdAct "BLN";
BA_ "SignalLongName" SG_ 2149711872 CrsCntlDrSelSpdAct "Cruise Control Driver Selected Speed Active";
BA_ "VNSigAllNodes" SG_ 2149711872 CrsCntlDrSelSpdAct 1;
BA_ "SignalType" SG_ 2149711872 ACCAct370 "BLN";
BA_ "SignalLongName" SG_ 2149711872 ACCAct370 "Adaptive Cruise Control Active";
BA_ "VNSigAllNodes" SG_ 2149711872 ACCAct370 1;
BA_ "SignalType" SG_ 2149711872 SpdLmtrSpdWrngAct "BLN";
BA_ "SignalLongName" SG_ 2149711872 SpdLmtrSpdWrngAct "Speed Limiter/Speed Warning Active";
BA_ "VNSigAllNodes" SG_ 2149711872 SpdLmtrSpdWrngAct 1;
BA_ "SignalType" SG_ 2149711872 CrsSpdLmtrDrvSelSpd "UNM";
BA_ "SignalLongName" SG_ 2149711872 CrsSpdLmtrDrvSelSpd "Cruise and Speed Limiter Driver Selected Speed";
BA_ "VNSigAllNodes" SG_ 2149711872 CrsSpdLmtrDrvSelSpd 1;
BA_ "SignalType" SG_ 2149711872 AutoMdSpdLmtStat "ENM";
BA_ "SignalLongName" SG_ 2149711872 AutoMdSpdLmtStat "Auto Mode Speed Limit Status";
BA_ "VNSigAllNodes" SG_ 2149711872 AutoMdSpdLmtStat 1;
BA_ "SignalType" SG_ 2149711872 ACCAutoSetSpdStat "ENM";
BA_ "SignalLongName" SG_ 2149711872 ACCAutoSetSpdStat "Adaptive Cruise Control Auto Set Speed Status";
BA_ "VNSigAllNodes" SG_ 2149711872 ACCAutoSetSpdStat 1;
BA_ "GenSigSendType" SG_ 2153979904 RtPrkLtFld 10;
BA_ "GenSigSendOnInit" SG_ 2153979904 RtPrkLtFld 1;
BA_ "SignalType" SG_ 2153979904 RtPrkLtFld "BLN";
BA_ "SignalLongName" SG_ 2153979904 RtPrkLtFld "Right Park Light Failed";
BA_ "VNSigAllNodes" SG_ 2153979904 RtPrkLtFld 1;
BA_ "GenSigSendType" SG_ 2153979904 RtLwBmFld 10;
BA_ "GenSigSendOnInit" SG_ 2153979904 RtLwBmFld 1;
BA_ "SignalType" SG_ 2153979904 RtLwBmFld "BLN";
BA_ "SignalLongName" SG_ 2153979904 RtLwBmFld "Right Low Beam Failed";
BA_ "VNSigAllNodes" SG_ 2153979904 RtLwBmFld 1;
BA_ "GenSigSendType" SG_ 2153979904 RtDytmRunLmpFld 10;
BA_ "GenSigSendOnInit" SG_ 2153979904 RtDytmRunLmpFld 1;
BA_ "SignalType" SG_ 2153979904 RtDytmRunLmpFld "BLN";
BA_ "SignalLongName" SG_ 2153979904 RtDytmRunLmpFld "Right Daytime Running Lamp Failed";
BA_ "VNSigAllNodes" SG_ 2153979904 RtDytmRunLmpFld 1;
BA_ "GenSigSendType" SG_ 2153979904 RtBrkLtFld 10;
BA_ "GenSigSendOnInit" SG_ 2153979904 RtBrkLtFld 1;
BA_ "SignalType" SG_ 2153979904 RtBrkLtFld "BLN";
BA_ "SignalLongName" SG_ 2153979904 RtBrkLtFld "Right Brake Light Failed";
BA_ "VNSigAllNodes" SG_ 2153979904 RtBrkLtFld 1;
BA_ "GenSigSendType" SG_ 2153979904 RRTrnIndLtFld 10;
BA_ "GenSigSendOnInit" SG_ 2153979904 RRTrnIndLtFld 1;
BA_ "SignalType" SG_ 2153979904 RRTrnIndLtFld "BLN";
BA_ "SignalLongName" SG_ 2153979904 RRTrnIndLtFld "Rear Right Turn Indicator Light Failed";
BA_ "VNSigAllNodes" SG_ 2153979904 RRTrnIndLtFld 1;
BA_ "GenSigSendType" SG_ 2153979904 RLTrnIndLtFld 10;
BA_ "GenSigSendOnInit" SG_ 2153979904 RLTrnIndLtFld 1;
BA_ "SignalType" SG_ 2153979904 RLTrnIndLtFld "BLN";
BA_ "SignalLongName" SG_ 2153979904 RLTrnIndLtFld "Rear Left Turn Indicator Light Failed";
BA_ "VNSigAllNodes" SG_ 2153979904 RLTrnIndLtFld 1;
BA_ "GenSigSendType" SG_ 2153979904 LicPltLtFld 10;
BA_ "GenSigSendOnInit" SG_ 2153979904 LicPltLtFld 1;
BA_ "SignalType" SG_ 2153979904 LicPltLtFld "BLN";
BA_ "SignalLongName" SG_ 2153979904 LicPltLtFld "License Plate Light Failed";
BA_ "VNSigAllNodes" SG_ 2153979904 LicPltLtFld 1;
BA_ "GenSigSendType" SG_ 2153979904 LftPrkLtFld 10;
BA_ "GenSigSendOnInit" SG_ 2153979904 LftPrkLtFld 1;
BA_ "SignalType" SG_ 2153979904 LftPrkLtFld "BLN";
BA_ "SignalLongName" SG_ 2153979904 LftPrkLtFld "Left Park Light Failed";
BA_ "VNSigAllNodes" SG_ 2153979904 LftPrkLtFld 1;
BA_ "GenSigSendType" SG_ 2153979904 LftLwBmFld 10;
BA_ "GenSigSendOnInit" SG_ 2153979904 LftLwBmFld 1;
BA_ "SignalType" SG_ 2153979904 LftLwBmFld "BLN";
BA_ "SignalLongName" SG_ 2153979904 LftLwBmFld "Left Low Beam Failed";
BA_ "VNSigAllNodes" SG_ 2153979904 LftLwBmFld 1;
BA_ "GenSigSendType" SG_ 2153979904 LftBrkLtFld 10;
BA_ "GenSigSendOnInit" SG_ 2153979904 LftBrkLtFld 1;
BA_ "SignalType" SG_ 2153979904 LftBrkLtFld "BLN";
BA_ "SignalLongName" SG_ 2153979904 LftBrkLtFld "Left Brake Light Failed";
BA_ "VNSigAllNodes" SG_ 2153979904 LftBrkLtFld 1;
BA_ "GenSigSendType" SG_ 2153979904 FRTrnIndLtFld 10;
BA_ "GenSigSendOnInit" SG_ 2153979904 FRTrnIndLtFld 1;
BA_ "SignalType" SG_ 2153979904 FRTrnIndLtFld "BLN";
BA_ "SignalLongName" SG_ 2153979904 FRTrnIndLtFld "Front Right Turn Indicator Light Failed";
BA_ "VNSigAllNodes" SG_ 2153979904 FRTrnIndLtFld 1;
BA_ "GenSigSendType" SG_ 2153979904 FLTrnIndLtFld 10;
BA_ "GenSigSendOnInit" SG_ 2153979904 FLTrnIndLtFld 1;
BA_ "SignalType" SG_ 2153979904 FLTrnIndLtFld "BLN";
BA_ "SignalLongName" SG_ 2153979904 FLTrnIndLtFld "Front Left Turn Indicator Light Failed";
BA_ "VNSigAllNodes" SG_ 2153979904 FLTrnIndLtFld 1;
BA_ "GenSigSendType" SG_ 2153979904 CHMSLFld 10;
BA_ "GenSigSendOnInit" SG_ 2153979904 CHMSLFld 1;
BA_ "SignalType" SG_ 2153979904 CHMSLFld "BLN";
BA_ "SignalLongName" SG_ 2153979904 CHMSLFld "Center High Mounted Stop Light Failed";
BA_ "VNSigAllNodes" SG_ 2153979904 CHMSLFld 1;
BA_ "GenSigSendType" SG_ 2153979904 LftDytmRunLmpFld 10;
BA_ "GenSigSendOnInit" SG_ 2153979904 LftDytmRunLmpFld 1;
BA_ "SignalType" SG_ 2153979904 LftDytmRunLmpFld "BLN";
BA_ "SignalLongName" SG_ 2153979904 LftDytmRunLmpFld "Left Daytime Running Lamp Failed";
BA_ "VNSigAllNodes" SG_ 2153979904 LftDytmRunLmpFld 1;
BA_ "GenSigSendType" SG_ 2153979904 RvsLtFld 10;
BA_ "GenSigSendOnInit" SG_ 2153979904 RvsLtFld 1;
BA_ "SignalType" SG_ 2153979904 RvsLtFld "BLN";
BA_ "SignalLongName" SG_ 2153979904 RvsLtFld "Reverse Light Failed";
BA_ "VNSigAllNodes" SG_ 2153979904 RvsLtFld 1;
BA_ "GenSigSendType" SG_ 2153979904 RFgLtFld 10;
BA_ "GenSigSendOnInit" SG_ 2153979904 RFgLtFld 1;
BA_ "SignalType" SG_ 2153979904 RFgLtFld "BLN";
BA_ "SignalLongName" SG_ 2153979904 RFgLtFld "Rear Fog Light Failed";
BA_ "VNSigAllNodes" SG_ 2153979904 RFgLtFld 1;
BA_ "SignalType" SG_ 1368 DgnInf_LS558 "UNM";
BA_ "SignalLongName" SG_ 1368 DgnInf_LS558 "Diagnostic Information LS558";
BA_ "VNSigDiagnostic" SG_ 1368 DgnInf_LS558 1;
BA_ "VNSigAllNodes" SG_ 1368 DgnInf_LS558 1;
BA_ "SignalType" SG_ 1372 DgnInf_LS55C "UNM";
BA_ "SignalLongName" SG_ 1372 DgnInf_LS55C "Diagnostic Information LS55C";
BA_ "VNSigDiagnostic" SG_ 1372 DgnInf_LS55C 1;
BA_ "VNSigAllNodes" SG_ 1372 DgnInf_LS55C 1;
BA_ "SignalType" SG_ 1367 DgnInf_LS557 "UNM";
BA_ "SignalLongName" SG_ 1367 DgnInf_LS557 "Diagnostic Information LS557";
BA_ "VNSigDiagnostic" SG_ 1367 DgnInf_LS557 1;
BA_ "VNSigAllNodes" SG_ 1367 DgnInf_LS557 1;
BA_ "SignalType" SG_ 1363 DgnInf_LS553 "UNM";
BA_ "SignalLongName" SG_ 1363 DgnInf_LS553 "Diagnostic Information LS553";
BA_ "VNSigDiagnostic" SG_ 1363 DgnInf_LS553 1;
BA_ "VNSigAllNodes" SG_ 1363 DgnInf_LS553 1;
BA_ "GenSigDeltaValue" SG_ 2150154240 PsvEntVehIdExt 1;
BA_ "GenSigSendType" SG_ 2150154240 PsvEntVehIdExt 12;
BA_ "SignalType" SG_ 2150154240 PsvEntVehIdExt "UNM";
BA_ "SignalLongName" SG_ 2150154240 PsvEntVehIdExt "Passive Entry Vehicle Identifier Extended";
BA_ "VNSigAllNodes" SG_ 2150154240 PsvEntVehIdExt 1;
BA_ "GenSigDeltaValue" SG_ 2150154240 PsvEntChlngRply 1;
BA_ "GenSigSendType" SG_ 2150154240 PsvEntChlngRply 12;
BA_ "SignalType" SG_ 2150154240 PsvEntChlngRply "UNM";
BA_ "SignalLongName" SG_ 2150154240 PsvEntChlngRply "Passive Entry Challenge Reply";
BA_ "VNSigAllNodes" SG_ 2150154240 PsvEntChlngRply 1;
BA_ "GenSigDeltaValue" SG_ 2155003904 LfLnChngThrtAprchSpd 1;
BA_ "GenSigSendType" SG_ 2155003904 LfLnChngThrtAprchSpd 12;
BA_ "SignalType" SG_ 2155003904 LfLnChngThrtAprchSpd "SNM";
BA_ "SignalLongName" SG_ 2155003904 LfLnChngThrtAprchSpd "Left Lane Change Threat Approach Speed";
BA_ "VNSigAllNodes" SG_ 2155003904 LfLnChngThrtAprchSpd 1;
BA_ "GenSigSendType" SG_ 2155003904 LftLnChgThrt 10;
BA_ "GenSigSendOnInit" SG_ 2155003904 LftLnChgThrt 2;
BA_ "SignalType" SG_ 2155003904 LftLnChgThrt "BLN";
BA_ "SignalLongName" SG_ 2155003904 LftLnChgThrt "Left Lane Change Threat";
BA_ "VNSigAllNodes" SG_ 2155003904 LftLnChgThrt 1;
BA_ "GenSigSendType" SG_ 2155003904 SBZATmpUnvIndOn 10;
BA_ "SignalType" SG_ 2155003904 SBZATmpUnvIndOn "BLN";
BA_ "SignalLongName" SG_ 2155003904 SBZATmpUnvIndOn "Side Blind Zone Alert Temporarily Unavailable Indication On";
BA_ "VNSigAllNodes" SG_ 2155003904 SBZATmpUnvIndOn 1;
BA_ "GenSigSendType" SG_ 2155003904 SBZASysSrvIndOn 10;
BA_ "GenSigSendOnInit" SG_ 2155003904 SBZASysSrvIndOn 2;
BA_ "SignalType" SG_ 2155003904 SBZASysSrvIndOn "BLN";
BA_ "SignalLongName" SG_ 2155003904 SBZASysSrvIndOn "Side Blind Zone Alert System Service Indication On";
BA_ "VNSigAllNodes" SG_ 2155003904 SBZASysSrvIndOn 1;
BA_ "GenSigSendType" SG_ 2155003904 SBZASysOffIndOn 10;
BA_ "SignalType" SG_ 2155003904 SBZASysOffIndOn "BLN";
BA_ "SignalLongName" SG_ 2155003904 SBZASysOffIndOn "Side Blind Zone Alert System Off Indication On";
BA_ "VNSigAllNodes" SG_ 2155003904 SBZASysOffIndOn 1;
BA_ "GenSigSendType" SG_ 2155003904 SBZASysClnIndOn 10;
BA_ "SignalType" SG_ 2155003904 SBZASysClnIndOn "BLN";
BA_ "SignalLongName" SG_ 2155003904 SBZASysClnIndOn "Side Blind Zone Alert System Clean Indication On";
BA_ "VNSigAllNodes" SG_ 2155003904 SBZASysClnIndOn 1;
BA_ "SignalType" SG_ 1353 DgnInf_LS549 "UNM";
BA_ "SignalLongName" SG_ 1353 DgnInf_LS549 "Diagnostic Information LS549";
BA_ "VNSigDiagnostic" SG_ 1353 DgnInf_LS549 1;
BA_ "VNSigAllNodes" SG_ 1353 DgnInf_LS549 1;
BA_ "SignalType" SG_ 585 DgnInf "UNM";
BA_ "SignalLongName" SG_ 585 DgnInf "Diagnostic Information";
BA_ "VNSigDiagnostic" SG_ 585 DgnInf 1;
BA_ "VNSigAllNodes" SG_ 585 DgnInf 1;
BA_ "GenSigDeltaValue" SG_ 2150817792 ImpTimeToMaxDeltaVel 1;
BA_ "GenSigSendType" SG_ 2150817792 ImpTimeToMaxDeltaVel 12;
BA_ "VNSigPrimaryTriggering" SG_ 2150817792 ImpTimeToMaxDeltaVel 1;
BA_ "SignalType" SG_ 2150817792 ImpTimeToMaxDeltaVel "UNM";
BA_ "SignalLongName" SG_ 2150817792 ImpTimeToMaxDeltaVel "Impact Time to Maximum Delta Velocity";
BA_ "VNSigAllNodes" SG_ 2150817792 ImpTimeToMaxDeltaVel 1;
BA_ "GenSigDeltaValue" SG_ 2150817792 ImpMaxLongDeltaVel 1;
BA_ "GenSigSendType" SG_ 2150817792 ImpMaxLongDeltaVel 12;
BA_ "VNSigPrimaryTriggering" SG_ 2150817792 ImpMaxLongDeltaVel 1;
BA_ "SignalType" SG_ 2150817792 ImpMaxLongDeltaVel "SNM";
BA_ "SignalLongName" SG_ 2150817792 ImpMaxLongDeltaVel "Impact Maximum Longitudinal Delta Velocity";
BA_ "VNSigAllNodes" SG_ 2150817792 ImpMaxLongDeltaVel 1;
BA_ "GenSigDeltaValue" SG_ 2150817792 ImpMaxLateralDeltaVel 1;
BA_ "GenSigSendType" SG_ 2150817792 ImpMaxLateralDeltaVel 12;
BA_ "VNSigPrimaryTriggering" SG_ 2150817792 ImpMaxLateralDeltaVel 1;
BA_ "SignalType" SG_ 2150817792 ImpMaxLateralDeltaVel "SNM";
BA_ "SignalLongName" SG_ 2150817792 ImpMaxLateralDeltaVel "Impact Maximum Lateral Delta Velocity";
BA_ "VNSigAllNodes" SG_ 2150817792 ImpMaxLateralDeltaVel 1;
BA_ "GenSigSendType" SG_ 2150227968 PhnSpRcgnApSt 10;
BA_ "GenSigSendOnInit" SG_ 2150227968 PhnSpRcgnApSt 2;
BA_ "VNSigInfotainment" SG_ 2150227968 PhnSpRcgnApSt 1;
BA_ "SignalType" SG_ 2150227968 PhnSpRcgnApSt "ENM";
BA_ "SignalLongName" SG_ 2150227968 PhnSpRcgnApSt "Phone Speech Recognition/Audio Prompt Status";
BA_ "VNSigAllNodes" SG_ 2150227968 PhnSpRcgnApSt 1;
BA_ "SignalType" SG_ 1624 DgnInf "UNM";
BA_ "SignalLongName" SG_ 1624 DgnInf "Diagnostic Information";
BA_ "VNSigDiagnostic" SG_ 1624 DgnInf 1;
BA_ "VNSigAllNodes" SG_ 1624 DgnInf 1;
BA_ "SignalType" SG_ 1628 DgnInf "UNM";
BA_ "SignalLongName" SG_ 1628 DgnInf "Diagnostic Information";
BA_ "VNSigDiagnostic" SG_ 1628 DgnInf 1;
BA_ "VNSigAllNodes" SG_ 1628 DgnInf 1;
BA_ "SignalType" SG_ 1623 DgnInf "UNM";
BA_ "SignalLongName" SG_ 1623 DgnInf "Diagnostic Information";
BA_ "VNSigDiagnostic" SG_ 1623 DgnInf 1;
BA_ "VNSigAllNodes" SG_ 1623 DgnInf 1;
BA_ "SignalType" SG_ 1619 DgnInf "UNM";
BA_ "SignalLongName" SG_ 1619 DgnInf "Diagnostic Information";
BA_ "VNSigDiagnostic" SG_ 1619 DgnInf 1;
BA_ "VNSigAllNodes" SG_ 1619 DgnInf 1;
BA_ "SignalType" SG_ 1621 DgnInf "UNM";
BA_ "SignalLongName" SG_ 1621 DgnInf "Diagnostic Information";
BA_ "VNSigDiagnostic" SG_ 1621 DgnInf 1;
BA_ "VNSigAllNodes" SG_ 1621 DgnInf 1;
BA_ "SignalType" SG_ 1365 DgnInf_LS555 "UNM";
BA_ "SignalLongName" SG_ 1365 DgnInf_LS555 "Diagnostic Information LS555";
BA_ "VNSigDiagnostic" SG_ 1365 DgnInf_LS555 1;
BA_ "VNSigAllNodes" SG_ 1365 DgnInf_LS555 1;
BA_ "SignalType" SG_ 600 DgnInf "UNM";
BA_ "SignalLongName" SG_ 600 DgnInf "Diagnostic Information";
BA_ "VNSigDiagnostic" SG_ 600 DgnInf 1;
BA_ "VNSigAllNodes" SG_ 600 DgnInf 1;
BA_ "SignalType" SG_ 604 DgnInf "UNM";
BA_ "SignalLongName" SG_ 604 DgnInf "Diagnostic Information";
BA_ "VNSigDiagnostic" SG_ 604 DgnInf 1;
BA_ "VNSigAllNodes" SG_ 604 DgnInf 1;
BA_ "SignalType" SG_ 599 DgnInf "UNM";
BA_ "SignalLongName" SG_ 599 DgnInf "Diagnostic Information";
BA_ "VNSigDiagnostic" SG_ 599 DgnInf 1;
BA_ "VNSigAllNodes" SG_ 599 DgnInf 1;
BA_ "SignalType" SG_ 597 DgnInf "UNM";
BA_ "SignalLongName" SG_ 597 DgnInf "Diagnostic Information";
BA_ "VNSigDiagnostic" SG_ 597 DgnInf 1;
BA_ "VNSigAllNodes" SG_ 597 DgnInf 1;
BA_ "VNSigPrimaryTriggering" SG_ 1568 VectraSpcNWMgtD 1;
BA_ "VNSigRemoteDiagnostics" SG_ 1568 VectraSpcNWMgtD 1;
BA_ "VNSigInfotainment" SG_ 1568 VectraSpcNWMgtD 1;
BA_ "VNSigParkedVehicle" SG_ 1568 VectraSpcNWMgtD 1;
BA_ "VNSigIntermediate" SG_ 1568 VectraSpcNWMgtD 1;
BA_ "VNSigUnused_4" SG_ 1568 VectraSpcNWMgtD 1;
BA_ "SignalType" SG_ 1568 VectraSpcNWMgtD "UNM";
BA_ "SignalLongName" SG_ 1568 VectraSpcNWMgtD "Vectra Specific Network Management Data";
BA_ "VNSigDiagnostic" SG_ 1568 VectraSpcNWMgtD 1;
BA_ "VNSigAllNodes" SG_ 1568 VectraSpcNWMgtD 1;
BA_ "VNSigPrimaryTriggering" SG_ 1570 VectraSpcNWMgtD 1;
BA_ "VNSigRemoteDiagnostics" SG_ 1570 VectraSpcNWMgtD 1;
BA_ "VNSigInfotainment" SG_ 1570 VectraSpcNWMgtD 1;
BA_ "VNSigParkedVehicle" SG_ 1570 VectraSpcNWMgtD 1;
BA_ "VNSigIntermediate" SG_ 1570 VectraSpcNWMgtD 1;
BA_ "VNSigUnused_4" SG_ 1570 VectraSpcNWMgtD 1;
BA_ "SignalType" SG_ 1570 VectraSpcNWMgtD "UNM";
BA_ "SignalLongName" SG_ 1570 VectraSpcNWMgtD "Vectra Specific Network Management Data";
BA_ "VNSigDiagnostic" SG_ 1570 VectraSpcNWMgtD 1;
BA_ "VNSigAllNodes" SG_ 1570 VectraSpcNWMgtD 1;
BA_ "GenSigSendOnInit" SG_ 2162982912 VehIdNmDig10_17 2;
BA_ "VNSigInfotainment" SG_ 2162982912 VehIdNmDig10_17 1;
BA_ "SignalType" SG_ 2162982912 VehIdNmDig10_17 "ASC";
BA_ "SignalLongName" SG_ 2162982912 VehIdNmDig10_17 "Vehicle Identification Number Digits 10-17";
BA_ "VNSigAllNodes" SG_ 2162982912 VehIdNmDig10_17 1;
BA_ "GenSigSendOnInit" SG_ 2162966528 VehIdNmDig2_9 2;
BA_ "VNSigInfotainment" SG_ 2162966528 VehIdNmDig2_9 1;
BA_ "SignalType" SG_ 2162966528 VehIdNmDig2_9 "ASC";
BA_ "SignalLongName" SG_ 2162966528 VehIdNmDig2_9 "Vehicle Identification Number Digits 2-9";
BA_ "VNSigAllNodes" SG_ 2162966528 VehIdNmDig2_9 1;
BA_ "GenSigDeltaValue" SG_ 2151497728 TireLFPrs 1;
BA_ "GenSigSendType" SG_ 2151497728 TireLFPrs 12;
BA_ "GenSigSendOnInit" SG_ 2151497728 TireLFPrs 1;
BA_ "SignalType" SG_ 2151497728 TireLFPrs "UNM";
BA_ "SignalLongName" SG_ 2151497728 TireLFPrs "Tire Left Front Pressure";
BA_ "GenSigStartValue" SG_ 2151497728 TireLFPrs 255;
BA_ "VNSigAllNodes" SG_ 2151497728 TireLFPrs 1;
BA_ "GenSigSendType" SG_ 2151497728 TireLFPrsStat 10;
BA_ "GenSigSendOnInit" SG_ 2151497728 TireLFPrsStat 1;
BA_ "SignalType" SG_ 2151497728 TireLFPrsStat "ENM";
BA_ "SignalLongName" SG_ 2151497728 TireLFPrsStat "Tire Left Front Pressure Status";
BA_ "VNSigAllNodes" SG_ 2151497728 TireLFPrsStat 1;
BA_ "GenSigSendType" SG_ 2151497728 TireLFPrsV 10;
BA_ "GenSigSendOnInit" SG_ 2151497728 TireLFPrsV 1;
BA_ "SignalType" SG_ 2151497728 TireLFPrsV "ENM";
BA_ "SignalLongName" SG_ 2151497728 TireLFPrsV "Tire Left Front Pressure Validity";
BA_ "VNSigAllNodes" SG_ 2151497728 TireLFPrsV 1;
BA_ "GenSigDeltaValue" SG_ 2151497728 TireLRPrs 1;
BA_ "GenSigSendType" SG_ 2151497728 TireLRPrs 12;
BA_ "GenSigSendOnInit" SG_ 2151497728 TireLRPrs 1;
BA_ "SignalType" SG_ 2151497728 TireLRPrs "UNM";
BA_ "SignalLongName" SG_ 2151497728 TireLRPrs "Tire Left Rear Pressure";
BA_ "GenSigStartValue" SG_ 2151497728 TireLRPrs 255;
BA_ "VNSigAllNodes" SG_ 2151497728 TireLRPrs 1;
BA_ "GenSigSendType" SG_ 2151497728 TireLRPrsStat 10;
BA_ "GenSigSendOnInit" SG_ 2151497728 TireLRPrsStat 1;
BA_ "SignalType" SG_ 2151497728 TireLRPrsStat "ENM";
BA_ "SignalLongName" SG_ 2151497728 TireLRPrsStat "Tire Left Rear Pressure Status";
BA_ "VNSigAllNodes" SG_ 2151497728 TireLRPrsStat 1;
BA_ "GenSigSendType" SG_ 2151497728 TireLRPrsV 10;
BA_ "GenSigSendOnInit" SG_ 2151497728 TireLRPrsV 1;
BA_ "SignalType" SG_ 2151497728 TireLRPrsV "ENM";
BA_ "SignalLongName" SG_ 2151497728 TireLRPrsV "Tire Left Rear Pressure Validity";
BA_ "VNSigAllNodes" SG_ 2151497728 TireLRPrsV 1;
BA_ "GenSigDeltaValue" SG_ 2151497728 TireRFPrs 1;
BA_ "GenSigSendType" SG_ 2151497728 TireRFPrs 12;
BA_ "GenSigSendOnInit" SG_ 2151497728 TireRFPrs 1;
BA_ "SignalType" SG_ 2151497728 TireRFPrs "UNM";
BA_ "SignalLongName" SG_ 2151497728 TireRFPrs "Tire Right Front Pressure";
BA_ "GenSigStartValue" SG_ 2151497728 TireRFPrs 255;
BA_ "VNSigAllNodes" SG_ 2151497728 TireRFPrs 1;
BA_ "GenSigSendType" SG_ 2151497728 TireRFPrsStat 10;
BA_ "GenSigSendOnInit" SG_ 2151497728 TireRFPrsStat 1;
BA_ "SignalType" SG_ 2151497728 TireRFPrsStat "ENM";
BA_ "SignalLongName" SG_ 2151497728 TireRFPrsStat "Tire Right Front Pressure Status";
BA_ "VNSigAllNodes" SG_ 2151497728 TireRFPrsStat 1;
BA_ "GenSigSendType" SG_ 2151497728 TireRFPrsV 10;
BA_ "GenSigSendOnInit" SG_ 2151497728 TireRFPrsV 1;
BA_ "SignalType" SG_ 2151497728 TireRFPrsV "ENM";
BA_ "SignalLongName" SG_ 2151497728 TireRFPrsV "Tire Right Front Pressure Validity";
BA_ "VNSigAllNodes" SG_ 2151497728 TireRFPrsV 1;
BA_ "GenSigDeltaValue" SG_ 2151497728 TireRRPrs 1;
BA_ "GenSigSendType" SG_ 2151497728 TireRRPrs 12;
BA_ "GenSigSendOnInit" SG_ 2151497728 TireRRPrs 1;
BA_ "SignalType" SG_ 2151497728 TireRRPrs "UNM";
BA_ "SignalLongName" SG_ 2151497728 TireRRPrs "Tire Right Rear Pressure";
BA_ "GenSigStartValue" SG_ 2151497728 TireRRPrs 255;
BA_ "VNSigAllNodes" SG_ 2151497728 TireRRPrs 1;
BA_ "GenSigSendType" SG_ 2151497728 TireRRPrsStat 10;
BA_ "GenSigSendOnInit" SG_ 2151497728 TireRRPrsStat 1;
BA_ "SignalType" SG_ 2151497728 TireRRPrsStat "ENM";
BA_ "SignalLongName" SG_ 2151497728 TireRRPrsStat "Tire Right Rear Pressure Status";
BA_ "VNSigAllNodes" SG_ 2151497728 TireRRPrsStat 1;
BA_ "GenSigSendType" SG_ 2151497728 TireRRPrsV 10;
BA_ "GenSigSendOnInit" SG_ 2151497728 TireRRPrsV 1;
BA_ "SignalType" SG_ 2151497728 TireRRPrsV "ENM";
BA_ "SignalLongName" SG_ 2151497728 TireRRPrsV "Tire Right Rear Pressure Validity";
BA_ "VNSigAllNodes" SG_ 2151497728 TireRRPrsV 1;
BA_ "GenSigSendType" SG_ 2151219200 RemStrtSt 10;
BA_ "GenSigSendOnInit" SG_ 2151219200 RemStrtSt 2;
BA_ "VNSigInfotainment" SG_ 2151219200 RemStrtSt 1;
BA_ "SignalType" SG_ 2151219200 RemStrtSt "ENM";
BA_ "SignalLongName" SG_ 2151219200 RemStrtSt "Remote Start Status";
BA_ "VNSigAllNodes" SG_ 2151219200 RemStrtSt 1;
BA_ "GenSigSendType" SG_ 2151219200 RmVehStrRq 10;
BA_ "SignalType" SG_ 2151219200 RmVehStrRq "ENM";
BA_ "SignalLongName" SG_ 2151219200 RmVehStrRq "Remote Vehicle Start Request";
BA_ "VNSigAllNodes" SG_ 2151219200 RmVehStrRq 1;
BA_ "GenSigSendType" SG_ 2153775104 DTCI_DTCFaultType 10;
BA_ "SignalType" SG_ 2153775104 DTCI_DTCFaultType "ENM";
BA_ "PacketOrder" SG_ 2153775104 DTCI_DTCFaultType 20;
BA_ "SignalLongName" SG_ 2153775104 DTCI_DTCFaultType "Diagnostic Trouble Code Information Extended : Diagnostic Trouble Code Fault Type";
BA_ "VNSigAllNodes" SG_ 2153775104 DTCI_DTCFaultType 1;
BA_ "GenSigSendType" SG_ 2153775104 DTCI_CodeSupported 10;
BA_ "SignalType" SG_ 2153775104 DTCI_CodeSupported "BLN";
BA_ "PacketOrder" SG_ 2153775104 DTCI_CodeSupported 19;
BA_ "SignalLongName" SG_ 2153775104 DTCI_CodeSupported "Diagnostic Trouble Code Information Extended : Code Supported";
BA_ "VNSigAllNodes" SG_ 2153775104 DTCI_CodeSupported 1;
BA_ "GenSigSendType" SG_ 2153775104 DTCI_CurrentStatus 10;
BA_ "SignalType" SG_ 2153775104 DTCI_CurrentStatus "BLN";
BA_ "PacketOrder" SG_ 2153775104 DTCI_CurrentStatus 18;
BA_ "SignalLongName" SG_ 2153775104 DTCI_CurrentStatus "Diagnostic Trouble Code Information Extended : Current Status";
BA_ "VNSigAllNodes" SG_ 2153775104 DTCI_CurrentStatus 1;
BA_ "GenSigSendType" SG_ 2153775104 DTCI_TstNPsdCdClrdSt 10;
BA_ "SignalType" SG_ 2153775104 DTCI_TstNPsdCdClrdSt "BLN";
BA_ "PacketOrder" SG_ 2153775104 DTCI_TstNPsdCdClrdSt 17;
BA_ "SignalLongName" SG_ 2153775104 DTCI_TstNPsdCdClrdSt "Diagnostic Trouble Code Information Extended : Test Not Passed Since Code Cleared Status";
BA_ "VNSigAllNodes" SG_ 2153775104 DTCI_TstNPsdCdClrdSt 1;
BA_ "GenSigSendType" SG_ 2153775104 DTCI_TstFldCdClrdStat 10;
BA_ "SignalType" SG_ 2153775104 DTCI_TstFldCdClrdStat "BLN";
BA_ "PacketOrder" SG_ 2153775104 DTCI_TstFldCdClrdStat 16;
BA_ "SignalLongName" SG_ 2153775104 DTCI_TstFldCdClrdStat "Diagnostic Trouble Code Information Extended : Test Failed Since Code Cleared Status";
BA_ "VNSigAllNodes" SG_ 2153775104 DTCI_TstFldCdClrdStat 1;
BA_ "GenSigSendType" SG_ 2153775104 DTCI_HistStat 10;
BA_ "SignalType" SG_ 2153775104 DTCI_HistStat "BLN";
BA_ "PacketOrder" SG_ 2153775104 DTCI_HistStat 15;
BA_ "SignalLongName" SG_ 2153775104 DTCI_HistStat "Diagnostic Trouble Code Information Extended : History Status";
BA_ "VNSigAllNodes" SG_ 2153775104 DTCI_HistStat 1;
BA_ "GenSigSendType" SG_ 2153775104 DTCI_TstNPsdPwrUpSt 10;
BA_ "SignalType" SG_ 2153775104 DTCI_TstNPsdPwrUpSt "BLN";
BA_ "PacketOrder" SG_ 2153775104 DTCI_TstNPsdPwrUpSt 14;
BA_ "SignalLongName" SG_ 2153775104 DTCI_TstNPsdPwrUpSt "Diagnostic Trouble Code Information Extended : Test Not Passed Since Power Up Status";
BA_ "VNSigAllNodes" SG_ 2153775104 DTCI_TstNPsdPwrUpSt 1;
BA_ "GenSigSendType" SG_ 2153775104 DTCI_TstFldPwrUpSt 10;
BA_ "SignalType" SG_ 2153775104 DTCI_TstFldPwrUpSt "BLN";
BA_ "PacketOrder" SG_ 2153775104 DTCI_TstFldPwrUpSt 13;
BA_ "SignalLongName" SG_ 2153775104 DTCI_TstFldPwrUpSt "Diagnostic Trouble Code Information Extended : Test Failed Since Power Up Status";
BA_ "VNSigAllNodes" SG_ 2153775104 DTCI_TstFldPwrUpSt 1;
BA_ "GenSigSendType" SG_ 2153775104 DTCI_WrnIndRqdSt 10;
BA_ "SignalType" SG_ 2153775104 DTCI_WrnIndRqdSt "BLN";
BA_ "PacketOrder" SG_ 2153775104 DTCI_WrnIndRqdSt 12;
BA_ "SignalLongName" SG_ 2153775104 DTCI_WrnIndRqdSt "Diagnostic Trouble Code Information Extended : Warning Indicator Requested Status";
BA_ "VNSigAllNodes" SG_ 2153775104 DTCI_WrnIndRqdSt 1;
BA_ "GenSigDeltaValue" SG_ 2153775104 DTCI_DTCFailType 1;
BA_ "GenSigSendType" SG_ 2153775104 DTCI_DTCFailType 12;
BA_ "SignalType" SG_ 2153775104 DTCI_DTCFailType "UNM";
BA_ "PacketOrder" SG_ 2153775104 DTCI_DTCFailType 11;
BA_ "SignalLongName" SG_ 2153775104 DTCI_DTCFailType "Diagnostic Trouble Code Information Extended : Diagnostic Trouble Code Failure Type";
BA_ "VNSigAllNodes" SG_ 2153775104 DTCI_DTCFailType 1;
BA_ "GenSigDeltaValue" SG_ 2153775104 DTCI_DTCNumber 1;
BA_ "GenSigSendType" SG_ 2153775104 DTCI_DTCNumber 12;
BA_ "SignalType" SG_ 2153775104 DTCI_DTCNumber "UNM";
BA_ "PacketOrder" SG_ 2153775104 DTCI_DTCNumber 10;
BA_ "SignalLongName" SG_ 2153775104 DTCI_DTCNumber "Diagnostic Trouble Code Information Extended : Diagnostic Trouble Code Number";
BA_ "VNSigAllNodes" SG_ 2153775104 DTCI_DTCNumber 1;
BA_ "GenSigDeltaValue" SG_ 2153775104 DTCI_DTCSource 1;
BA_ "GenSigSendType" SG_ 2153775104 DTCI_DTCSource 12;
BA_ "SignalType" SG_ 2153775104 DTCI_DTCSource "UNM";
BA_ "PacketOrder" SG_ 2153775104 DTCI_DTCSource 9;
BA_ "SignalLongName" SG_ 2153775104 DTCI_DTCSource "Diagnostic Trouble Code Information Extended : Diagnostic Trouble Code Source";
BA_ "VNSigAllNodes" SG_ 2153775104 DTCI_DTCSource 1;
BA_ "GenSigSendType" SG_ 2153775104 DTCI_DTCTriggered 10;
BA_ "SignalType" SG_ 2153775104 DTCI_DTCTriggered "BLN";
BA_ "PacketOrder" SG_ 2153775104 DTCI_DTCTriggered 8;
BA_ "SignalLongName" SG_ 2153775104 DTCI_DTCTriggered "Diagnostic Trouble Code Information Extended : Diagnostic Trouble Code Triggered";
BA_ "VNSigAllNodes" SG_ 2153775104 DTCI_DTCTriggered 1;
BA_ "GenSigSendType" SG_ 2153775104 DTCIUnused7 10;
BA_ "SignalType" SG_ 2153775104 DTCIUnused7 "BLN";
BA_ "PacketOrder" SG_ 2153775104 DTCIUnused7 1;
BA_ "SignalLongName" SG_ 2153775104 DTCIUnused7 "Diagnostic Trouble Code Information Extended : Unused 7";
BA_ "VNSigAllNodes" SG_ 2153775104 DTCIUnused7 1;
BA_ "GenSigSendType" SG_ 2153775104 DTCIUnused6 10;
BA_ "SignalType" SG_ 2153775104 DTCIUnused6 "BLN";
BA_ "PacketOrder" SG_ 2153775104 DTCIUnused6 2;
BA_ "SignalLongName" SG_ 2153775104 DTCIUnused6 "Diagnostic Trouble Code Information Extended : Unused 6";
BA_ "VNSigAllNodes" SG_ 2153775104 DTCIUnused6 1;
BA_ "GenSigSendType" SG_ 2153775104 DTCIUnused5 10;
BA_ "SignalType" SG_ 2153775104 DTCIUnused5 "BLN";
BA_ "PacketOrder" SG_ 2153775104 DTCIUnused5 3;
BA_ "SignalLongName" SG_ 2153775104 DTCIUnused5 "Diagnostic Trouble Code Information Extended : Unused 5";
BA_ "VNSigAllNodes" SG_ 2153775104 DTCIUnused5 1;
BA_ "GenSigSendType" SG_ 2153775104 DTCIUnused4 10;
BA_ "SignalType" SG_ 2153775104 DTCIUnused4 "BLN";
BA_ "PacketOrder" SG_ 2153775104 DTCIUnused4 4;
BA_ "SignalLongName" SG_ 2153775104 DTCIUnused4 "Diagnostic Trouble Code Information Extended : Unused 4";
BA_ "VNSigAllNodes" SG_ 2153775104 DTCIUnused4 1;
BA_ "GenSigSendType" SG_ 2153775104 DTCIUnused3 10;
BA_ "SignalType" SG_ 2153775104 DTCIUnused3 "BLN";
BA_ "PacketOrder" SG_ 2153775104 DTCIUnused3 5;
BA_ "SignalLongName" SG_ 2153775104 DTCIUnused3 "Diagnostic Trouble Code Information Extended : Unused 3";
BA_ "VNSigAllNodes" SG_ 2153775104 DTCIUnused3 1;
BA_ "GenSigSendType" SG_ 2153775104 DTCIUnused2 10;
BA_ "SignalType" SG_ 2153775104 DTCIUnused2 "BLN";
BA_ "PacketOrder" SG_ 2153775104 DTCIUnused2 6;
BA_ "SignalLongName" SG_ 2153775104 DTCIUnused2 "Diagnostic Trouble Code Information Extended : Unused 2";
BA_ "VNSigAllNodes" SG_ 2153775104 DTCIUnused2 1;
BA_ "GenSigSendType" SG_ 2153775104 DTCIUnused1 10;
BA_ "SignalType" SG_ 2153775104 DTCIUnused1 "BLN";
BA_ "PacketOrder" SG_ 2153775104 DTCIUnused1 7;
BA_ "SignalLongName" SG_ 2153775104 DTCIUnused1 "Diagnostic Trouble Code Information Extended : Unused 1";
BA_ "VNSigAllNodes" SG_ 2153775104 DTCIUnused1 1;
BA_REL_ "GenSigSuprvResp" BU_SG_REL_ EOCM2B_K2_LS SG_ 2154905600 DrvSeatPrsMemID 1;
BA_REL_ "GenSigSuprvResp" BU_SG_REL_ EOCM2A_K2_LS SG_ 2154905600 DrvSeatPrsMemID 1;
BA_REL_ "GenSigSuprvResp" BU_SG_REL_ IPC_LS SG_ 2154905600 DrvSeatPrsMemID 1;
BA_REL_ "GenSigSuprvResp" BU_SG_REL_ CHUD_LS SG_ 2154905600 DrvSeatPrsMemID 1;
BA_REL_ "GenSigSuprvResp" BU_SG_REL_ HUD_LS SG_ 2154905600 DrvSeatPrsMemID 1;
BA_REL_ "GenSigSuprvResp" BU_SG_REL_ MSM_P_LS SG_ 2154905600 DrvSeatPrsMemID 1;
BA_REL_ "GenSigSuprvResp" BU_SG_REL_ MSM_LS SG_ 2154905600 DrvSeatPrsMemID 1;
BA_REL_ "GenSigSuprvResp" BU_SG_REL_ EOCM2B_K2_LS SG_ 2154905600 DrId 1;
BA_REL_ "GenSigSuprvResp" BU_SG_REL_ EOCM2A_K2_LS SG_ 2154905600 DrId 1;
BA_REL_ "GenSigSuprvResp" BU_SG_REL_ EOCM_F_LS SG_ 2154905600 DrId 1;
BA_REL_ "GenSigSuprvResp" BU_SG_REL_ MSM_P_LS SG_ 2154905600 DrId 1;
BA_REL_ "GenSigSuprvResp" BU_SG_REL_ MSM_LS SG_ 2154905600 DrId 1;
BA_REL_ "GenSigSuprvResp" BU_SG_REL_ VICM_LS SG_ 2154954752 ClmtHtPwrRqd 1;
BA_REL_ "GenSigSuprvResp" BU_SG_REL_ IPC_LS SG_ 2153381888 VltActRrAccUnavlIO 1;
BA_REL_ "GenSigSuprvResp" BU_SG_REL_ IPC_LS SG_ 2153381888 PwrLftgtMotStat 1;
BA_REL_ "GenSigSuprvResp" BU_SG_REL_ ECC_LS SG_ 2153381888 PwrLftgtMotStat 1;
BA_REL_ "GenSigSuprvResp" BU_SG_REL_ ARB_LS SG_ 2153381888 RrClosOpenSwAct 1;
BA_REL_ "GenSigVBitResp" BU_SG_REL_ BCM_LS SG_ 2153381888 RrClosOpenSwAct 1;
BA_REL_ "GenSigSuprvResp" BU_SG_REL_ BCM_LS SG_ 2153381888 RrClosOpenSwAct 1;
BA_REL_ "GenSigSuprvResp" BU_SG_REL_ BCM_LS SG_ 2153381888 RrClsrInMtn 1;
BA_REL_ "GenSigSuprvResp" BU_SG_REL_ BCM_LS SG_ 2153381888 RrClsrInMtn 1;
BA_REL_ "GenSigSuprvResp" BU_SG_REL_ IPC_LS SG_ 2149752832 SndEnhcmtPerfMdRq 1;
BA_REL_ "GenSigSuprvResp" BU_SG_REL_ ONSTAR_LS SG_ 2149752832 ElecPrkBrkStat 1;
BA_REL_ "GenSigSuprvResp" BU_SG_REL_ TCP_LS SG_ 2149752832 ElecPrkBrkStat 1;
BA_REL_ "GenSigSuprvResp" BU_SG_REL_ MSM_P_LS SG_ 2149752832 ElecPrkBrkStat 1;
BA_REL_ "GenSigSuprvResp" BU_SG_REL_ MSM_LS SG_ 2149752832 ElecPrkBrkStat 1;
BA_REL_ "GenSigSuprvResp" BU_SG_REL_ V2V_LS SG_ 2149752832 ElecPrkBrkStat 1;
BA_REL_ "GenSigSuprvResp" BU_SG_REL_ LVMNav_LS SG_ 2149752832 ElecPrkBrkStat 1;
BA_REL_ "GenSigVDAFailComment" BU_SG_REL_ UPA_LS SG_ 2149752832 ElecPrkBrkStat "Park Brake Virtual Device Availability";
BA_REL_ "GenSigVDAFailResp" BU_SG_REL_ UPA_LS SG_ 2149752832 ElecPrkBrkStat 1;
BA_REL_ "GenSigSuprvResp" BU_SG_REL_ UPA_LS SG_ 2149752832 ElecPrkBrkStat 1;
BA_REL_ "GenSigVDAFailComment" BU_SG_REL_ APA_LS SG_ 2149752832 ElecPrkBrkStat "Park Brake Virtual Device Availability";
BA_REL_ "GenSigVDAFailResp" BU_SG_REL_ APA_LS SG_ 2149752832 ElecPrkBrkStat 1;
BA_REL_ "GenSigSuprvResp" BU_SG_REL_ APA_LS SG_ 2149752832 ElecPrkBrkStat 1;
BA_REL_ "GenSigSuprvResp" BU_SG_REL_ SDM_LS SG_ 2149752832 ABSAtv 1;
BA_REL_ "GenSigSuprvResp" BU_SG_REL_ VIS2_LS SG_ 2149752832 ABSAtv 1;
BA_REL_ "GenSigSuprvResp" BU_SG_REL_ FCM_LS SG_ 2149752832 ABSAtv 1;
BA_REL_ "GenSigSuprvResp" BU_SG_REL_ VPM_LS SG_ 2149752832 SprTireSt 1;
BA_REL_ "GenSigVBitResp" BU_SG_REL_ VPM_LS SG_ 2149752832 VehHghtStat 1;
BA_REL_ "GenSigVBitRespComment" BU_SG_REL_ VPM_LS SG_ 2149752832 VehHghtStat "VehHghtStatV";
BA_REL_ "GenSigSuprvResp" BU_SG_REL_ VPM_LS SG_ 2149752832 VehHghtStat 1;
BA_REL_ "GenSigSuprvResp" BU_SG_REL_ EOCM2B_K2_LS SG_ 2158903296 ODDMA_ReqType 1;
BA_REL_ "GenSigSuprvResp" BU_SG_REL_ EOCM2A_K2_LS SG_ 2158903296 ODDMA_ReqType 1;
BA_REL_ "GenSigSuprvResp" BU_SG_REL_ EOCM_F_LS SG_ 2158903296 ODDMA_ReqType 1;
BA_REL_ "GenSigSuprvResp" BU_SG_REL_ EOCM_F_LS SG_ 2158903296 ODDMA_ReqType 1;
BA_REL_ "GenSigSuprvResp" BU_SG_REL_ UPA_LS SG_ 2158903296 ODDMA_ReqType 1;
BA_REL_ "GenSigSuprvResp" BU_SG_REL_ APA_LS SG_ 2158903296 ODDMA_ReqType 1;
BA_REL_ "GenSigSuprvResp" BU_SG_REL_ EOCM2B_K2_LS SG_ 2158903296 ODDMA_FUCID 1;
BA_REL_ "GenSigSuprvResp" BU_SG_REL_ EOCM2A_K2_LS SG_ 2158903296 ODDMA_FUCID 1;
BA_REL_ "GenSigSuprvResp" BU_SG_REL_ EOCM_F_LS SG_ 2158903296 ODDMA_FUCID 1;
BA_REL_ "GenSigSuprvResp" BU_SG_REL_ EOCM_F_LS SG_ 2158903296 ODDMA_FUCID 1;
BA_REL_ "GenSigSuprvResp" BU_SG_REL_ UPA_LS SG_ 2158903296 ODDMA_FUCID 1;
BA_REL_ "GenSigSuprvResp" BU_SG_REL_ APA_LS SG_ 2158903296 ODDMA_FUCID 1;
BA_REL_ "GenSigSuprvResp" BU_SG_REL_ EOCM2B_K2_LS SG_ 2158903296 ODDMA_DispMID 1;
BA_REL_ "GenSigSuprvResp" BU_SG_REL_ EOCM2A_K2_LS SG_ 2158903296 ODDMA_DispMID 1;
BA_REL_ "GenSigSuprvResp" BU_SG_REL_ EOCM_F_LS SG_ 2158903296 ODDMA_DispMID 1;
BA_REL_ "GenSigSuprvResp" BU_SG_REL_ EOCM_F_LS SG_ 2158903296 ODDMA_DispMID 1;
BA_REL_ "GenSigSuprvResp" BU_SG_REL_ UPA_LS SG_ 2158903296 ODDMA_DispMID 1;
BA_REL_ "GenSigSuprvResp" BU_SG_REL_ APA_LS SG_ 2158903296 ODDMA_DispMID 1;
BA_REL_ "GenSigSuprvResp" BU_SG_REL_ EOCM2B_K2_LS SG_ 2158903296 ODDMA_DataID2Vld 1;
BA_REL_ "GenSigSuprvResp" BU_SG_REL_ EOCM2A_K2_LS SG_ 2158903296 ODDMA_DataID2Vld 1;
BA_REL_ "GenSigSuprvResp" BU_SG_REL_ EOCM_F_LS SG_ 2158903296 ODDMA_DataID2Vld 1;
BA_REL_ "GenSigSuprvResp" BU_SG_REL_ EOCM_F_LS SG_ 2158903296 ODDMA_DataID2Vld 1;
BA_REL_ "GenSigSuprvResp" BU_SG_REL_ UPA_LS SG_ 2158903296 ODDMA_DataID2Vld 1;
BA_REL_ "GenSigSuprvResp" BU_SG_REL_ APA_LS SG_ 2158903296 ODDMA_DataID2Vld 1;
BA_REL_ "GenSigSuprvResp" BU_SG_REL_ EOCM2B_K2_LS SG_ 2158903296 ODDMA_DataID2 1;
BA_REL_ "GenSigSuprvResp" BU_SG_REL_ EOCM2A_K2_LS SG_ 2158903296 ODDMA_DataID2 1;
BA_REL_ "GenSigSuprvResp" BU_SG_REL_ EOCM_F_LS SG_ 2158903296 ODDMA_DataID2 1;
BA_REL_ "GenSigSuprvResp" BU_SG_REL_ EOCM_F_LS SG_ 2158903296 ODDMA_DataID2 1;
BA_REL_ "GenSigSuprvResp" BU_SG_REL_ UPA_LS SG_ 2158903296 ODDMA_DataID2 1;
BA_REL_ "GenSigSuprvResp" BU_SG_REL_ APA_LS SG_ 2158903296 ODDMA_DataID2 1;
BA_REL_ "GenSigSuprvResp" BU_SG_REL_ EOCM2B_K2_LS SG_ 2158903296 ODDMA_DataID3Vld 1;
BA_REL_ "GenSigSuprvResp" BU_SG_REL_ EOCM2A_K2_LS SG_ 2158903296 ODDMA_DataID3Vld 1;
BA_REL_ "GenSigSuprvResp" BU_SG_REL_ EOCM_F_LS SG_ 2158903296 ODDMA_DataID3Vld 1;
BA_REL_ "GenSigSuprvResp" BU_SG_REL_ EOCM_F_LS SG_ 2158903296 ODDMA_DataID3Vld 1;
BA_REL_ "GenSigSuprvResp" BU_SG_REL_ UPA_LS SG_ 2158903296 ODDMA_DataID3Vld 1;
BA_REL_ "GenSigSuprvResp" BU_SG_REL_ APA_LS SG_ 2158903296 ODDMA_DataID3Vld 1;
BA_REL_ "GenSigSuprvResp" BU_SG_REL_ EOCM2B_K2_LS SG_ 2158903296 ODDMA_DataID3 1;
BA_REL_ "GenSigSuprvResp" BU_SG_REL_ EOCM2A_K2_LS SG_ 2158903296 ODDMA_DataID3 1;
BA_REL_ "GenSigSuprvResp" BU_SG_REL_ EOCM_F_LS SG_ 2158903296 ODDMA_DataID3 1;
BA_REL_ "GenSigSuprvResp" BU_SG_REL_ EOCM_F_LS SG_ 2158903296 ODDMA_DataID3 1;
BA_REL_ "GenSigSuprvResp" BU_SG_REL_ UPA_LS SG_ 2158903296 ODDMA_DataID3 1;
BA_REL_ "GenSigSuprvResp" BU_SG_REL_ APA_LS SG_ 2158903296 ODDMA_DataID3 1;
BA_REL_ "GenSigSuprvResp" BU_SG_REL_ EOCM2B_K2_LS SG_ 2158903296 ODDMA_DataID1 1;
BA_REL_ "GenSigSuprvResp" BU_SG_REL_ EOCM2A_K2_LS SG_ 2158903296 ODDMA_DataID1 1;
BA_REL_ "GenSigSuprvResp" BU_SG_REL_ EOCM_F_LS SG_ 2158903296 ODDMA_DataID1 1;
BA_REL_ "GenSigSuprvResp" BU_SG_REL_ EOCM_F_LS SG_ 2158903296 ODDMA_DataID1 1;
BA_REL_ "GenSigSuprvResp" BU_SG_REL_ UPA_LS SG_ 2158903296 ODDMA_DataID1 1;
BA_REL_ "GenSigSuprvResp" BU_SG_REL_ APA_LS SG_ 2158903296 ODDMA_DataID1 1;
BA_REL_ "GenSigSuprvResp" BU_SG_REL_ EOCM2B_K2_LS SG_ 2158903296 ODDMA_DataID4Vld 1;
BA_REL_ "GenSigSuprvResp" BU_SG_REL_ EOCM2A_K2_LS SG_ 2158903296 ODDMA_DataID4Vld 1;
BA_REL_ "GenSigSuprvResp" BU_SG_REL_ EOCM_F_LS SG_ 2158903296 ODDMA_DataID4Vld 1;
BA_REL_ "GenSigSuprvResp" BU_SG_REL_ EOCM_F_LS SG_ 2158903296 ODDMA_DataID4Vld 1;
BA_REL_ "GenSigSuprvResp" BU_SG_REL_ UPA_LS SG_ 2158903296 ODDMA_DataID4Vld 1;
BA_REL_ "GenSigSuprvResp" BU_SG_REL_ APA_LS SG_ 2158903296 ODDMA_DataID4Vld 1;
BA_REL_ "GenSigSuprvResp" BU_SG_REL_ EOCM2B_K2_LS SG_ 2158903296 ODDMA_DataID4 1;
BA_REL_ "GenSigSuprvResp" BU_SG_REL_ EOCM2A_K2_LS SG_ 2158903296 ODDMA_DataID4 1;
BA_REL_ "GenSigSuprvResp" BU_SG_REL_ EOCM_F_LS SG_ 2158903296 ODDMA_DataID4 1;
BA_REL_ "GenSigSuprvResp" BU_SG_REL_ EOCM_F_LS SG_ 2158903296 ODDMA_DataID4 1;
BA_REL_ "GenSigSuprvResp" BU_SG_REL_ UPA_LS SG_ 2158903296 ODDMA_DataID4 1;
BA_REL_ "GenSigSuprvResp" BU_SG_REL_ APA_LS SG_ 2158903296 ODDMA_DataID4 1;
BA_REL_ "GenSigSuprvResp" BU_SG_REL_ EOCM2B_K2_LS SG_ 2158903296 ODDMA_DataID5Vld 1;
BA_REL_ "GenSigSuprvResp" BU_SG_REL_ EOCM2A_K2_LS SG_ 2158903296 ODDMA_DataID5Vld 1;
BA_REL_ "GenSigSuprvResp" BU_SG_REL_ EOCM_F_LS SG_ 2158903296 ODDMA_DataID5Vld 1;
BA_REL_ "GenSigSuprvResp" BU_SG_REL_ EOCM_F_LS SG_ 2158903296 ODDMA_DataID5Vld 1;
BA_REL_ "GenSigSuprvResp" BU_SG_REL_ UPA_LS SG_ 2158903296 ODDMA_DataID5Vld 1;
BA_REL_ "GenSigSuprvResp" BU_SG_REL_ APA_LS SG_ 2158903296 ODDMA_DataID5Vld 1;
BA_REL_ "GenSigSuprvResp" BU_SG_REL_ EOCM2B_K2_LS SG_ 2158903296 ODDMA_DataID5 1;
BA_REL_ "GenSigSuprvResp" BU_SG_REL_ EOCM2A_K2_LS SG_ 2158903296 ODDMA_DataID5 1;
BA_REL_ "GenSigSuprvResp" BU_SG_REL_ EOCM_F_LS SG_ 2158903296 ODDMA_DataID5 1;
BA_REL_ "GenSigSuprvResp" BU_SG_REL_ EOCM_F_LS SG_ 2158903296 ODDMA_DataID5 1;
BA_REL_ "GenSigSuprvResp" BU_SG_REL_ UPA_LS SG_ 2158903296 ODDMA_DataID5 1;
BA_REL_ "GenSigSuprvResp" BU_SG_REL_ APA_LS SG_ 2158903296 ODDMA_DataID5 1;
BA_REL_ "GenSigSuprvResp" BU_SG_REL_ EOCM2B_K2_LS SG_ 2158911488 ODDMC_ReqType 1;
BA_REL_ "GenSigSuprvResp" BU_SG_REL_ EOCM2A_K2_LS SG_ 2158911488 ODDMC_ReqType 1;
BA_REL_ "GenSigSuprvResp" BU_SG_REL_ EOCM_F_LS SG_ 2158911488 ODDMC_ReqType 1;
BA_REL_ "GenSigSuprvResp" BU_SG_REL_ EOCM_F_LS SG_ 2158911488 ODDMC_ReqType 1;
BA_REL_ "GenSigSuprvResp" BU_SG_REL_ UPA_LS SG_ 2158911488 ODDMC_ReqType 1;
BA_REL_ "GenSigSuprvResp" BU_SG_REL_ APA_LS SG_ 2158911488 ODDMC_ReqType 1;
BA_REL_ "GenSigSuprvResp" BU_SG_REL_ EOCM2B_K2_LS SG_ 2158911488 ODDMC_DispMID 1;
BA_REL_ "GenSigSuprvResp" BU_SG_REL_ EOCM2A_K2_LS SG_ 2158911488 ODDMC_DispMID 1;
BA_REL_ "GenSigSuprvResp" BU_SG_REL_ EOCM_F_LS SG_ 2158911488 ODDMC_DispMID 1;
BA_REL_ "GenSigSuprvResp" BU_SG_REL_ EOCM_F_LS SG_ 2158911488 ODDMC_DispMID 1;
BA_REL_ "GenSigSuprvResp" BU_SG_REL_ UPA_LS SG_ 2158911488 ODDMC_DispMID 1;
BA_REL_ "GenSigSuprvResp" BU_SG_REL_ APA_LS SG_ 2158911488 ODDMC_DispMID 1;
BA_REL_ "GenSigSuprvResp" BU_SG_REL_ EOCM2B_K2_LS SG_ 2158911488 ODDMC_DataID2Vld 1;
BA_REL_ "GenSigSuprvResp" BU_SG_REL_ EOCM2A_K2_LS SG_ 2158911488 ODDMC_DataID2Vld 1;
BA_REL_ "GenSigSuprvResp" BU_SG_REL_ EOCM_F_LS SG_ 2158911488 ODDMC_DataID2Vld 1;
BA_REL_ "GenSigSuprvResp" BU_SG_REL_ EOCM_F_LS SG_ 2158911488 ODDMC_DataID2Vld 1;
BA_REL_ "GenSigSuprvResp" BU_SG_REL_ UPA_LS SG_ 2158911488 ODDMC_DataID2Vld 1;
BA_REL_ "GenSigSuprvResp" BU_SG_REL_ APA_LS SG_ 2158911488 ODDMC_DataID2Vld 1;
BA_REL_ "GenSigSuprvResp" BU_SG_REL_ EOCM2B_K2_LS SG_ 2158911488 ODDMC_DataID2 1;
BA_REL_ "GenSigSuprvResp" BU_SG_REL_ EOCM2A_K2_LS SG_ 2158911488 ODDMC_DataID2 1;
BA_REL_ "GenSigSuprvResp" BU_SG_REL_ EOCM_F_LS SG_ 2158911488 ODDMC_DataID2 1;
BA_REL_ "GenSigSuprvResp" BU_SG_REL_ EOCM_F_LS SG_ 2158911488 ODDMC_DataID2 1;
BA_REL_ "GenSigSuprvResp" BU_SG_REL_ UPA_LS SG_ 2158911488 ODDMC_DataID2 1;
BA_REL_ "GenSigSuprvResp" BU_SG_REL_ APA_LS SG_ 2158911488 ODDMC_DataID2 1;
BA_REL_ "GenSigSuprvResp" BU_SG_REL_ EOCM2B_K2_LS SG_ 2158911488 ODDMC_DataID3Vld 1;
BA_REL_ "GenSigSuprvResp" BU_SG_REL_ EOCM2A_K2_LS SG_ 2158911488 ODDMC_DataID3Vld 1;
BA_REL_ "GenSigSuprvResp" BU_SG_REL_ EOCM_F_LS SG_ 2158911488 ODDMC_DataID3Vld 1;
BA_REL_ "GenSigSuprvResp" BU_SG_REL_ EOCM_F_LS SG_ 2158911488 ODDMC_DataID3Vld 1;
BA_REL_ "GenSigSuprvResp" BU_SG_REL_ UPA_LS SG_ 2158911488 ODDMC_DataID3Vld 1;
BA_REL_ "GenSigSuprvResp" BU_SG_REL_ APA_LS SG_ 2158911488 ODDMC_DataID3Vld 1;
BA_REL_ "GenSigSuprvResp" BU_SG_REL_ EOCM2B_K2_LS SG_ 2158911488 ODDMC_DataID3 1;
BA_REL_ "GenSigSuprvResp" BU_SG_REL_ EOCM2A_K2_LS SG_ 2158911488 ODDMC_DataID3 1;
BA_REL_ "GenSigSuprvResp" BU_SG_REL_ EOCM2A_K2_LS SG_ 2158911488 ODDMC_DataID3 1;
BA_REL_ "GenSigSuprvResp" BU_SG_REL_ EOCM_F_LS SG_ 2158911488 ODDMC_DataID3 1;
BA_REL_ "GenSigSuprvResp" BU_SG_REL_ EOCM_F_LS SG_ 2158911488 ODDMC_DataID3 1;
BA_REL_ "GenSigSuprvResp" BU_SG_REL_ UPA_LS SG_ 2158911488 ODDMC_DataID3 1;
BA_REL_ "GenSigSuprvResp" BU_SG_REL_ APA_LS SG_ 2158911488 ODDMC_DataID3 1;
BA_REL_ "GenSigSuprvResp" BU_SG_REL_ EOCM2B_K2_LS SG_ 2158911488 ODDMC_DataID1 1;
BA_REL_ "GenSigSuprvResp" BU_SG_REL_ EOCM2A_K2_LS SG_ 2158911488 ODDMC_DataID1 1;
BA_REL_ "GenSigSuprvResp" BU_SG_REL_ EOCM_F_LS SG_ 2158911488 ODDMC_DataID1 1;
BA_REL_ "GenSigSuprvResp" BU_SG_REL_ EOCM_F_LS SG_ 2158911488 ODDMC_DataID1 1;
BA_REL_ "GenSigSuprvResp" BU_SG_REL_ UPA_LS SG_ 2158911488 ODDMC_DataID1 1;
BA_REL_ "GenSigSuprvResp" BU_SG_REL_ APA_LS SG_ 2158911488 ODDMC_DataID1 1;
BA_REL_ "GenSigSuprvResp" BU_SG_REL_ EOCM2B_K2_LS SG_ 2158911488 ODDMC_DataID4Vld 1;
BA_REL_ "GenSigSuprvResp" BU_SG_REL_ EOCM2A_K2_LS SG_ 2158911488 ODDMC_DataID4Vld 1;
BA_REL_ "GenSigSuprvResp" BU_SG_REL_ EOCM_F_LS SG_ 2158911488 ODDMC_DataID4Vld 1;
BA_REL_ "GenSigSuprvResp" BU_SG_REL_ EOCM_F_LS SG_ 2158911488 ODDMC_DataID4Vld 1;
BA_REL_ "GenSigSuprvResp" BU_SG_REL_ UPA_LS SG_ 2158911488 ODDMC_DataID4Vld 1;
BA_REL_ "GenSigSuprvResp" BU_SG_REL_ APA_LS SG_ 2158911488 ODDMC_DataID4Vld 1;
BA_REL_ "GenSigSuprvResp" BU_SG_REL_ EOCM2B_K2_LS SG_ 2158911488 ODDMC_DataID4 1;
BA_REL_ "GenSigSuprvResp" BU_SG_REL_ EOCM2A_K2_LS SG_ 2158911488 ODDMC_DataID4 1;
BA_REL_ "GenSigSuprvResp" BU_SG_REL_ EOCM_F_LS SG_ 2158911488 ODDMC_DataID4 1;
BA_REL_ "GenSigSuprvResp" BU_SG_REL_ EOCM_F_LS SG_ 2158911488 ODDMC_DataID4 1;
BA_REL_ "GenSigSuprvResp" BU_SG_REL_ UPA_LS SG_ 2158911488 ODDMC_DataID4 1;
BA_REL_ "GenSigSuprvResp" BU_SG_REL_ APA_LS SG_ 2158911488 ODDMC_DataID4 1;
BA_REL_ "GenSigSuprvResp" BU_SG_REL_ EOCM2B_K2_LS SG_ 2158911488 ODDMC_DataID5Vld 1;
BA_REL_ "GenSigSuprvResp" BU_SG_REL_ EOCM2A_K2_LS SG_ 2158911488 ODDMC_DataID5Vld 1;
BA_REL_ "GenSigSuprvResp" BU_SG_REL_ EOCM_F_LS SG_ 2158911488 ODDMC_DataID5Vld 1;
BA_REL_ "GenSigSuprvResp" BU_SG_REL_ EOCM_F_LS SG_ 2158911488 ODDMC_DataID5Vld 1;
BA_REL_ "GenSigSuprvResp" BU_SG_REL_ UPA_LS SG_ 2158911488 ODDMC_DataID5Vld 1;
BA_REL_ "GenSigSuprvResp" BU_SG_REL_ APA_LS SG_ 2158911488 ODDMC_DataID5Vld 1;
BA_REL_ "GenSigSuprvResp" BU_SG_REL_ EOCM2B_K2_LS SG_ 2158911488 ODDMC_DataID5 1;
BA_REL_ "GenSigSuprvResp" BU_SG_REL_ EOCM2A_K2_LS SG_ 2158911488 ODDMC_DataID5 1;
BA_REL_ "GenSigSuprvResp" BU_SG_REL_ EOCM_F_LS SG_ 2158911488 ODDMC_DataID5 1;
BA_REL_ "GenSigSuprvResp" BU_SG_REL_ EOCM_F_LS SG_ 2158911488 ODDMC_DataID5 1;
BA_REL_ "GenSigSuprvResp" BU_SG_REL_ UPA_LS SG_ 2158911488 ODDMC_DataID5 1;
BA_REL_ "GenSigSuprvResp" BU_SG_REL_ APA_LS SG_ 2158911488 ODDMC_DataID5 1;
BA_REL_ "GenSigSuprvResp" BU_SG_REL_ EOCM2B_K2_LS SG_ 2158911488 ODDMC_FUCID 1;
BA_REL_ "GenSigSuprvResp" BU_SG_REL_ EOCM2A_K2_LS SG_ 2158911488 ODDMC_FUCID 1;
BA_REL_ "GenSigSuprvResp" BU_SG_REL_ EOCM_F_LS SG_ 2158911488 ODDMC_FUCID 1;
BA_REL_ "GenSigSuprvResp" BU_SG_REL_ EOCM_F_LS SG_ 2158911488 ODDMC_FUCID 1;
BA_REL_ "GenSigSuprvResp" BU_SG_REL_ UPA_LS SG_ 2158911488 ODDMC_FUCID 1;
BA_REL_ "GenSigSuprvResp" BU_SG_REL_ APA_LS SG_ 2158911488 ODDMC_FUCID 1;
BA_REL_ "GenSigSuprvResp" BU_SG_REL_ EOCM2B_K2_LS SG_ 2158919680 ODDMI_ReqType 1;
BA_REL_ "GenSigSuprvResp" BU_SG_REL_ EOCM2A_K2_LS SG_ 2158919680 ODDMI_ReqType 1;
BA_REL_ "GenSigSuprvResp" BU_SG_REL_ EOCM_F_LS SG_ 2158919680 ODDMI_ReqType 1;
BA_REL_ "GenSigSuprvResp" BU_SG_REL_ EOCM_F_LS SG_ 2158919680 ODDMI_ReqType 1;
BA_REL_ "GenSigSuprvResp" BU_SG_REL_ UPA_LS SG_ 2158919680 ODDMI_ReqType 1;
BA_REL_ "GenSigSuprvResp" BU_SG_REL_ APA_LS SG_ 2158919680 ODDMI_ReqType 1;
BA_REL_ "GenSigSuprvResp" BU_SG_REL_ EOCM2B_K2_LS SG_ 2158919680 ODDMI_FUCID 1;
BA_REL_ "GenSigSuprvResp" BU_SG_REL_ EOCM2A_K2_LS SG_ 2158919680 ODDMI_FUCID 1;
BA_REL_ "GenSigSuprvResp" BU_SG_REL_ EOCM_F_LS SG_ 2158919680 ODDMI_FUCID 1;
BA_REL_ "GenSigSuprvResp" BU_SG_REL_ EOCM_F_LS SG_ 2158919680 ODDMI_FUCID 1;
BA_REL_ "GenSigSuprvResp" BU_SG_REL_ UPA_LS SG_ 2158919680 ODDMI_FUCID 1;
BA_REL_ "GenSigSuprvResp" BU_SG_REL_ APA_LS SG_ 2158919680 ODDMI_FUCID 1;
BA_REL_ "GenSigSuprvResp" BU_SG_REL_ EOCM2B_K2_LS SG_ 2158919680 ODDMI_DispMID 1;
BA_REL_ "GenSigSuprvResp" BU_SG_REL_ EOCM2A_K2_LS SG_ 2158919680 ODDMI_DispMID 1;
BA_REL_ "GenSigSuprvResp" BU_SG_REL_ EOCM_F_LS SG_ 2158919680 ODDMI_DispMID 1;
BA_REL_ "GenSigSuprvResp" BU_SG_REL_ EOCM_F_LS SG_ 2158919680 ODDMI_DispMID 1;
BA_REL_ "GenSigSuprvResp" BU_SG_REL_ UPA_LS SG_ 2158919680 ODDMI_DispMID 1;
BA_REL_ "GenSigSuprvResp" BU_SG_REL_ APA_LS SG_ 2158919680 ODDMI_DispMID 1;
BA_REL_ "GenSigSuprvResp" BU_SG_REL_ EOCM2B_K2_LS SG_ 2158919680 ODDMI_DataID2Vld 1;
BA_REL_ "GenSigSuprvResp" BU_SG_REL_ EOCM2A_K2_LS SG_ 2158919680 ODDMI_DataID2Vld 1;
BA_REL_ "GenSigSuprvResp" BU_SG_REL_ EOCM_F_LS SG_ 2158919680 ODDMI_DataID2Vld 1;
BA_REL_ "GenSigSuprvResp" BU_SG_REL_ EOCM_F_LS SG_ 2158919680 ODDMI_DataID2Vld 1;
BA_REL_ "GenSigSuprvResp" BU_SG_REL_ UPA_LS SG_ 2158919680 ODDMI_DataID2Vld 1;
BA_REL_ "GenSigSuprvResp" BU_SG_REL_ APA_LS SG_ 2158919680 ODDMI_DataID2Vld 1;
BA_REL_ "GenSigSuprvResp" BU_SG_REL_ EOCM2B_K2_LS SG_ 2158919680 ODDMI_DataID2 1;
BA_REL_ "GenSigSuprvResp" BU_SG_REL_ EOCM2A_K2_LS SG_ 2158919680 ODDMI_DataID2 1;
BA_REL_ "GenSigSuprvResp" BU_SG_REL_ EOCM_F_LS SG_ 2158919680 ODDMI_DataID2 1;
BA_REL_ "GenSigSuprvResp" BU_SG_REL_ EOCM_F_LS SG_ 2158919680 ODDMI_DataID2 1;
BA_REL_ "GenSigSuprvResp" BU_SG_REL_ UPA_LS SG_ 2158919680 ODDMI_DataID2 1;
BA_REL_ "GenSigSuprvResp" BU_SG_REL_ APA_LS SG_ 2158919680 ODDMI_DataID2 1;
BA_REL_ "GenSigSuprvResp" BU_SG_REL_ EOCM2B_K2_LS SG_ 2158919680 ODDMI_DataID3Vld 1;
BA_REL_ "GenSigSuprvResp" BU_SG_REL_ EOCM2A_K2_LS SG_ 2158919680 ODDMI_DataID3Vld 1;
BA_REL_ "GenSigSuprvResp" BU_SG_REL_ EOCM_F_LS SG_ 2158919680 ODDMI_DataID3Vld 1;
BA_REL_ "GenSigSuprvResp" BU_SG_REL_ EOCM_F_LS SG_ 2158919680 ODDMI_DataID3Vld 1;
BA_REL_ "GenSigSuprvResp" BU_SG_REL_ UPA_LS SG_ 2158919680 ODDMI_DataID3Vld 1;
BA_REL_ "GenSigSuprvResp" BU_SG_REL_ APA_LS SG_ 2158919680 ODDMI_DataID3Vld 1;
BA_REL_ "GenSigSuprvResp" BU_SG_REL_ EOCM2B_K2_LS SG_ 2158919680 ODDMI_DataID3 1;
BA_REL_ "GenSigSuprvResp" BU_SG_REL_ EOCM2A_K2_LS SG_ 2158919680 ODDMI_DataID3 1;
BA_REL_ "GenSigSuprvResp" BU_SG_REL_ EOCM_F_LS SG_ 2158919680 ODDMI_DataID3 1;
BA_REL_ "GenSigSuprvResp" BU_SG_REL_ EOCM_F_LS SG_ 2158919680 ODDMI_DataID3 1;
BA_REL_ "GenSigSuprvResp" BU_SG_REL_ UPA_LS SG_ 2158919680 ODDMI_DataID3 1;
BA_REL_ "GenSigSuprvResp" BU_SG_REL_ APA_LS SG_ 2158919680 ODDMI_DataID3 1;
BA_REL_ "GenSigSuprvResp" BU_SG_REL_ EOCM2B_K2_LS SG_ 2158919680 ODDMI_DataID1 1;
BA_REL_ "GenSigSuprvResp" BU_SG_REL_ EOCM2A_K2_LS SG_ 2158919680 ODDMI_DataID1 1;
BA_REL_ "GenSigSuprvResp" BU_SG_REL_ EOCM_F_LS SG_ 2158919680 ODDMI_DataID1 1;
BA_REL_ "GenSigSuprvResp" BU_SG_REL_ EOCM_F_LS SG_ 2158919680 ODDMI_DataID1 1;
BA_REL_ "GenSigSuprvResp" BU_SG_REL_ UPA_LS SG_ 2158919680 ODDMI_DataID1 1;
BA_REL_ "GenSigSuprvResp" BU_SG_REL_ APA_LS SG_ 2158919680 ODDMI_DataID1 1;
BA_REL_ "GenSigSuprvResp" BU_SG_REL_ EOCM2B_K2_LS SG_ 2158919680 ODDMI_DataID4Vld 1;
BA_REL_ "GenSigSuprvResp" BU_SG_REL_ EOCM2A_K2_LS SG_ 2158919680 ODDMI_DataID4Vld 1;
BA_REL_ "GenSigSuprvResp" BU_SG_REL_ EOCM_F_LS SG_ 2158919680 ODDMI_DataID4Vld 1;
BA_REL_ "GenSigSuprvResp" BU_SG_REL_ EOCM_F_LS SG_ 2158919680 ODDMI_DataID4Vld 1;
BA_REL_ "GenSigSuprvResp" BU_SG_REL_ UPA_LS SG_ 2158919680 ODDMI_DataID4Vld 1;
BA_REL_ "GenSigSuprvResp" BU_SG_REL_ APA_LS SG_ 2158919680 ODDMI_DataID4Vld 1;
BA_REL_ "GenSigSuprvResp" BU_SG_REL_ EOCM2B_K2_LS SG_ 2158919680 ODDMI_DataID4 1;
BA_REL_ "GenSigSuprvResp" BU_SG_REL_ EOCM2A_K2_LS SG_ 2158919680 ODDMI_DataID4 1;
BA_REL_ "GenSigSuprvResp" BU_SG_REL_ EOCM_F_LS SG_ 2158919680 ODDMI_DataID4 1;
BA_REL_ "GenSigSuprvResp" BU_SG_REL_ EOCM_F_LS SG_ 2158919680 ODDMI_DataID4 1;
BA_REL_ "GenSigSuprvResp" BU_SG_REL_ UPA_LS SG_ 2158919680 ODDMI_DataID4 1;
BA_REL_ "GenSigSuprvResp" BU_SG_REL_ APA_LS SG_ 2158919680 ODDMI_DataID4 1;
BA_REL_ "GenSigSuprvResp" BU_SG_REL_ EOCM2B_K2_LS SG_ 2158919680 ODDMI_DataID5Vld 1;
BA_REL_ "GenSigSuprvResp" BU_SG_REL_ EOCM2A_K2_LS SG_ 2158919680 ODDMI_DataID5Vld 1;
BA_REL_ "GenSigSuprvResp" BU_SG_REL_ EOCM_F_LS SG_ 2158919680 ODDMI_DataID5Vld 1;
BA_REL_ "GenSigSuprvResp" BU_SG_REL_ EOCM_F_LS SG_ 2158919680 ODDMI_DataID5Vld 1;
BA_REL_ "GenSigSuprvResp" BU_SG_REL_ UPA_LS SG_ 2158919680 ODDMI_DataID5Vld 1;
BA_REL_ "GenSigSuprvResp" BU_SG_REL_ APA_LS SG_ 2158919680 ODDMI_DataID5Vld 1;
BA_REL_ "GenSigSuprvResp" BU_SG_REL_ EOCM2B_K2_LS SG_ 2158919680 ODDMI_DataID5 1;
BA_REL_ "GenSigSuprvResp" BU_SG_REL_ EOCM2A_K2_LS SG_ 2158919680 ODDMI_DataID5 1;
BA_REL_ "GenSigSuprvResp" BU_SG_REL_ EOCM_F_LS SG_ 2158919680 ODDMI_DataID5 1;
BA_REL_ "GenSigSuprvResp" BU_SG_REL_ EOCM_F_LS SG_ 2158919680 ODDMI_DataID5 1;
BA_REL_ "GenSigSuprvResp" BU_SG_REL_ UPA_LS SG_ 2158919680 ODDMI_DataID5 1;
BA_REL_ "GenSigSuprvResp" BU_SG_REL_ APA_LS SG_ 2158919680 ODDMI_DataID5 1;
BA_REL_ "GenSigSuprvResp" BU_SG_REL_ EOCM2B_K1_LS SG_ 2151825408 OtsAirTmp 1;
BA_REL_ "GenSigSuprvResp" BU_SG_REL_ EOCM2A_K1_LS SG_ 2151825408 OtsAirTmp 1;
BA_REL_ "GenSigSuprvResp" BU_SG_REL_ EOCM2A_K2_LS SG_ 2151825408 OtsAirTmp 1;
BA_REL_ "GenSigSuprvResp" BU_SG_REL_ EOCM2B_K2_LS SG_ 2151825408 OtsAirTmp 1;
BA_REL_ "GenSigSuprvResp" BU_SG_REL_ HFP_LS SG_ 2151825408 OtsAirTmp 1;
BA_REL_ "GenSigVBitResp" BU_SG_REL_ UPA_LS SG_ 2151825408 OtsAirTmp 1;
BA_REL_ "GenSigSuprvResp" BU_SG_REL_ UPA_LS SG_ 2151825408 OtsAirTmp 1;
BA_REL_ "GenSigSuprvResp" BU_SG_REL_ ICS_LS SG_ 2151825408 OtsAirTmp 1;
BA_REL_ "GenSigVBitResp" BU_SG_REL_ APA_LS SG_ 2151825408 OtsAirTmp 1;
BA_REL_ "GenSigSuprvResp" BU_SG_REL_ APA_LS SG_ 2151825408 OtsAirTmp 1;
BA_REL_ "GenSigVBitResp" BU_SG_REL_ APA_LS SG_ 2151825408 OtsAirTmp 1;
BA_REL_ "GenSigSuprvResp" BU_SG_REL_ APA_LS SG_ 2151825408 OtsAirTmp 1;
BA_REL_ "GenSigSuprvResp" BU_SG_REL_ EOCM2B_K1_LS SG_ 2151825408 OtsAirTmpCrVal 1;
BA_REL_ "GenSigSuprvResp" BU_SG_REL_ EOCM2A_K1_LS SG_ 2151825408 OtsAirTmpCrVal 1;
BA_REL_ "GenSigSuprvResp" BU_SG_REL_ EOCM2A_K2_LS SG_ 2151825408 OtsAirTmpCrVal 1;
BA_REL_ "GenSigSuprvResp" BU_SG_REL_ EOCM2B_K2_LS SG_ 2151825408 OtsAirTmpCrVal 1;
BA_REL_ "GenSigSuprvResp" BU_SG_REL_ EOCM_F_LS SG_ 2151825408 OtsAirTmpCrVal 1;
BA_REL_ "GenSigSuprvResp" BU_SG_REL_ VIS2_LS SG_ 2151825408 OtsAirTmpCrVal 1;
BA_REL_ "GenSigSuprvResp" BU_SG_REL_ ARB_LS SG_ 2151825408 OtsAirTmpCrVal 1;
BA_REL_ "GenSigSuprvResp" BU_SG_REL_ SDM_LS SG_ 2151825408 OtsAirTmpCrVal 1;
BA_REL_ "GenSigSuprvResp" BU_SG_REL_ FCM_LS SG_ 2151825408 OtsAirTmpCrVal 1;
BA_REL_ "GenSigSuprvResp" BU_SG_REL_ RadioHead_LS SG_ 2151825408 OtsAirTmpCrVal 1;
BA_REL_ "GenSigSuprvResp" BU_SG_REL_ RadioHead_LS SG_ 2151825408 OtsAirTmpCrVal 1;
BA_REL_ "GenSigVBitResp" BU_SG_REL_ BCM_LS SG_ 2151825408 OtsAirTmpCrVal 1;
BA_REL_ "GenSigSuprvResp" BU_SG_REL_ BCM_LS SG_ 2151825408 OtsAirTmpCrVal 1;
BA_REL_ "GenSigVBitResp" BU_SG_REL_ BCM_LS SG_ 2151825408 OtsAirTmpCrVal 1;
BA_REL_ "GenSigSuprvResp" BU_SG_REL_ BCM_LS SG_ 2151825408 OtsAirTmpCrVal 1;
BA_REL_ "GenSigSuprvResp" BU_SG_REL_ UPA_LS SG_ 2151825408 OtsAirTmpCrVal 1;
BA_REL_ "GenSigSuprvResp" BU_SG_REL_ APA_LS SG_ 2151825408 OtsAirTmpCrVal 1;
BA_REL_ "GenSigSuprvResp" BU_SG_REL_ APA_LS SG_ 2151825408 OtsAirTmpCrVal 1;
BA_REL_ "GenSigSuprvResp" BU_SG_REL_ CSM_LS SG_ 2151153664 RrWndDfgOn 1;
BA_REL_ "GenSigSuprvResp" BU_SG_REL_ RadioHead_LS SG_ 2151153664 RrWndDfgOn 1;
BA_REL_ "GenSigSuprvResp" BU_SG_REL_ IPC_LS SG_ 2151153664 RrWndDfgOn 1;
BA_REL_ "GenSigSuprvResp" BU_SG_REL_ EOCM2B_K1_LS SG_ 2151170048 RrEndCrrStat 1;
BA_REL_ "GenSigSuprvResp" BU_SG_REL_ EOCM2A_K1_LS SG_ 2151170048 RrEndCrrStat 1;
BA_REL_ "GenSigSuprvResp" BU_SG_REL_ UPA_LS SG_ 2151170048 RrEndCrrStat 1;
BA_REL_ "GenSigSuprvResp" BU_SG_REL_ APA_LS SG_ 2151170048 RrEndCrrStat 1;
BA_REL_ "GenSigSuprvResp" BU_SG_REL_ EOCM2B_K1_LS SG_ 2151170048 RRPrkLmpFld 1;
BA_REL_ "GenSigSuprvResp" BU_SG_REL_ EOCM2A_K1_LS SG_ 2151170048 RRPrkLmpFld 1;
BA_REL_ "GenSigSuprvResp" BU_SG_REL_ EOCM2B_K1_LS SG_ 2151170048 RLftPrkLmpFld 1;
BA_REL_ "GenSigSuprvResp" BU_SG_REL_ EOCM2A_K1_LS SG_ 2151170048 RLftPrkLmpFld 1;
BA_REL_ "GenSigSuprvResp" BU_SG_REL_ EOCM2B_K1_LS SG_ 2151170048 DisRrPrmryLmps 1;
BA_REL_ "GenSigSuprvResp" BU_SG_REL_ EOCM2A_K1_LS SG_ 2151170048 DisRrPrmryLmps 1;
BA_REL_ "GenSigSuprvResp" BU_SG_REL_ EOCM2B_K1_LS SG_ 2151170048 TrlrTlLtFld 1;
BA_REL_ "GenSigSuprvResp" BU_SG_REL_ EOCM2A_K1_LS SG_ 2151170048 TrlrTlLtFld 1;
BA_REL_ "GenSigSuprvResp" BU_SG_REL_ EOCM2B_K1_LS SG_ 2151170048 TrlrRvsLtFld 1;
BA_REL_ "GenSigSuprvResp" BU_SG_REL_ EOCM2A_K1_LS SG_ 2151170048 TrlrRvsLtFld 1;
BA_REL_ "GenSigSuprvResp" BU_SG_REL_ EOCM2B_K1_LS SG_ 2151170048 TrlrFgLtFld 1;
BA_REL_ "GenSigSuprvResp" BU_SG_REL_ EOCM2A_K1_LS SG_ 2151170048 TrlrFgLtFld 1;
BA_REL_ "GenSigSuprvResp" BU_SG_REL_ EOCM2B_K1_LS SG_ 2151170048 TrlrBrkLtFld 1;
BA_REL_ "GenSigSuprvResp" BU_SG_REL_ EOCM2A_K1_LS SG_ 2151170048 TrlrBrkLtFld 1;
BA_REL_ "GenSigSuprvResp" BU_SG_REL_ EOCM2B_K1_LS SG_ 2151170048 TrlrRtTrInLtFld 1;
BA_REL_ "GenSigSuprvResp" BU_SG_REL_ EOCM2A_K1_LS SG_ 2151170048 TrlrRtTrInLtFld 1;
BA_REL_ "GenSigSuprvResp" BU_SG_REL_ EOCM2B_K1_LS SG_ 2151170048 TrlLfTrInLtFld 1;
BA_REL_ "GenSigSuprvResp" BU_SG_REL_ EOCM2A_K1_LS SG_ 2151170048 TrlLfTrInLtFld 1;
BA_REL_ "GenSigSuprvResp" BU_SG_REL_ VIS2_LS SG_ 2151170048 TrlrHtchSwAtv 1;
BA_REL_ "GenSigSuprvResp" BU_SG_REL_ EOCM2B_K1_LS SG_ 2151170048 TrlrHtchSwAtv 1;
BA_REL_ "GenSigSuprvResp" BU_SG_REL_ EOCM2A_K1_LS SG_ 2151170048 TrlrHtchSwAtv 1;
BA_REL_ "GenSigSuprvResp" BU_SG_REL_ FCM_LS SG_ 2151170048 TrlrHtchSwAtv 1;
BA_REL_ "GenSigSuprvResp" BU_SG_REL_ EOCM_F_LS SG_ 2151170048 TrlrHtchSwAtv 1;
BA_REL_ "GenSigSuprvResp" BU_SG_REL_ EOCM_F_LS SG_ 2151170048 TrlrHtchSwAtv 1;
BA_REL_ "GenSigSuprvResp" BU_SG_REL_ UPA_LS SG_ 2151170048 TrlrHtchSwAtv 1;
BA_REL_ "GenSigSuprvResp" BU_SG_REL_ APA_LS SG_ 2151170048 TrlrHtchSwAtv 1;
BA_REL_ "GenSigSuprvResp" BU_SG_REL_ APA_LS SG_ 2151170048 TrlrHtchSwAtv 1;
BA_REL_ "GenSigSuprvResp" BU_SG_REL_ BCM_LS SG_ 2151170048 TrlrHtchSwAtv 1;
BA_REL_ "GenSigSuprvResp" BU_SG_REL_ EOCM2B_K1_LS SG_ 2151170048 RtSecTrnIndFld 1;
BA_REL_ "GenSigSuprvResp" BU_SG_REL_ EOCM2A_K1_LS SG_ 2151170048 RtSecTrnIndFld 1;
BA_REL_ "GenSigSuprvResp" BU_SG_REL_ EOCM2B_K1_LS SG_ 2151170048 TrlrFgLtPrs 1;
BA_REL_ "GenSigSuprvResp" BU_SG_REL_ EOCM2A_K1_LS SG_ 2151170048 TrlrFgLtPrs 1;
BA_REL_ "GenSigSuprvResp" BU_SG_REL_ EOCM2B_K1_LS SG_ 2151170048 LftSecTrnIndFld 1;
BA_REL_ "GenSigSuprvResp" BU_SG_REL_ EOCM2A_K1_LS SG_ 2151170048 LftSecTrnIndFld 1;
BA_REL_ "GenSigSuprvResp" BU_SG_REL_ EOCM2B_K2_LS SG_ 2151841792 WSWprAct 1;
BA_REL_ "GenSigSuprvResp" BU_SG_REL_ EOCM2A_K2_LS SG_ 2151841792 WSWprAct 1;
BA_REL_ "GenSigSuprvResp" BU_SG_REL_ V2V_LS SG_ 2151841792 WSWprAct 1;
BA_REL_ "GenSigSuprvResp" BU_SG_REL_ EOCM2B_K2_LS SG_ 2151841792 RnSnsOffIO 1;
BA_REL_ "GenSigSuprvResp" BU_SG_REL_ EOCM2A_K2_LS SG_ 2151841792 RnSnsOffIO 1;
BA_REL_ "GenSigSuprvResp" BU_SG_REL_ EOCM2B_K2_LS SG_ 2151841792 RnSnsActIO 1;
BA_REL_ "GenSigSuprvResp" BU_SG_REL_ EOCM2A_K2_LS SG_ 2151841792 RnSnsActIO 1;
BA_REL_ "GenSigSuprvResp" BU_SG_REL_ EOCM2B_K2_LS SG_ 2151841792 TurnWprIntIO 1;
BA_REL_ "GenSigSuprvResp" BU_SG_REL_ EOCM2A_K2_LS SG_ 2151841792 TurnWprIntIO 1;
BA_REL_ "GenSigTimeoutMsg" BU_SG_REL_ CSM_LS SG_ 2154094592 IntDimSeldClrTypStVal 807;
BA_REL_ "GenSigTimeoutMsg" BU_SG_REL_ RadioHead_LS SG_ 2154094592 IntDimSeldClrTypStVal 807;
BA_REL_ "GenSigTimeoutMsg" BU_SG_REL_ CSM_LS SG_ 2154094592 IntDimSeldAnmTypStVal 807;
BA_REL_ "GenSigTimeoutMsg" BU_SG_REL_ RadioHead_LS SG_ 2154094592 IntDimSeldAnmTypStVal 807;
BA_REL_ "GenSigTimeoutMsg" BU_SG_REL_ CSM_LS SG_ 2154094592 IDCTA_ClrTyp30Avl 807;
BA_REL_ "GenSigTimeoutMsg" BU_SG_REL_ RadioHead_LS SG_ 2154094592 IDCTA_ClrTyp30Avl 807;
BA_REL_ "GenSigTimeoutMsg" BU_SG_REL_ CSM_LS SG_ 2154094592 IDCTA_ClrTyp29Avl 807;
BA_REL_ "GenSigTimeoutMsg" BU_SG_REL_ RadioHead_LS SG_ 2154094592 IDCTA_ClrTyp29Avl 807;
BA_REL_ "GenSigTimeoutMsg" BU_SG_REL_ CSM_LS SG_ 2154094592 IDCTA_ClrTyp28Avl 807;
BA_REL_ "GenSigTimeoutMsg" BU_SG_REL_ RadioHead_LS SG_ 2154094592 IDCTA_ClrTyp28Avl 807;
BA_REL_ "GenSigTimeoutMsg" BU_SG_REL_ CSM_LS SG_ 2154094592 IDCTA_ClrTyp27Avl 807;
BA_REL_ "GenSigTimeoutMsg" BU_SG_REL_ RadioHead_LS SG_ 2154094592 IDCTA_ClrTyp27Avl 807;
BA_REL_ "GenSigTimeoutMsg" BU_SG_REL_ CSM_LS SG_ 2154094592 IDCTA_ClrTyp26Avl 807;
BA_REL_ "GenSigTimeoutMsg" BU_SG_REL_ RadioHead_LS SG_ 2154094592 IDCTA_ClrTyp26Avl 807;
BA_REL_ "GenSigTimeoutMsg" BU_SG_REL_ CSM_LS SG_ 2154094592 IDCTA_ClrTyp25Avl 807;
BA_REL_ "GenSigTimeoutMsg" BU_SG_REL_ RadioHead_LS SG_ 2154094592 IDCTA_ClrTyp25Avl 807;
BA_REL_ "GenSigTimeoutMsg" BU_SG_REL_ CSM_LS SG_ 2154094592 IDCTA_ClrTyp24Avl 807;
BA_REL_ "GenSigTimeoutMsg" BU_SG_REL_ RadioHead_LS SG_ 2154094592 IDCTA_ClrTyp24Avl 807;
BA_REL_ "GenSigTimeoutMsg" BU_SG_REL_ CSM_LS SG_ 2154094592 IDCTA_ClrTyp23Avl 807;
BA_REL_ "GenSigTimeoutMsg" BU_SG_REL_ RadioHead_LS SG_ 2154094592 IDCTA_ClrTyp23Avl 807;
BA_REL_ "GenSigTimeoutMsg" BU_SG_REL_ CSM_LS SG_ 2154094592 IDCTA_ClrTyp22Avl 807;
BA_REL_ "GenSigTimeoutMsg" BU_SG_REL_ RadioHead_LS SG_ 2154094592 IDCTA_ClrTyp22Avl 807;
BA_REL_ "GenSigTimeoutMsg" BU_SG_REL_ CSM_LS SG_ 2154094592 IDCTA_ClrTyp21Avl 807;
BA_REL_ "GenSigTimeoutMsg" BU_SG_REL_ RadioHead_LS SG_ 2154094592 IDCTA_ClrTyp21Avl 807;
BA_REL_ "GenSigTimeoutMsg" BU_SG_REL_ CSM_LS SG_ 2154094592 IDCTA_ClrTyp20Avl 807;
BA_REL_ "GenSigTimeoutMsg" BU_SG_REL_ RadioHead_LS SG_ 2154094592 IDCTA_ClrTyp20Avl 807;
BA_REL_ "GenSigTimeoutMsg" BU_SG_REL_ CSM_LS SG_ 2154094592 IDCTA_ClrTyp19Avl 807;
BA_REL_ "GenSigTimeoutMsg" BU_SG_REL_ RadioHead_LS SG_ 2154094592 IDCTA_ClrTyp19Avl 807;
BA_REL_ "GenSigTimeoutMsg" BU_SG_REL_ CSM_LS SG_ 2154094592 IDCTA_ClrTyp18Avl 807;
BA_REL_ "GenSigTimeoutMsg" BU_SG_REL_ RadioHead_LS SG_ 2154094592 IDCTA_ClrTyp18Avl 807;
BA_REL_ "GenSigTimeoutMsg" BU_SG_REL_ CSM_LS SG_ 2154094592 IDCTA_ClrTyp17Avl 807;
BA_REL_ "GenSigTimeoutMsg" BU_SG_REL_ RadioHead_LS SG_ 2154094592 IDCTA_ClrTyp17Avl 807;
BA_REL_ "GenSigTimeoutMsg" BU_SG_REL_ CSM_LS SG_ 2154094592 IDCTA_ClrTyp16Avl 807;
BA_REL_ "GenSigTimeoutMsg" BU_SG_REL_ RadioHead_LS SG_ 2154094592 IDCTA_ClrTyp16Avl 807;
BA_REL_ "GenSigTimeoutMsg" BU_SG_REL_ CSM_LS SG_ 2154094592 IDCTA_ClrTyp15Avl 807;
BA_REL_ "GenSigTimeoutMsg" BU_SG_REL_ RadioHead_LS SG_ 2154094592 IDCTA_ClrTyp15Avl 807;
BA_REL_ "GenSigTimeoutMsg" BU_SG_REL_ CSM_LS SG_ 2154094592 IDCTA_ClrTyp14Avl 807;
BA_REL_ "GenSigTimeoutMsg" BU_SG_REL_ RadioHead_LS SG_ 2154094592 IDCTA_ClrTyp14Avl 807;
BA_REL_ "GenSigTimeoutMsg" BU_SG_REL_ CSM_LS SG_ 2154094592 IDCTA_ClrTyp13Avl 807;
BA_REL_ "GenSigTimeoutMsg" BU_SG_REL_ RadioHead_LS SG_ 2154094592 IDCTA_ClrTyp13Avl 807;
BA_REL_ "GenSigTimeoutMsg" BU_SG_REL_ CSM_LS SG_ 2154094592 IDCTA_ClrTyp12Avl 807;
BA_REL_ "GenSigTimeoutMsg" BU_SG_REL_ RadioHead_LS SG_ 2154094592 IDCTA_ClrTyp12Avl 807;
BA_REL_ "GenSigTimeoutMsg" BU_SG_REL_ CSM_LS SG_ 2154094592 IDCTA_ClrTyp11Avl 807;
BA_REL_ "GenSigTimeoutMsg" BU_SG_REL_ RadioHead_LS SG_ 2154094592 IDCTA_ClrTyp11Avl 807;
BA_REL_ "GenSigTimeoutMsg" BU_SG_REL_ CSM_LS SG_ 2154094592 IDCTA_ClrTyp10Avl 807;
BA_REL_ "GenSigTimeoutMsg" BU_SG_REL_ RadioHead_LS SG_ 2154094592 IDCTA_ClrTyp10Avl 807;
BA_REL_ "GenSigTimeoutMsg" BU_SG_REL_ CSM_LS SG_ 2154094592 IDCTA_ClrTyp9Avl 807;
BA_REL_ "GenSigTimeoutMsg" BU_SG_REL_ RadioHead_LS SG_ 2154094592 IDCTA_ClrTyp9Avl 807;
BA_REL_ "GenSigTimeoutMsg" BU_SG_REL_ CSM_LS SG_ 2154094592 IDCTA_ClrTyp8Avl 807;
BA_REL_ "GenSigTimeoutMsg" BU_SG_REL_ RadioHead_LS SG_ 2154094592 IDCTA_ClrTyp8Avl 807;
BA_REL_ "GenSigTimeoutMsg" BU_SG_REL_ CSM_LS SG_ 2154094592 IDCTA_ClrTyp7Avl 807;
BA_REL_ "GenSigTimeoutMsg" BU_SG_REL_ RadioHead_LS SG_ 2154094592 IDCTA_ClrTyp7Avl 807;
BA_REL_ "GenSigTimeoutMsg" BU_SG_REL_ CSM_LS SG_ 2154094592 IDCTA_ClrTyp6Avl 807;
BA_REL_ "GenSigTimeoutMsg" BU_SG_REL_ RadioHead_LS SG_ 2154094592 IDCTA_ClrTyp6Avl 807;
BA_REL_ "GenSigTimeoutMsg" BU_SG_REL_ CSM_LS SG_ 2154094592 IDCTA_ClrTyp5Avl 807;
BA_REL_ "GenSigTimeoutMsg" BU_SG_REL_ RadioHead_LS SG_ 2154094592 IDCTA_ClrTyp5Avl 807;
BA_REL_ "GenSigTimeoutMsg" BU_SG_REL_ CSM_LS SG_ 2154094592 IDCTA_ClrTyp4Avl 807;
BA_REL_ "GenSigTimeoutMsg" BU_SG_REL_ RadioHead_LS SG_ 2154094592 IDCTA_ClrTyp4Avl 807;
BA_REL_ "GenSigTimeoutMsg" BU_SG_REL_ CSM_LS SG_ 2154094592 IDCTA_ClrTyp3Avl 807;
BA_REL_ "GenSigTimeoutMsg" BU_SG_REL_ RadioHead_LS SG_ 2154094592 IDCTA_ClrTyp3Avl 807;
BA_REL_ "GenSigTimeoutMsg" BU_SG_REL_ CSM_LS SG_ 2154094592 IDCTA_ClrTyp2Avl 807;
BA_REL_ "GenSigTimeoutMsg" BU_SG_REL_ RadioHead_LS SG_ 2154094592 IDCTA_ClrTyp2Avl 807;
BA_REL_ "GenSigTimeoutMsg" BU_SG_REL_ CSM_LS SG_ 2154094592 IDCTA_ClrTyp1Avl 807;
BA_REL_ "GenSigTimeoutMsg" BU_SG_REL_ RadioHead_LS SG_ 2154094592 IDCTA_ClrTyp1Avl 807;
BA_REL_ "GenSigTimeoutMsg" BU_SG_REL_ CSM_LS SG_ 2154094592 IDCTA_OffAvl 807;
BA_REL_ "GenSigTimeoutMsg" BU_SG_REL_ RadioHead_LS SG_ 2154094592 IDCTA_OffAvl 807;
BA_REL_ "GenSigTimeoutMsg" BU_SG_REL_ CSM_LS SG_ 2154094592 IDATA_AnmTyp14Avl 807;
BA_REL_ "GenSigTimeoutMsg" BU_SG_REL_ RadioHead_LS SG_ 2154094592 IDATA_AnmTyp14Avl 807;
BA_REL_ "GenSigTimeoutMsg" BU_SG_REL_ CSM_LS SG_ 2154094592 IDATA_AnmTyp13Avl 807;
BA_REL_ "GenSigTimeoutMsg" BU_SG_REL_ RadioHead_LS SG_ 2154094592 IDATA_AnmTyp13Avl 807;
BA_REL_ "GenSigTimeoutMsg" BU_SG_REL_ CSM_LS SG_ 2154094592 IDATA_AnmTyp12Avl 807;
BA_REL_ "GenSigTimeoutMsg" BU_SG_REL_ RadioHead_LS SG_ 2154094592 IDATA_AnmTyp12Avl 807;
BA_REL_ "GenSigTimeoutMsg" BU_SG_REL_ CSM_LS SG_ 2154094592 IDATA_AnmTyp11Avl 807;
BA_REL_ "GenSigTimeoutMsg" BU_SG_REL_ RadioHead_LS SG_ 2154094592 IDATA_AnmTyp11Avl 807;
BA_REL_ "GenSigTimeoutMsg" BU_SG_REL_ CSM_LS SG_ 2154094592 IDATA_AnmTyp10Avl 807;
BA_REL_ "GenSigTimeoutMsg" BU_SG_REL_ RadioHead_LS SG_ 2154094592 IDATA_AnmTyp10Avl 807;
BA_REL_ "GenSigTimeoutMsg" BU_SG_REL_ CSM_LS SG_ 2154094592 IDATA_AnmTyp9Avl 807;
BA_REL_ "GenSigTimeoutMsg" BU_SG_REL_ RadioHead_LS SG_ 2154094592 IDATA_AnmTyp9Avl 807;
BA_REL_ "GenSigTimeoutMsg" BU_SG_REL_ CSM_LS SG_ 2154094592 IDATA_AnmTyp8Avl 807;
BA_REL_ "GenSigTimeoutMsg" BU_SG_REL_ RadioHead_LS SG_ 2154094592 IDATA_AnmTyp8Avl 807;
BA_REL_ "GenSigTimeoutMsg" BU_SG_REL_ CSM_LS SG_ 2154094592 IDATA_AnmTyp7Avl 807;
BA_REL_ "GenSigTimeoutMsg" BU_SG_REL_ RadioHead_LS SG_ 2154094592 IDATA_AnmTyp7Avl 807;
BA_REL_ "GenSigTimeoutMsg" BU_SG_REL_ CSM_LS SG_ 2154094592 IDATA_AnmTyp6Avl 807;
BA_REL_ "GenSigTimeoutMsg" BU_SG_REL_ RadioHead_LS SG_ 2154094592 IDATA_AnmTyp6Avl 807;
BA_REL_ "GenSigTimeoutMsg" BU_SG_REL_ CSM_LS SG_ 2154094592 IDATA_AnmTyp5Avl 807;
BA_REL_ "GenSigTimeoutMsg" BU_SG_REL_ RadioHead_LS SG_ 2154094592 IDATA_AnmTyp5Avl 807;
BA_REL_ "GenSigTimeoutMsg" BU_SG_REL_ CSM_LS SG_ 2154094592 IDATA_AnmTyp4Avl 807;
BA_REL_ "GenSigTimeoutMsg" BU_SG_REL_ RadioHead_LS SG_ 2154094592 IDATA_AnmTyp4Avl 807;
BA_REL_ "GenSigTimeoutMsg" BU_SG_REL_ CSM_LS SG_ 2154094592 IDATA_AnmTyp3Avl 807;
BA_REL_ "GenSigTimeoutMsg" BU_SG_REL_ RadioHead_LS SG_ 2154094592 IDATA_AnmTyp3Avl 807;
BA_REL_ "GenSigTimeoutMsg" BU_SG_REL_ CSM_LS SG_ 2154094592 IDATA_AnmTyp2Avl 807;
BA_REL_ "GenSigTimeoutMsg" BU_SG_REL_ RadioHead_LS SG_ 2154094592 IDATA_AnmTyp2Avl 807;
BA_REL_ "GenSigTimeoutMsg" BU_SG_REL_ CSM_LS SG_ 2154094592 IDATA_AnmTyp1Avl 807;
BA_REL_ "GenSigTimeoutMsg" BU_SG_REL_ RadioHead_LS SG_ 2154094592 IDATA_AnmTyp1Avl 807;
BA_REL_ "GenSigTimeoutMsg" BU_SG_REL_ CSM_LS SG_ 2154094592 IDATA_OffAvl 807;
BA_REL_ "GenSigTimeoutMsg" BU_SG_REL_ RadioHead_LS SG_ 2154094592 IDATA_OffAvl 807;
BA_REL_ "GenSigSuprvResp" BU_SG_REL_ MSM_P_LS SG_ 2154094592 AdjPdlMotInhbtd 1;
BA_REL_ "GenSigSuprvResp" BU_SG_REL_ MSM_LS SG_ 2154094592 AdjPdlMotInhbtd 1;
BA_REL_ "GenSigSuprvResp" BU_SG_REL_ IPC_LS SG_ 2149711872 SetSpdLmtRchd 1;
BA_REL_ "GenSigSuprvResp" BU_SG_REL_ V2V_LS SG_ 2149711872 FwdClnAlrtPr 1;
BA_REL_ "GenSigVDAFailComment" BU_SG_REL_ CHUD_LS SG_ 2149711872 FwdClnAlrtPr "AdapCrsCntVDA";
BA_REL_ "GenSigVDAFailResp" BU_SG_REL_ CHUD_LS SG_ 2149711872 FwdClnAlrtPr 1;
BA_REL_ "GenSigSuprvResp" BU_SG_REL_ CHUD_LS SG_ 2149711872 FwdClnAlrtPr 1;
BA_REL_ "GenSigVDAFailComment" BU_SG_REL_ HUD_LS SG_ 2149711872 FwdClnAlrtPr "AdapCrsCntVDA";
BA_REL_ "GenSigVDAFailResp" BU_SG_REL_ HUD_LS SG_ 2149711872 FwdClnAlrtPr 1;
BA_REL_ "GenSigSuprvResp" BU_SG_REL_ HUD_LS SG_ 2149711872 FwdClnAlrtPr 1;
BA_REL_ "GenSigVDAFailComment" BU_SG_REL_ CHUD_LS SG_ 2149711872 ACCHdwyStg "AdapCrsCntVDA";
BA_REL_ "GenSigVDAFailResp" BU_SG_REL_ CHUD_LS SG_ 2149711872 ACCHdwyStg 1;
BA_REL_ "GenSigSuprvResp" BU_SG_REL_ CHUD_LS SG_ 2149711872 ACCHdwyStg 1;
BA_REL_ "GenSigVDAFailComment" BU_SG_REL_ HUD_LS SG_ 2149711872 ACCHdwyStg "AdapCrsCntVDA";
BA_REL_ "GenSigVDAFailResp" BU_SG_REL_ HUD_LS SG_ 2149711872 ACCHdwyStg 1;
BA_REL_ "GenSigSuprvResp" BU_SG_REL_ HUD_LS SG_ 2149711872 ACCHdwyStg 1;
BA_REL_ "GenSigVDAFailComment" BU_SG_REL_ CHUD_LS SG_ 2149711872 ACCDrvrSeltdSpd "AdapCrsCntVDA";
BA_REL_ "GenSigVDAFailResp" BU_SG_REL_ CHUD_LS SG_ 2149711872 ACCDrvrSeltdSpd 1;
BA_REL_ "GenSigSuprvResp" BU_SG_REL_ CHUD_LS SG_ 2149711872 ACCDrvrSeltdSpd 1;
BA_REL_ "GenSigVDAFailComment" BU_SG_REL_ HUD_LS SG_ 2149711872 ACCDrvrSeltdSpd "AdapCrsCntVDA";
BA_REL_ "GenSigVDAFailResp" BU_SG_REL_ HUD_LS SG_ 2149711872 ACCDrvrSeltdSpd 1;
BA_REL_ "GenSigSuprvResp" BU_SG_REL_ HUD_LS SG_ 2149711872 ACCDrvrSeltdSpd 1;
BA_REL_ "GenSigSuprvResp" BU_SG_REL_ FCM_LS SG_ 2149711872 AdapCrsCntVDA 1;
BA_REL_ "GenSigSuprvResp" BU_SG_REL_ VIS2_LS SG_ 2149711872 SpdLmtrSpdWrngEnbld 1;
BA_REL_ "GenSigSuprvResp" BU_SG_REL_ FCM_LS SG_ 2149711872 SpdLmtrSpdWrngEnbld 1;
BA_REL_ "GenSigSuprvResp" BU_SG_REL_ VPM_LS SG_ 2149711872 VehDynYawRate 1;
BA_REL_ "GenSigSuprvResp" BU_SG_REL_ SBZA_L_LS SG_ 2149711872 VehDynYawRate 1;
BA_REL_ "GenSigSuprvResp" BU_SG_REL_ SBZA_R_LS SG_ 2149711872 VehDynYawRate 1;
BA_REL_ "GenSigSuprvResp" BU_SG_REL_ IPC_LS SG_ 2149711872 VehDynYawRate 1;
BA_REL_ "GenSigVBitResp" BU_SG_REL_ FCM_LS SG_ 2149711872 VehDynYawRate 1;
BA_REL_ "GenSigVDAFailComment" BU_SG_REL_ FCM_LS SG_ 2149711872 VehDynYawRate "Brake System Virtual Device Availability";
BA_REL_ "GenSigVDAFailResp" BU_SG_REL_ FCM_LS SG_ 2149711872 VehDynYawRate 1;
BA_REL_ "GenSigSuprvResp" BU_SG_REL_ FCM_LS SG_ 2149711872 VehDynYawRate 1;
BA_REL_ "GenSigVBitResp" BU_SG_REL_ UPA_LS SG_ 2149711872 VehDynYawRate 1;
BA_REL_ "GenSigVDAFailComment" BU_SG_REL_ UPA_LS SG_ 2149711872 VehDynYawRate "Brake System Virtual Device Availability";
BA_REL_ "GenSigVDAFailResp" BU_SG_REL_ UPA_LS SG_ 2149711872 VehDynYawRate 1;
BA_REL_ "GenSigSuprvResp" BU_SG_REL_ UPA_LS SG_ 2149711872 VehDynYawRate 1;
BA_REL_ "GenSigVBitResp" BU_SG_REL_ APA_LS SG_ 2149711872 VehDynYawRate 1;
BA_REL_ "GenSigVDAFailComment" BU_SG_REL_ APA_LS SG_ 2149711872 VehDynYawRate "Brake System Virtual Device Availability";
BA_REL_ "GenSigVDAFailResp" BU_SG_REL_ APA_LS SG_ 2149711872 VehDynYawRate 1;
BA_REL_ "GenSigSuprvResp" BU_SG_REL_ APA_LS SG_ 2149711872 VehDynYawRate 1;
BA_REL_ "GenSigSuprvResp" BU_SG_REL_ V2V_LS SG_ 2149711872 ACCAct370 1;
BA_REL_ "GenSigSuprvResp" BU_SG_REL_ VIS2_LS SG_ 2149711872 ACCAct370 1;
BA_REL_ "GenSigSuprvResp" BU_SG_REL_ APA_LS SG_ 2149711872 ACCAct370 1;
BA_REL_ "GenSigSuprvResp" BU_SG_REL_ FCM_LS SG_ 2149711872 ACCAct370 1;
BA_REL_ "GenSigSuprvResp" BU_SG_REL_ FCM_LS SG_ 2149711872 ACCAct370 1;
BA_REL_ "GenSigVDAFailComment" BU_SG_REL_ CHUD_LS SG_ 2149711872 ACCAct370 "Adaptive Cruise Control Virtual Device Availability";
BA_REL_ "GenSigVDAFailResp" BU_SG_REL_ CHUD_LS SG_ 2149711872 ACCAct370 1;
BA_REL_ "GenSigSuprvResp" BU_SG_REL_ CHUD_LS SG_ 2149711872 ACCAct370 1;
BA_REL_ "GenSigVDAFailComment" BU_SG_REL_ HUD_LS SG_ 2149711872 ACCAct370 "Adaptive Cruise Control Virtual Device Availability";
BA_REL_ "GenSigVDAFailResp" BU_SG_REL_ HUD_LS SG_ 2149711872 ACCAct370 1;
BA_REL_ "GenSigSuprvResp" BU_SG_REL_ HUD_LS SG_ 2149711872 ACCAct370 1;
BA_REL_ "GenSigSuprvResp" BU_SG_REL_ VIS2_LS SG_ 2149711872 SpdLmtrSpdWrngAct 1;
BA_REL_ "GenSigSuprvResp" BU_SG_REL_ FCM_LS SG_ 2149711872 SpdLmtrSpdWrngAct 1;
BA_REL_ "GenSigSuprvResp" BU_SG_REL_ FCM_LS SG_ 2149711872 CrsSpdLmtrDrvSelSpd 1;
BA_REL_ "GenSigSuprvResp" BU_SG_REL_ VIS2_LS SG_ 2149711872 AutoMdSpdLmtStat 1;
BA_REL_ "GenSigSuprvResp" BU_SG_REL_ FCM_LS SG_ 2149711872 AutoMdSpdLmtStat 1;
BA_REL_ "GenSigSuprvResp" BU_SG_REL_ IPC_LS SG_ 2149711872 AutoMdSpdLmtStat 1;
BA_REL_ "GenSigSuprvResp" BU_SG_REL_ VIS2_LS SG_ 2149711872 ACCAutoSetSpdStat 1;
BA_REL_ "GenSigSuprvResp" BU_SG_REL_ IPC_LS SG_ 2149711872 ACCAutoSetSpdStat 1;
BA_REL_ "GenSigSuprvResp" BU_SG_REL_ HBSM_LS SG_ 2155003904 LfLnChngThrtAprchSpd 1;
BA_REL_ "GenSigSuprvResp" BU_SG_REL_ HBSM_LS SG_ 2155003904 LftLnChgThrt 1;
BA_REL_ "GenSigSuprvResp" BU_SG_REL_ VIS2_LS SG_ 2155003904 LftLnChgThrt 1;
BA_REL_ "GenSigSuprvResp" BU_SG_REL_ EOCM_F_LS SG_ 2155003904 LftLnChgThrt 1;
BA_REL_ "GenSigSuprvResp" BU_SG_REL_ FCM_LS SG_ 2155003904 LftLnChgThrt 1;
BA_REL_ "GenSigSuprvResp" BU_SG_REL_ CSM_LS SG_ 2150227968 PhnSpRcgnApSt 1;
BA_REL_ "GenSigSuprvResp" BU_SG_REL_ OTIM_LS SG_ 2150227968 PhnSpRcgnApSt 1;
BA_REL_ "GenSigSuprvResp" BU_SG_REL_ RadioHead_LS SG_ 2150227968 PhnSpRcgnApSt 1;
BA_REL_ "GenSigSuprvResp" BU_SG_REL_ VPM_LS SG_ 2162982912 VehIdNmDig10_17 1;
BA_REL_ "GenSigSuprvResp" BU_SG_REL_ EOCM2B_K2_LS SG_ 2162982912 VehIdNmDig10_17 1;
BA_REL_ "GenSigSuprvResp" BU_SG_REL_ EOCM2A_K2_LS SG_ 2162982912 VehIdNmDig10_17 1;
BA_REL_ "GenSigSuprvResp" BU_SG_REL_ EOCM_F_LS SG_ 2162982912 VehIdNmDig10_17 1;
BA_REL_ "GenSigSuprvResp" BU_SG_REL_ UPA_LS SG_ 2162982912 VehIdNmDig10_17 1;
BA_REL_ "GenSigSuprvResp" BU_SG_REL_ APA_LS SG_ 2162982912 VehIdNmDig10_17 1;
BA_REL_ "GenSigSuprvResp" BU_SG_REL_ APA_LS SG_ 2162982912 VehIdNmDig10_17 1;
BA_REL_ "GenSigSuprvResp" BU_SG_REL_ SDM_LS SG_ 2162982912 VehIdNmDig10_17 1;
BA_REL_ "GenSigSuprvResp" BU_SG_REL_ VPM_LS SG_ 2162966528 VehIdNmDig2_9 1;
BA_REL_ "GenSigSuprvResp" BU_SG_REL_ EOCM2B_K2_LS SG_ 2162966528 VehIdNmDig2_9 1;
BA_REL_ "GenSigSuprvResp" BU_SG_REL_ EOCM2A_K2_LS SG_ 2162966528 VehIdNmDig2_9 1;
BA_REL_ "GenSigSuprvResp" BU_SG_REL_ EOCM_F_LS SG_ 2162966528 VehIdNmDig2_9 1;
BA_REL_ "GenSigSuprvResp" BU_SG_REL_ UPA_LS SG_ 2162966528 VehIdNmDig2_9 1;
BA_REL_ "GenSigSuprvResp" BU_SG_REL_ APA_LS SG_ 2162966528 VehIdNmDig2_9 1;
BA_REL_ "GenSigSuprvResp" BU_SG_REL_ APA_LS SG_ 2162966528 VehIdNmDig2_9 1;
BA_REL_ "GenSigSuprvResp" BU_SG_REL_ SDM_LS SG_ 2162966528 VehIdNmDig2_9 1;
BA_REL_ "GenSigSuprvResp" BU_SG_REL_ VPM_LS SG_ 2151497728 TireLFPrs 1;
BA_REL_ "GenSigSuprvResp" BU_SG_REL_ TCP_LS SG_ 2151497728 TireLFPrs 1;
BA_REL_ "GenSigSuprvResp" BU_SG_REL_ V2V_LS SG_ 2151497728 TireLFPrs 1;
BA_REL_ "GenSigSuprvResp" BU_SG_REL_ ONSTAR_LS SG_ 2151497728 TireLFPrs 1;
BA_REL_ "GenSigSuprvResp" BU_SG_REL_ IPC_LS SG_ 2151497728 TireLFPrs 1;
BA_REL_ "GenSigSuprvResp" BU_SG_REL_ VPM_LS SG_ 2151497728 TireLFPrsStat 1;
BA_REL_ "GenSigSuprvResp" BU_SG_REL_ VPM_LS SG_ 2151497728 TireLRPrs 1;
BA_REL_ "GenSigSuprvResp" BU_SG_REL_ TCP_LS SG_ 2151497728 TireLRPrs 1;
BA_REL_ "GenSigSuprvResp" BU_SG_REL_ V2V_LS SG_ 2151497728 TireLRPrs 1;
BA_REL_ "GenSigSuprvResp" BU_SG_REL_ ONSTAR_LS SG_ 2151497728 TireLRPrs 1;
BA_REL_ "GenSigSuprvResp" BU_SG_REL_ IPC_LS SG_ 2151497728 TireLRPrs 1;
BA_REL_ "GenSigSuprvResp" BU_SG_REL_ VPM_LS SG_ 2151497728 TireLRPrsStat 1;
BA_REL_ "GenSigSuprvResp" BU_SG_REL_ TCP_LS SG_ 2151497728 TireRFPrs 1;
BA_REL_ "GenSigSuprvResp" BU_SG_REL_ VPM_LS SG_ 2151497728 TireRFPrs 1;
BA_REL_ "GenSigSuprvResp" BU_SG_REL_ V2V_LS SG_ 2151497728 TireRFPrs 1;
BA_REL_ "GenSigSuprvResp" BU_SG_REL_ ONSTAR_LS SG_ 2151497728 TireRFPrs 1;
BA_REL_ "GenSigSuprvResp" BU_SG_REL_ IPC_LS SG_ 2151497728 TireRFPrs 1;
BA_REL_ "GenSigSuprvResp" BU_SG_REL_ VPM_LS SG_ 2151497728 TireRFPrsStat 1;
BA_REL_ "GenSigSuprvResp" BU_SG_REL_ TCP_LS SG_ 2151497728 TireRRPrs 1;
BA_REL_ "GenSigSuprvResp" BU_SG_REL_ VPM_LS SG_ 2151497728 TireRRPrs 1;
BA_REL_ "GenSigSuprvResp" BU_SG_REL_ V2V_LS SG_ 2151497728 TireRRPrs 1;
BA_REL_ "GenSigSuprvResp" BU_SG_REL_ ONSTAR_LS SG_ 2151497728 TireRRPrs 1;
BA_REL_ "GenSigSuprvResp" BU_SG_REL_ IPC_LS SG_ 2151497728 TireRRPrs 1;
BA_REL_ "GenSigSuprvResp" BU_SG_REL_ VPM_LS SG_ 2151497728 TireRRPrsStat 1;
BA_REL_ "GenSigSuprvResp" BU_SG_REL_ TCP_LS SG_ 2151219200 RemStrtSt 1;
BA_REL_ "GenSigSuprvResp" BU_SG_REL_ MSM_P_LS SG_ 2151219200 RemStrtSt 1;
BA_REL_ "GenSigSuprvResp" BU_SG_REL_ HVSM_F_LS SG_ 2151219200 RemStrtSt 1;
BA_REL_ "GenSigSuprvResp" BU_SG_REL_ MSM_LS SG_ 2151219200 RemStrtSt 1;
BA_REL_ "GenSigSuprvResp" BU_SG_REL_ HVSM_R_LS SG_ 2151219200 RemStrtSt 1;
BA_REL_ "GenSigSuprvResp" BU_SG_REL_ RadioHead_LS SG_ 2151219200 RemStrtSt 1;
BA_REL_ "GenSigSuprvResp" BU_SG_REL_ RadioHead_LS SG_ 2151219200 RemStrtSt 1;
BA_REL_ "GenSigSuprvResp" BU_SG_REL_ ONSTAR_LS SG_ 2151219200 RemStrtSt 1;
BA_REL_ "GenSigSuprvResp" BU_SG_REL_ LCM_LS SG_ 2151219200 RemStrtSt 1;
BA_REL_ "GenSigSuprvResp" BU_SG_REL_ PTM_LS SG_ 2151219200 RemStrtSt 1;
BA_REL_ "GenSigSuprvResp" BU_SG_REL_ ECC_LS SG_ 2151219200 RemStrtSt 1;
BA_REL_ "GenSigSuprvResp" BU_SG_REL_ ECC_LS SG_ 2151219200 RemStrtSt 1;
BA_REL_ "GenSigSuprvResp" BU_SG_REL_ ECC_LS SG_ 2151219200 RemStrtSt 1;
BA_REL_ "GenSigSuprvResp" BU_SG_REL_ ECC_LS SG_ 2151219200 RemStrtSt 1;
BA_REL_ "GenSigSuprvResp" BU_SG_REL_ ECC_LS SG_ 2151219200 RemStrtSt 1;
BA_REL_ "GenSigSuprvResp" BU_SG_REL_ ECC_LS SG_ 2151219200 RemStrtSt 1;
BA_REL_ "GenSigSuprvResp" BU_SG_REL_ ECC_LS SG_ 2151219200 RemStrtSt 1;
VAL_ 2154905600 DrvSeatPrsMemID 0 "Memory #1" 1 "Memory #2" 2 "Memory #3" 3 "Memory #4" 4 "Memory #5" 5 "Memory #6" 6 "Memory #7" 7 "Unknown" ;
VAL_ 2154905600 DrId 7 "Unknown" 6 "Driver #7" 5 "Driver #6" 4 "Driver #5" 3 "Driver #4" 2 "Driver #3" 1 "Driver #2" 0 "Driver #1" ;
VAL_ 2154954752 WPwrdRmStEnbld 1 "true" 0 "false" ;
VAL_ 2154954752 HtdStWhlInd 3 "High" 2 "Medium" 1 "Low" 0 "Off" ;
VAL_ 2154954752 HtdStWhlCtrlSrc 1 "Remote Switch Control" 0 "Local Switch Control" ;
VAL_ 2154954752 HtdStWhlCmd 3 "High" 2 "Medium" 1 "Low" 0 "Off" ;
VAL_ 2154954752 ClmtHtPwrRqd 1 "true" 0 "false" ;
VAL_ 2153381888 VltActRrAccUnavlIO 1 "true" 0 "false" ;
VAL_ 2153381888 PwrLftgtMotStat 0 "Unknown" 1 "Full open" 2 "Closed" 3 "Opening" 4 "Closing" 5 "Stopped" ;
VAL_ 2153381888 GrgPrgMdCmpl 1 "true" 0 "false" ;
VAL_ 2153381888 PwrLftgtInclAngV 1 "Invalid" 0 "Valid" ;
VAL_ 2153381888 RrClsrObstclDtctd 1 "true" 0 "false" ;
VAL_ 2153381888 FnshRrClsrMtnBfrDrvIO 1 "true" 0 "false" ;
VAL_ 2153381888 RrClosOpenSwAct 1 "true" 0 "false" ;
VAL_ 2153381888 RrClosOpenSwActV 1 "Invalid" 0 "Valid" ;
VAL_ 2153381888 RrClsrInMtn 1 "true" 0 "false" ;
VAL_ 2153381888 RrWprInhbRq 1 "true" 0 "false" ;
VAL_ 2149752832 SndEnhcmtPerfMdRq 7 "Performance Mode 7" 6 "Performance Mode 6" 5 "Performance Mode 5" 4 "Performance Mode 4" 3 "Performance Mode 3" 2 "Performance Mode 2" 1 "Performance Mode 1" 0 "No Action" ;
VAL_ 2149752832 SndPerfMdCsStAvl 1 "true" 0 "false" ;
VAL_ 2149752832 SndPerfMdCsCrStVal 0 "No Action" 1 "Performance Mode 1" 2 "Performance Mode 2" 3 "Performance Mode 3" 4 "Performance Mode 4" 5 "Performance Mode 5" 6 "Performance Mode 6" 7 "Auto" ;
VAL_ 2149752832 DispPerfMdCsStAvl 1 "true" 0 "false" ;
VAL_ 2149752832 DispPerfMdCsCrStVal 0 "No Action" 1 "Performance Mode 1" 2 "Performance Mode 2" 3 "Performance Mode 3" 4 "Performance Mode 4" 5 "Performance Mode 5" 6 "Performance Mode 6" 7 "Auto" ;
VAL_ 2149752832 HlStrAssActIO 1 "true" 0 "false" ;
VAL_ 2149752832 GNCustSetngAvlbl 1 "true" 0 "false" ;
VAL_ 2149752832 GNCustCrntStngVal 0 "No Action" 1 "Off" 2 "On" ;
VAL_ 2149752832 CPSInfotmntMtReq 0 "No Mute" 1 "Unused and Reserved 1" 2 "Unused and Reserved 2" 3 "Mute" ;
VAL_ 2149752832 ColPrSysStngAvl 1 "true" 0 "false" ;
VAL_ 2149752832 ColPrSysCrntStng 4 "Alert and Brake and Steer" 0 "No Action" 1 "Off" 2 "Alert" 3 "Alert and Brake" ;
VAL_ 2149752832 HillDscntCntlSysStat 4 "Temporarily Inhibited" 3 "Failed" 2 "Active" 1 "Enabled" 0 "Normal" ;
VAL_ 2149752832 ElecPrkBrkStat 2 "Fault" 1 "Applied" 0 "Released" ;
VAL_ 2149752832 EBDFailed 1 "true" 0 "false" ;
VAL_ 2149752832 SusCustStngAvlbl 1 "true" 0 "false" ;
VAL_ 2149752832 SusCustCurrStngVal 7 "Auto" 6 "Performance Mode 6" 5 "Performance Mode 5" 4 "Performance Mode 4" 3 "Performance Mode 3" 0 "No Action" 1 "Performance Mode 1" 2 "Performance Mode 2" ;
VAL_ 2149752832 StrCustStngAvlbl 1 "true" 0 "false" ;
VAL_ 2149752832 StrCustCurrStngVal 7 "Auto" 6 "Performance Mode 6" 5 "Performance Mode 5" 4 "Performance Mode 4" 3 "Performance Mode 3" 0 "No Action" 1 "Performance Mode 1" 2 "Performance Mode 2" ;
VAL_ 2149752832 DrvlnCustStngAvlbl 1 "true" 0 "false" ;
VAL_ 2149752832 DrvlnCustCurrStngVal 7 "Auto" 6 "Performance Mode 6" 5 "Performance Mode 5" 4 "Performance Mode 4" 3 "Performance Mode 3" 0 "No Action" 1 "Performance Mode 1" 2 "Performance Mode 2" ;
VAL_ 2149752832 ABSAtv 1 "true" 0 "false" ;
VAL_ 2149752832 PowStVDA 1 "VirtualDeviceAvailable" 0 "VirtualDeviceUnavailable" ;
VAL_ 2149752832 RrDrCntVDA 1 "VirtualDeviceAvailable" 0 "VirtualDeviceUnavailable" ;
VAL_ 2149752832 SprTireSt 2 "Spare Detected" 1 "No Spare Detected" 0 "Undetermined" ;
VAL_ 2149752832 VehHghtStatV 1 "Invalid" 0 "Valid" ;
VAL_ 2149752832 VehHghtStat 4 "Maximum Height" 3 "Kneeling Height" 2 "Aerodynamic Height" 1 "Normal Design Ride Height" 0 "Unknown" ;
VAL_ 2149752832 BrkSysVDA 1 "VirtualDeviceAvailable" 0 "VirtualDeviceUnavailable" ;
VAL_ 2149752832 IntBrkAssPreFilReq 1 "true" 0 "false" ;
VAL_ 2149752832 EPBSysDspMsgReq 7 "Message #7" 6 "Message #6" 5 "Message #5" 4 "Message #4" 3 "Message #3" 2 "Message #2" 1 "Message #1" 0 "Off" ;
VAL_ 2149752832 EPBSysAudWarnReq 2 "Warning #2" 1 "Warning #1" 0 "Off" ;
VAL_ 2149752832 BksOvht 1 "true" 0 "false" ;
VAL_ 2149752832 BrkSysRedBrkTlltlReq 1 "true" 0 "false" ;
VAL_ 2149752832 HalfSysFail 1 "true" 0 "false" ;
VAL_ 2149752832 PrkBrkVDA 1 "VirtualDeviceAvailable" 0 "VirtualDeviceUnavailable" ;
VAL_ 2151514112 EngOilLfRstRq 1 "true" 0 "false" ;
VAL_ 2158903296 ODDMA_ReqType 0 "Subscribe: FU sends DynData back and then on change) " 1 "Unsubscribe: cancel previous Subscribe" ;
VAL_ 2158903296 ODDMA_DispMID 128 "Reserved" 64 "Reserved" 32 "OTIM" 16 "RearDisplayTwo" 8 "RearDisplayOne" 4 "AuxIP" 2 "CenterStack" 1 "IPC" ;
VAL_ 2158903296 ODDMA_DataID2Vld 1 "true" 0 "false" ;
VAL_ 2158903296 ODDMA_DataID3Vld 1 "true" 0 "false" ;
VAL_ 2158903296 ODDMA_DataID4Vld 1 "true" 0 "false" ;
VAL_ 2158903296 ODDMA_DataID5Vld 1 "true" 0 "false" ;
VAL_ 2158911488 ODDMC_ReqType 0 "Subscribe: FU sends DynData back and then on change) " 1 "Unsubscribe: cancel previous Subscribe" ;
VAL_ 2158911488 ODDMC_DispMID 128 "Reserved" 64 "Reserved" 32 "OTIM" 16 "RearDisplayTwo" 8 "RearDisplayOne" 4 "AuxIP" 2 "CenterStack" 1 "IPC" ;
VAL_ 2158911488 ODDMC_DataID2Vld 1 "true" 0 "false" ;
VAL_ 2158911488 ODDMC_DataID3Vld 1 "true" 0 "false" ;
VAL_ 2158911488 ODDMC_DataID4Vld 1 "true" 0 "false" ;
VAL_ 2158911488 ODDMC_DataID5Vld 1 "true" 0 "false" ;
VAL_ 2158919680 ODDMI_ReqType 0 "Subscribe: FU sends DynData back and then on change) " 1 "Unsubscribe: cancel previous Subscribe" ;
VAL_ 2158919680 ODDMI_DispMID 128 "Reserved" 64 "Reserved" 32 "OTIM" 16 "RearDisplayTwo" 8 "RearDisplayOne" 4 "AuxIP" 2 "CenterStack" 1 "IPC" ;
VAL_ 2158919680 ODDMI_DataID2Vld 1 "true" 0 "false" ;
VAL_ 2158919680 ODDMI_DataID3Vld 1 "true" 0 "false" ;
VAL_ 2158919680 ODDMI_DataID4Vld 1 "true" 0 "false" ;
VAL_ 2158919680 ODDMI_DataID5Vld 1 "true" 0 "false" ;
VAL_ 2151825408 OtsAirTmpV 1 "Invalid" 0 "Valid" ;
VAL_ 2151825408 OtsAirTmpCrValV 1 "Invalid" 0 "Valid" ;
VAL_ 2151825408 OtsAirTmpCrValMsk 0 "Don't Use Data" 1 "Use Data" ;
VAL_ 2151153664 RrWndDfgOn 1 "true" 0 "false" ;
VAL_ 2151170048 RrEndCrrStat 0 "Not Extended" 1 "Extended" ;
VAL_ 2151170048 RRPrkLmpFld 1 "true" 0 "false" ;
VAL_ 2151170048 RLftPrkLmpFld 1 "true" 0 "false" ;
VAL_ 2151170048 DisRrPrmryLmps 1 "true" 0 "false" ;
VAL_ 2151170048 TrlrTlLtFld 1 "true" 0 "false" ;
VAL_ 2151170048 TrlrRvsLtFld 1 "true" 0 "false" ;
VAL_ 2151170048 TrlrFgLtFld 1 "true" 0 "false" ;
VAL_ 2151170048 TrlrBrkLtFld 1 "true" 0 "false" ;
VAL_ 2151170048 TrlrRtTrInLtFld 1 "true" 0 "false" ;
VAL_ 2151170048 TrlLfTrInLtFld 1 "true" 0 "false" ;
VAL_ 2151170048 TrlrHtchSwAtv 1 "true" 0 "false" ;
VAL_ 2151170048 RtSecTrnIndFld 1 "true" 0 "false" ;
VAL_ 2151170048 TrlrFgLtPrs 1 "true" 0 "false" ;
VAL_ 2151170048 LftSecTrnIndFld 1 "true" 0 "false" ;
VAL_ 2151841792 HtdFrntWSSt 1 "ON" 0 "OFF" ;
VAL_ 2151841792 WSWprAct 1 "true" 0 "false" ;
VAL_ 2151841792 RnSnsOffIO 1 "true" 0 "false" ;
VAL_ 2151841792 RnSnsActIO 1 "true" 0 "false" ;
VAL_ 2151841792 TurnWprIntIO 1 "true" 0 "false" ;
VAL_ 2154995712 HVHtrFldIO 1 "true" 0 "false" ;
VAL_ 2154995712 HVHtrOvrTmpIndOn 1 "true" 0 "false" ;
VAL_ 2154094592 IntDimSeldClrTypStVal 31 "Color Type 30" 30 "Color Type 29" 29 "Color Type 28" 28 "Color Type 27" 27 "Color Type 26" 26 "Color Type 25" 25 "Color Type 24" 24 "Color Type 23" 23 "Color Type 22" 22 "Color Type 21" 21 "Color Type 20" 20 "Color Type 19" 19 "Color Type 18" 18 "Color Type 17" 17 "Color Type 16" 16 "Color Type 15" 15 "Color Type 14" 14 "Color Type 13" 13 "Color Type 12" 12 "Color Type 11" 11 "Color Type 10" 10 "Color Type 9" 9 "Color Type 8" 8 "Color Type 7" 7 "Color Type 6" 6 "Color Type 5" 5 "Color Type 4" 4 "Color Type 3" 3 "Color Type 2" 2 "Color Type 1" 1 "Off" 0 "No Action" ;
VAL_ 2154094592 IntDimSeldAnmTypStVal 15 "Animation Type 14" 14 "Animation Type 13" 13 "Animation Type 12" 12 "Animation Type 11" 11 "Animation Type 10" 10 "Animation Type 9" 9 "Animation Type 8" 8 "Animation Type 7" 7 "Animation Type 6" 6 "Animation Type 5" 5 "Animation Type 4" 4 "Animation Type 3" 3 "Animation Type 2" 2 "Animation Type 1" 1 "Off" 0 "No Action" ;
VAL_ 2154094592 IDCTA_ClrTyp30Avl 1 "true" 0 "false" ;
VAL_ 2154094592 IDCTA_ClrTyp29Avl 1 "true" 0 "false" ;
VAL_ 2154094592 IDCTA_ClrTyp28Avl 1 "true" 0 "false" ;
VAL_ 2154094592 IDCTA_ClrTyp27Avl 1 "true" 0 "false" ;
VAL_ 2154094592 IDCTA_ClrTyp26Avl 1 "true" 0 "false" ;
VAL_ 2154094592 IDCTA_ClrTyp25Avl 1 "true" 0 "false" ;
VAL_ 2154094592 IDCTA_ClrTyp24Avl 1 "true" 0 "false" ;
VAL_ 2154094592 IDCTA_ClrTyp23Avl 1 "true" 0 "false" ;
VAL_ 2154094592 IDCTA_ClrTyp22Avl 1 "true" 0 "false" ;
VAL_ 2154094592 IDCTA_ClrTyp21Avl 1 "true" 0 "false" ;
VAL_ 2154094592 IDCTA_ClrTyp20Avl 1 "true" 0 "false" ;
VAL_ 2154094592 IDCTA_ClrTyp19Avl 1 "true" 0 "false" ;
VAL_ 2154094592 IDCTA_ClrTyp18Avl 1 "true" 0 "false" ;
VAL_ 2154094592 IDCTA_ClrTyp17Avl 1 "true" 0 "false" ;
VAL_ 2154094592 IDCTA_ClrTyp16Avl 1 "true" 0 "false" ;
VAL_ 2154094592 IDCTA_ClrTyp15Avl 1 "true" 0 "false" ;
VAL_ 2154094592 IDCTA_ClrTyp14Avl 1 "true" 0 "false" ;
VAL_ 2154094592 IDCTA_ClrTyp13Avl 1 "true" 0 "false" ;
VAL_ 2154094592 IDCTA_ClrTyp12Avl 1 "true" 0 "false" ;
VAL_ 2154094592 IDCTA_ClrTyp11Avl 1 "true" 0 "false" ;
VAL_ 2154094592 IDCTA_ClrTyp10Avl 1 "true" 0 "false" ;
VAL_ 2154094592 IDCTA_ClrTyp9Avl 1 "true" 0 "false" ;
VAL_ 2154094592 IDCTA_ClrTyp8Avl 1 "true" 0 "false" ;
VAL_ 2154094592 IDCTA_ClrTyp7Avl 1 "true" 0 "false" ;
VAL_ 2154094592 IDCTA_ClrTyp6Avl 1 "true" 0 "false" ;
VAL_ 2154094592 IDCTA_ClrTyp5Avl 1 "true" 0 "false" ;
VAL_ 2154094592 IDCTA_ClrTyp4Avl 1 "true" 0 "false" ;
VAL_ 2154094592 IDCTA_ClrTyp3Avl 1 "true" 0 "false" ;
VAL_ 2154094592 IDCTA_ClrTyp2Avl 1 "true" 0 "false" ;
VAL_ 2154094592 IDCTA_ClrTyp1Avl 1 "true" 0 "false" ;
VAL_ 2154094592 IDCTA_OffAvl 1 "true" 0 "false" ;
VAL_ 2154094592 IDATA_AnmTyp14Avl 1 "true" 0 "false" ;
VAL_ 2154094592 IDATA_AnmTyp13Avl 1 "true" 0 "false" ;
VAL_ 2154094592 IDATA_AnmTyp12Avl 1 "true" 0 "false" ;
VAL_ 2154094592 IDATA_AnmTyp11Avl 1 "true" 0 "false" ;
VAL_ 2154094592 IDATA_AnmTyp10Avl 1 "true" 0 "false" ;
VAL_ 2154094592 IDATA_AnmTyp9Avl 1 "true" 0 "false" ;
VAL_ 2154094592 IDATA_AnmTyp8Avl 1 "true" 0 "false" ;
VAL_ 2154094592 IDATA_AnmTyp7Avl 1 "true" 0 "false" ;
VAL_ 2154094592 IDATA_AnmTyp6Avl 1 "true" 0 "false" ;
VAL_ 2154094592 IDATA_AnmTyp5Avl 1 "true" 0 "false" ;
VAL_ 2154094592 IDATA_AnmTyp4Avl 1 "true" 0 "false" ;
VAL_ 2154094592 IDATA_AnmTyp3Avl 1 "true" 0 "false" ;
VAL_ 2154094592 IDATA_AnmTyp2Avl 1 "true" 0 "false" ;
VAL_ 2154094592 IDATA_AnmTyp1Avl 1 "true" 0 "false" ;
VAL_ 2154094592 IDATA_OffAvl 1 "true" 0 "false" ;
VAL_ 2154094592 AdjPdlMotInhbtd 1 "true" 0 "false" ;
VAL_ 2149711872 SetSpdLmtRchd 3 "Reserved" 2 "Low limit reached" 1 "High limit reached" 0 "No limit reached" ;
VAL_ 2149711872 FOAI_VehAhdIndRq 0 "No Alert" 1 "Alert Level 1" 2 "Alert Level 2" 3 "Alert Level 3" ;
VAL_ 2149711872 FOAI_AlrtWrnIndRq 0 "No Alert" 1 "Alert Level 1" 2 "Alert Level 2" 3 "Alert Level 3" ;
VAL_ 2149711872 FOAI_AlrtChmIhbRq 0 "Allow Chime" 1 "Inhibit Chime" ;
VAL_ 2149711872 FwdClnAlrtOffIO 1 "true" 0 "false" ;
VAL_ 2149711872 FwdClnAlrtPr 1 "true" 0 "false" ;
VAL_ 2149711872 VehDynYawRateV 1 "Invalid" 0 "Valid" ;
VAL_ 2149711872 ACCHdwyStg 7 "Headway Setting 7" 6 "Headway Setting 6" 5 "Headway Setting 5" 4 "Headway Setting 4" 3 "Headway Setting 3" 2 "Headway Setting 2" 1 "Headway Setting 1" 0 "Minimum Headway Setting" ;
VAL_ 2149711872 AdapCrsCntVDA 1 "VirtualDeviceAvailable" 0 "VirtualDeviceUnavailable" ;
VAL_ 2149711872 SpdLmtrSpdWrngEnbld 1 "true" 0 "false" ;
VAL_ 2149711872 CrsCntlDrSelSpdAct 1 "true" 0 "false" ;
VAL_ 2149711872 ACCAct370 1 "true" 0 "false" ;
VAL_ 2149711872 SpdLmtrSpdWrngAct 1 "true" 0 "false" ;
VAL_ 2149711872 AutoMdSpdLmtStat 0 "No Speed Limit Change" 1 "Proposed Speed Limit Change" 2 "Accepted Speed Limit Change" 3 "Declined Speed Limit Change" ;
VAL_ 2149711872 ACCAutoSetSpdStat 0 "No Set Speed Change" 1 "Proposed Speed Limit Change" 2 "Accepted Speed Limit Change" 3 "Declined Speed Limit Change" ;
VAL_ 2153979904 RtPrkLtFld 1 "true" 0 "false" ;
VAL_ 2153979904 RtLwBmFld 1 "true" 0 "false" ;
VAL_ 2153979904 RtDytmRunLmpFld 1 "true" 0 "false" ;
VAL_ 2153979904 RtBrkLtFld 1 "true" 0 "false" ;
VAL_ 2153979904 RRTrnIndLtFld 1 "true" 0 "false" ;
VAL_ 2153979904 RLTrnIndLtFld 1 "true" 0 "false" ;
VAL_ 2153979904 LicPltLtFld 1 "true" 0 "false" ;
VAL_ 2153979904 LftPrkLtFld 1 "true" 0 "false" ;
VAL_ 2153979904 LftLwBmFld 1 "true" 0 "false" ;
VAL_ 2153979904 LftBrkLtFld 1 "true" 0 "false" ;
VAL_ 2153979904 FRTrnIndLtFld 1 "true" 0 "false" ;
VAL_ 2153979904 FLTrnIndLtFld 1 "true" 0 "false" ;
VAL_ 2153979904 CHMSLFld 1 "true" 0 "false" ;
VAL_ 2153979904 LftDytmRunLmpFld 1 "true" 0 "false" ;
VAL_ 2153979904 RvsLtFld 1 "true" 0 "false" ;
VAL_ 2153979904 RFgLtFld 1 "true" 0 "false" ;
VAL_ 2155003904 LftLnChgThrt 1 "true" 0 "false" ;
VAL_ 2155003904 SBZATmpUnvIndOn 1 "true" 0 "false" ;
VAL_ 2155003904 SBZASysSrvIndOn 1 "true" 0 "false" ;
VAL_ 2155003904 SBZASysOffIndOn 1 "true" 0 "false" ;
VAL_ 2155003904 SBZASysClnIndOn 1 "true" 0 "false" ;
VAL_ 2150227968 PhnSpRcgnApSt 3 "Unused" 2 "Audio Prompt Active" 1 "Speech Rec Active" 0 "Inactive" ;
VAL_ 2151497728 TireLFPrsStat 5 "High" 4 "Low - Extended Mobility" 3 "Low" 2 "Low - Service Now" 1 "Nominal" 0 "Unknown" ;
VAL_ 2151497728 TireLFPrsV 1 "Invalid" 0 "Valid" ;
VAL_ 2151497728 TireLRPrsStat 5 "High" 4 "Low - Extended Mobility" 3 "Low" 2 "Low - Service Now" 1 "Nominal" 0 "Unknown" ;
VAL_ 2151497728 TireLRPrsV 1 "Invalid" 0 "Valid" ;
VAL_ 2151497728 TireRFPrsStat 5 "High" 4 "Low - Extended Mobility" 3 "Low" 2 "Low - Service Now" 1 "Nominal" 0 "Unknown" ;
VAL_ 2151497728 TireRFPrsV 1 "Invalid" 0 "Valid" ;
VAL_ 2151497728 TireRRPrsStat 5 "High" 4 "Low - Extended Mobility" 3 "Low" 2 "Low - Service Now" 1 "Nominal" 0 "Unknown" ;
VAL_ 2151497728 TireRRPrsV 1 "Invalid" 0 "Valid" ;
VAL_ 2151219200 RemStrtSt 1 "Active" 0 "Inactive" ;
VAL_ 2151219200 RmVehStrRq 1 "Remote Start Requested" 0 "Remote Start Not Requested" ;
VAL_ 2153775104 DTCI_DTCFaultType 3 "Type C" 2 "Type B" 1 "Type A" 0 "Not Supported" ;
VAL_ 2153775104 DTCI_CodeSupported 1 "true" 0 "false" ;
VAL_ 2153775104 DTCI_CurrentStatus 1 "true" 0 "false" ;
VAL_ 2153775104 DTCI_TstNPsdCdClrdSt 1 "true" 0 "false" ;
VAL_ 2153775104 DTCI_TstFldCdClrdStat 1 "true" 0 "false" ;
VAL_ 2153775104 DTCI_HistStat 1 "true" 0 "false" ;
VAL_ 2153775104 DTCI_TstNPsdPwrUpSt 1 "true" 0 "false" ;
VAL_ 2153775104 DTCI_TstFldPwrUpSt 1 "true" 0 "false" ;
VAL_ 2153775104 DTCI_WrnIndRqdSt 1 "true" 0 "false" ;
VAL_ 2153775104 DTCI_DTCTriggered 1 "true" 0 "false" ;
VAL_ 2153775104 DTCIUnused7 1 "true" 0 "false" ;
VAL_ 2153775104 DTCIUnused6 1 "true" 0 "false" ;
VAL_ 2153775104 DTCIUnused5 1 "true" 0 "false" ;
VAL_ 2153775104 DTCIUnused4 1 "true" 0 "false" ;
VAL_ 2153775104 DTCIUnused3 1 "true" 0 "false" ;
VAL_ 2153775104 DTCIUnused2 1 "true" 0 "false" ;
VAL_ 2153775104 DTCIUnused1 1 "true" 0 "false" ;
SIG_GROUP_ 2158903296 ODIDynDataMltRq_AuxIP 1 : ODDMA_ReqType ODDMA_FUCID ODDMA_DispMID ODDMA_DataID2Vld ODDMA_DataID2 ODDMA_DataID3Vld ODDMA_DataID3 ODDMA_DataID1 ODDMA_DataID4Vld ODDMA_DataID4 ODDMA_DataID5Vld ODDMA_DataID5;
SIG_GROUP_ 2158911488 ODIDynDataMltRq_CntrStck 1 : ODDMC_ReqType ODDMC_DispMID ODDMC_DataID2Vld ODDMC_DataID2 ODDMC_DataID3Vld ODDMC_DataID3 ODDMC_DataID1 ODDMC_DataID4Vld ODDMC_DataID4 ODDMC_DataID5Vld ODDMC_DataID5 ODDMC_FUCID;
SIG_GROUP_ 2158919680 ODIDynDataMltRq_IPC 1 : ODDMI_ReqType ODDMI_FUCID ODDMI_DispMID ODDMI_DataID2Vld ODDMI_DataID2 ODDMI_DataID3Vld ODDMI_DataID3 ODDMI_DataID1 ODDMI_DataID4Vld ODDMI_DataID4 ODDMI_DataID5Vld ODDMI_DataID5;
SIG_GROUP_ 2154094592 IntDimClrTypAvl 1 : IDCTA_ClrTyp30Avl IDCTA_ClrTyp29Avl IDCTA_ClrTyp28Avl IDCTA_ClrTyp27Avl IDCTA_ClrTyp26Avl IDCTA_ClrTyp25Avl IDCTA_ClrTyp24Avl IDCTA_ClrTyp23Avl IDCTA_ClrTyp22Avl IDCTA_ClrTyp21Avl IDCTA_ClrTyp20Avl IDCTA_ClrTyp19Avl IDCTA_ClrTyp18Avl IDCTA_ClrTyp17Avl IDCTA_ClrTyp16Avl IDCTA_ClrTyp15Avl IDCTA_ClrTyp14Avl IDCTA_ClrTyp13Avl IDCTA_ClrTyp12Avl IDCTA_ClrTyp11Avl IDCTA_ClrTyp10Avl IDCTA_ClrTyp9Avl IDCTA_ClrTyp8Avl IDCTA_ClrTyp7Avl IDCTA_ClrTyp6Avl IDCTA_ClrTyp5Avl IDCTA_ClrTyp4Avl IDCTA_ClrTyp3Avl IDCTA_ClrTyp2Avl IDCTA_ClrTyp1Avl IDCTA_OffAvl;
SIG_GROUP_ 2154094592 IntDimAnmTypAvl 1 : IDATA_AnmTyp14Avl IDATA_AnmTyp13Avl IDATA_AnmTyp12Avl IDATA_AnmTyp11Avl IDATA_AnmTyp10Avl IDATA_AnmTyp9Avl IDATA_AnmTyp8Avl IDATA_AnmTyp7Avl IDATA_AnmTyp6Avl IDATA_AnmTyp5Avl IDATA_AnmTyp4Avl IDATA_AnmTyp3Avl IDATA_AnmTyp2Avl IDATA_AnmTyp1Avl IDATA_OffAvl;
SIG_GROUP_ 2149711872 FwdObjAlrtInd 1 : FOAI_VehAhdIndRq FOAI_AlrtWrnIndRq FOAI_AlrtChmIhbRq;
SIG_GROUP_ 2153775104 DTCInfo 1 : DTCI_DTCFaultType DTCI_CodeSupported DTCI_CurrentStatus DTCI_TstNPsdCdClrdSt DTCI_TstFldCdClrdStat DTCI_HistStat DTCI_TstNPsdPwrUpSt DTCI_TstFldPwrUpSt DTCI_WrnIndRqdSt DTCI_DTCFailType DTCI_DTCNumber DTCI_DTCSource DTCI_DTCTriggered DTCIUnused7 DTCIUnused6 DTCIUnused5 DTCIUnused4 DTCIUnused3 DTCIUnused2 DTCIUnused1;
